VERSION ""

NS_ :

BS_ :

BU_ : Vector__XXX

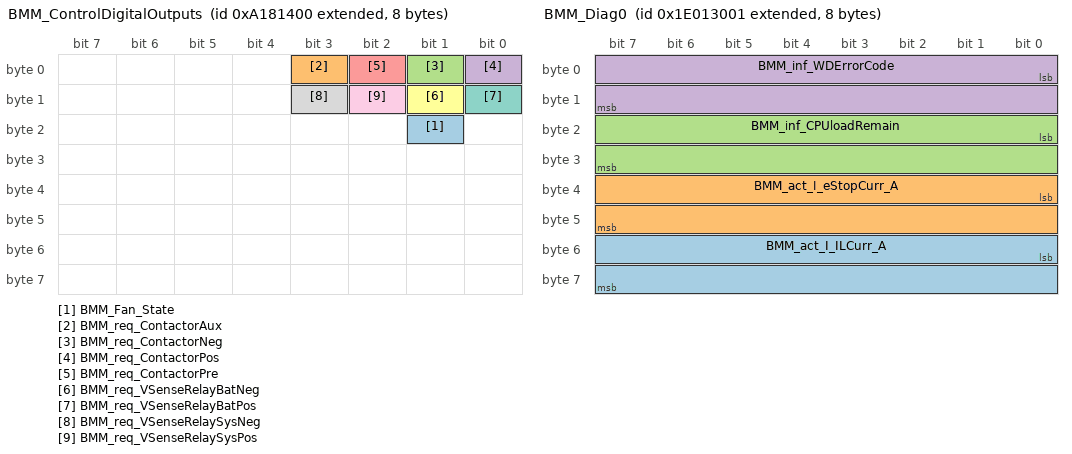
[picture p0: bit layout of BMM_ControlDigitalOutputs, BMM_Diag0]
BO_ 2316833792 BMM_ControlDigitalOutputs: 8 Vector__XXX
  SG_ BMM_Fan_State : 17|1@1+ (1,0) [0|1] "" Vector__XXX
  SG_ BMM_req_ContactorAux : 3|1@1+ (1,0) [0|1] "" Vector__XXX
  SG_ BMM_req_ContactorNeg : 1|1@1+ (1,0) [0|1] "" Vector__XXX
  SG_ BMM_req_ContactorPos : 0|1@1+ (1,0) [0|1] "" Vector__XXX
  SG_ BMM_req_ContactorPre : 2|1@1+ (1,0) [0|1] "" Vector__XXX
  SG_ BMM_req_VSenseRelayBatNeg : 9|1@1+ (1,0) [0|1] "" Vector__XXX
  SG_ BMM_req_VSenseRelayBatPos : 8|1@1+ (1,0) [0|1] "" Vector__XXX
  SG_ BMM_req_VSenseRelaySysNeg : 11|1@1+ (1,0) [0|1] "" Vector__XXX
  SG_ BMM_req_VSenseRelaySysPos : 10|1@1+ (1,0) [0|1] "" Vector__XXX

BO_ 2650877953 BMM_Diag0: 8 Vector__XXX
  SG_ BMM_act_I_ILCurr_A : 48|16@1+ (1,0) [0|65535] "" Vector__XXX
  SG_ BMM_act_I_eStopCurr_A : 32|16@1+ (1,0) [0|65535] "" Vector__XXX
  SG_ BMM_inf_CPUloadRemain : 16|16@1+ (1,0) [0|65535] "" Vector__XXX
  SG_ BMM_inf_WDErrorCode : 0|16@1+ (1,0) [0|65535] "" Vector__XXX

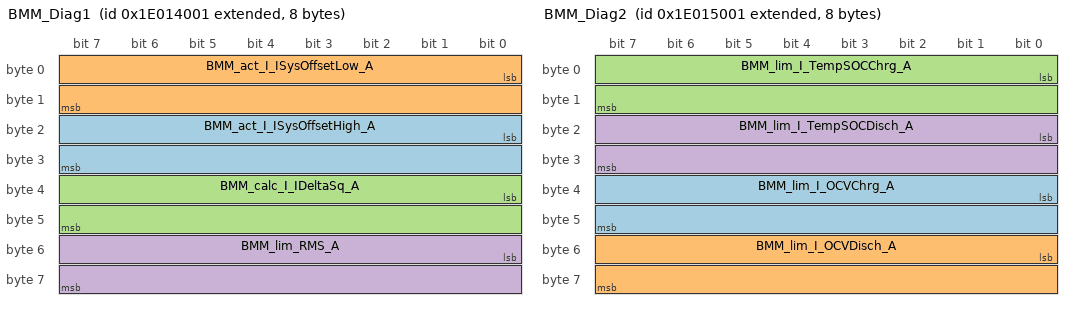
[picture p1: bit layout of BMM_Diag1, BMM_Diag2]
BO_ 2650882049 BMM_Diag1: 8 Vector__XXX
  SG_ BMM_act_I_ISysOffsetHigh_A : 16|16@1+ (0.10000000000000000555,0) [0|6553.5] "" Vector__XXX
  SG_ BMM_act_I_ISysOffsetLow_A : 0|16@1+ (0.10000000000000000555,0) [0|6553.5] "" Vector__XXX
  SG_ BMM_calc_I_IDeltaSq_A : 32|16@1+ (0.10000000000000000555,0) [0|6553.5] "" Vector__XXX
  SG_ BMM_lim_RMS_A : 48|16@1+ (0.10000000000000000555,0) [0|6553.5] "" Vector__XXX

BO_ 2650886145 BMM_Diag2: 8 Vector__XXX
  SG_ BMM_lim_I_OCVChrg_A : 32|16@1+ (0.10000000000000000555,0) [0|6553.5] "" Vector__XXX
  SG_ BMM_lim_I_OCVDisch_A : 48|16@1+ (0.10000000000000000555,0) [0|6553.5] "" Vector__XXX
  SG_ BMM_lim_I_TempSOCChrg_A : 0|16@1+ (0.10000000000000000555,0) [0|6553.5] "" Vector__XXX
  SG_ BMM_lim_I_TempSOCDisch_A : 16|16@1+ (0.10000000000000000555,0) [0|6553.5] "" Vector__XXX

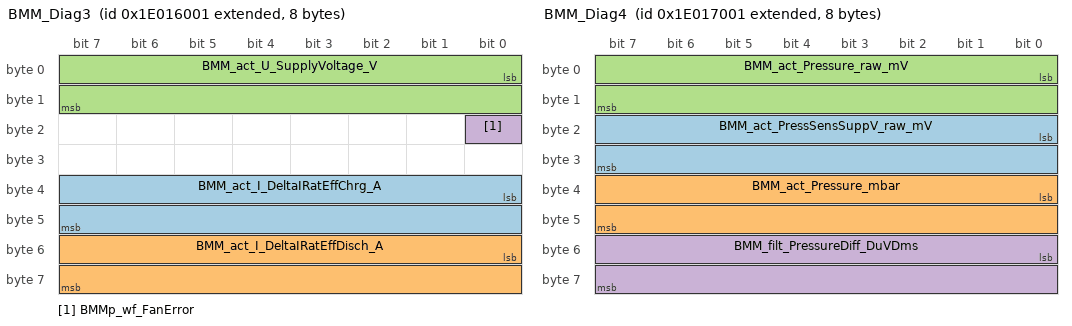
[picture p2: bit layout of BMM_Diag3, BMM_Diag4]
BO_ 2650890241 BMM_Diag3: 8 Vector__XXX
  SG_ BMM_act_I_DeltaIRatEffChrg_A : 32|16@1+ (1,0) [0|65535] "" Vector__XXX
  SG_ BMM_act_I_DeltaIRatEffDisch_A : 48|16@1+ (1,0) [0|65535] "" Vector__XXX
  SG_ BMM_act_U_SupplyVoltage_V : 0|16@1+ (1,0) [0|65535] "" Vector__XXX
  SG_ BMMp_wf_FanError : 16|1@1+ (1,0) [0|1] "" Vector__XXX

BO_ 2650894337 BMM_Diag4: 8 Vector__XXX
  SG_ BMM_act_PressSensSuppV_raw_mV : 16|16@1+ (0.10000000000000000555,0) [0|6553.5] "mV" Vector__XXX
  SG_ BMM_act_Pressure_mbar : 32|16@1+ (1,0) [0|65535] "mbar" Vector__XXX
  SG_ BMM_act_Pressure_raw_mV : 0|16@1+ (0.10000000000000000555,0) [0|6553.5] "mV" Vector__XXX
  SG_ BMM_filt_PressureDiff_DuVDms : 48|16@1- (1,0) [-32768|32767] "uV/ms" Vector__XXX

BO_ 2650898433 BMM_Diag5: 8 Vector__XXX
  SG_ BMM_act_U_KL30SafeVolt_V : 0|16@1+ (0.10000000000000000555,0) [0|6553.5] "V" Vector__XXX

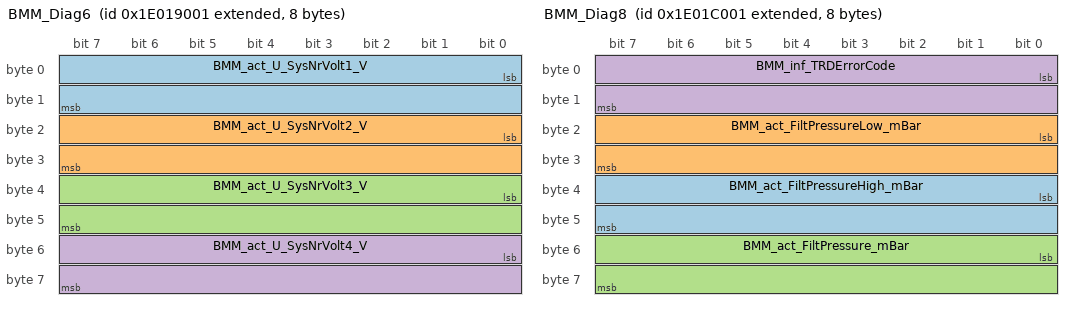
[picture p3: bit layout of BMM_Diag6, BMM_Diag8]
BO_ 2650902529 BMM_Diag6: 8 Vector__XXX
  SG_ BMM_act_U_SysNrVolt1_V : 0|16@1+ (0.10000000000000000555,0) [0|6553.5] "V" Vector__XXX
  SG_ BMM_act_U_SysNrVolt2_V : 16|16@1+ (0.10000000000000000555,0) [0|6553.5] "V" Vector__XXX
  SG_ BMM_act_U_SysNrVolt3_V : 32|16@1+ (0.10000000000000000555,0) [0|6553.5] "V" Vector__XXX
  SG_ BMM_act_U_SysNrVolt4_V : 48|16@1+ (0.10000000000000000555,0) [0|6553.5] "V" Vector__XXX

BO_ 2650906625 BMM_Diag7: 8 Vector__XXX
  SG_ BMM_inf_Average_Core_Load : 0|16@1+ (0.10000000000000000555,0) [0|6553.5] "%" Vector__XXX
  SG_ BMM_inf_Max_Core_Load : 16|16@1+ (0.10000000000000000555,0) [0|6553.5] "%" Vector__XXX

BO_ 2650914817 BMM_Diag8: 8 Vector__XXX
  SG_ BMM_act_FiltPressureHigh_mBar : 32|16@1- (0.10000000000000000555,0) [-3276.8000000000001819|3276.6999999999998181] "mbar" Vector__XXX
  SG_ BMM_act_FiltPressureLow_mBar : 16|16@1- (0.10000000000000000555,0) [-3276.8000000000001819|3276.6999999999998181] "mbar" Vector__XXX
  SG_ BMM_act_FiltPressure_mBar : 48|16@1- (0.10000000000000000555,0) [-3276.8000000000001819|3276.6999999999998181] "mbar" Vector__XXX
  SG_ BMM_inf_TRDErrorCode : 0|16@1+ (1,0) [0|65535] "" Vector__XXX

BO_ 2181563392 BMM_SCUSyncMsg: 0 Vector__XXX

BO_ 2650828801 BMMp_AlarmFlag: 8 Vector__XXX
  SG_ BMMp_af_AfterrunTest : 40|1@1+ (1,0) [0|1] "" Vector__XXX
  SG_ BMMp_af_BMMBattCom : 29|1@1+ (1,0) [0|1] "" Vector__XXX
  SG_ BMMp_af_BoardTemp : 61|1@1+ (1,0) [0|1] "" Vector__XXX
  SG_ BMMp_af_CPUSupplyWarning : 56|1@1+ (1,0) [0|1] "" Vector__XXX
  SG_ BMMp_af_CellTempChargMax : 16|1@1+ (1,0) [0|1] "" Vector__XXX
  SG_ BMMp_af_CellTempChargMin : 17|1@1+ (1,0) [0|1] "" Vector__XXX
  SG_ BMMp_af_CellTempDischMax : 18|1@1+ (1,0) [0|1] "" Vector__XXX
  SG_ BMMp_af_CellTempDischMin : 19|1@1+ (1,0) [0|1] "" Vector__XXX
  SG_ BMMp_af_CellTempUnbalance : 37|1@1+ (1,0) [0|1] "" Vector__XXX
  SG_ BMMp_af_CellVoltUnbalance : 36|1@1+ (1,0) [0|1] "" Vector__XXX
  SG_ BMMp_af_CellVoltageMax : 0|1@1+ (1,0) [0|1] "" Vector__XXX
  SG_ BMMp_af_CellVoltageMin : 1|1@1+ (1,0) [0|1] "" Vector__XXX
  SG_ BMMp_af_ContDam : 51|1@1+ (1,0) [0|1] "" Vector__XXX
  SG_ BMMp_af_ContactorDropOut : 60|1@1+ (1,0) [0|1] "" Vector__XXX
  SG_ BMMp_af_ContactorNegStuck : 10|1@1+ (1,0) [0|1] "" Vector__XXX
  SG_ BMMp_af_ContactorPosStuck : 11|1@1+ (1,0) [0|1] "" Vector__XXX
  SG_ BMMp_af_ContactorWrongState : 49|1@1+ (1,0) [0|1] "" Vector__XXX
  SG_ BMMp_af_CrossCheck : 41|1@1+ (1,0) [0|1] "" Vector__XXX
  SG_ BMMp_af_CurrSens : 50|1@1+ (1,0) [0|1] "" Vector__XXX
  SG_ BMMp_af_DeepDischProt : 32|1@1+ (1,0) [0|1] "" Vector__XXX
  SG_ BMMp_af_Dew_Sensor : 59|1@1+ (1,0) [0|1] "" Vector__XXX
  SG_ BMMp_af_ExtCommunicationTout : 34|1@1+ (1,0) [0|1] "" Vector__XXX
  SG_ BMMp_af_FlashEEPROM : 47|1@1+ (1,0) [0|1] "" Vector__XXX
  SG_ BMMp_af_HVCurrLoopMax : 22|1@1+ (1,0) [0|1] "" Vector__XXX
  SG_ BMMp_af_HVCurrLoopMin : 23|1@1+ (1,0) [0|1] "" Vector__XXX
  SG_ BMMp_af_InvalidData : 48|1@1+ (1,0) [0|1] "" Vector__XXX
  SG_ BMMp_af_IsoFaultBattNeg : 8|1@1+ (1,0) [0|1] "" Vector__XXX
  SG_ BMMp_af_IsoFaultBattPos : 9|1@1+ (1,0) [0|1] "" Vector__XXX
  SG_ BMMp_af_KL30SafeMax : 54|1@1+ (1,0) [0|1] "" Vector__XXX
  SG_ BMMp_af_KL30SafeMin : 55|1@1+ (1,0) [0|1] "" Vector__XXX
  SG_ BMMp_af_KL30SafeOff : 58|1@1+ (1,0) [0|1] "" Vector__XXX
  SG_ BMMp_af_LTCError : 39|1@1+ (1,0) [0|1] "" Vector__XXX
  SG_ BMMp_af_LVSupplyMax : 12|1@1+ (1,0) [0|1] "" Vector__XXX
  SG_ BMMp_af_LVSupplyMin : 13|1@1+ (1,0) [0|1] "" Vector__XXX
  SG_ BMMp_af_ModVoltageRefMax : 6|1@1+ (1,0) [0|1] "" Vector__XXX
  SG_ BMMp_af_ModVoltageSum : 5|1@1+ (1,0) [0|1] "" Vector__XXX
  SG_ BMMp_af_Mod_Voltage_Ref_Min : 7|1@1+ (1,0) [0|1] "" Vector__XXX
  SG_ BMMp_af_NoAfterrunTest : 35|1@1+ (1,0) [0|1] "" Vector__XXX
  SG_ BMMp_af_PowerProtectionWarning : 57|1@1+ (1,0) [0|1] "" Vector__XXX
  SG_ BMMp_af_ProgProcess : 44|1@1+ (1,0) [0|1] "" Vector__XXX
  SG_ BMMp_af_RAM : 45|1@1+ (1,0) [0|1] "" Vector__XXX
  SG_ BMMp_af_ROM : 46|1@1+ (1,0) [0|1] "" Vector__XXX
  SG_ BMMp_af_RefVoltErrorMax : 52|1@1+ (1,0) [0|1] "" Vector__XXX
  SG_ BMMp_af_RefVoltErrorMin : 53|1@1+ (1,0) [0|1] "" Vector__XXX
  SG_ BMMp_af_SCUConfig : 31|1@1+ (1,0) [0|1] "" Vector__XXX
  SG_ BMMp_af_SCUError : 63|1@1+ (1,0) [0|1] "" Vector__XXX
  SG_ BMMp_af_StuckAtTemp : 42|1@1+ (1,0) [0|1] "" Vector__XXX
  SG_ BMMp_af_StuckAtVolt : 43|1@1+ (1,0) [0|1] "" Vector__XXX
  SG_ BMMp_af_SysCurCha : 20|1@1+ (1,0) [0|1] "" Vector__XXX
  SG_ BMMp_af_SysCurDis : 21|1@1+ (1,0) [0|1] "" Vector__XXX
  SG_ BMMp_af_SysCurLimitCha : 26|1@1+ (1,0) [0|1] "" Vector__XXX
  SG_ BMMp_af_SysCurLimitDis : 27|1@1+ (1,0) [0|1] "" Vector__XXX
  SG_ BMMp_af_SysInitTimeout : 30|1@1+ (1,0) [0|1] "" Vector__XXX
  SG_ BMMp_af_SysPrechargeFailed : 28|1@1+ (1,0) [0|1] "" Vector__XXX
  SG_ BMMp_af_SysVoltageMax : 2|1@1+ (1,0) [0|1] "" Vector__XXX
  SG_ BMMp_af_SysVoltageMin : 3|1@1+ (1,0) [0|1] "" Vector__XXX
  SG_ BMMp_af_SysVoltageSum : 4|1@1+ (1,0) [0|1] "" Vector__XXX
  SG_ BMMp_af_TerminalTempMax : 14|1@1+ (1,0) [0|1] "" Vector__XXX
  SG_ BMMp_af_TerminalTempMin : 15|1@1+ (1,0) [0|1] "" Vector__XXX
  SG_ BMMp_af_TerminalTempUnbalance : 38|1@1+ (1,0) [0|1] "" Vector__XXX
  SG_ BMMp_af_WDReset : 33|1@1+ (1,0) [0|1] "" Vector__XXX
  SG_ BMMp_af_eStopCurrLoopMax : 24|1@1+ (1,0) [0|1] "" Vector__XXX
  SG_ BMMp_af_eStopCurrLoopMin : 25|1@1+ (1,0) [0|1] "" Vector__XXX

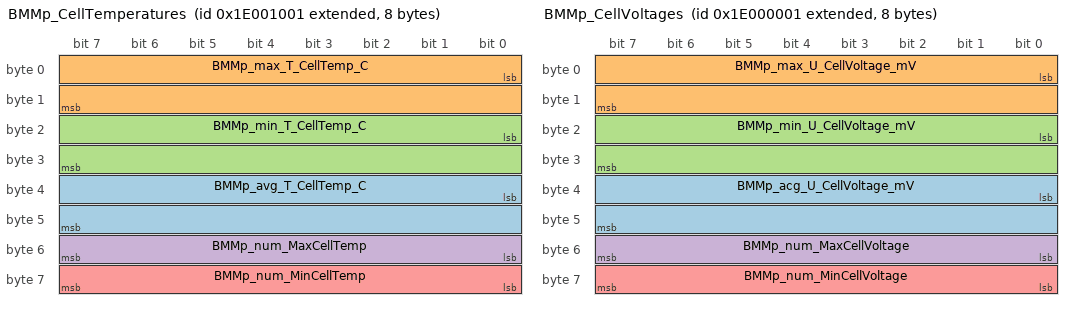
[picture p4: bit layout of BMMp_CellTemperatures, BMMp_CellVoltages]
BO_ 2650804225 BMMp_CellTemperatures: 8 Vector__XXX
  SG_ BMMp_avg_T_CellTemp_C : 32|16@1- (0.10000000000000000555,0) [-3276.8000000000001819|3276.6999999999998181] "°C" Vector__XXX
  SG_ BMMp_max_T_CellTemp_C : 0|16@1- (0.10000000000000000555,0) [-3276.8000000000001819|3276.6999999999998181] "°C" Vector__XXX
  SG_ BMMp_min_T_CellTemp_C : 16|16@1- (0.10000000000000000555,0) [-3276.8000000000001819|3276.6999999999998181] "°C" Vector__XXX
  SG_ BMMp_num_MaxCellTemp : 48|8@1+ (1,0) [0|255] "-" Vector__XXX
  SG_ BMMp_num_MinCellTemp : 56|8@1+ (1,0) [0|255] "-" Vector__XXX

BO_ 2650800129 BMMp_CellVoltages: 8 Vector__XXX
  SG_ BMMp_acg_U_CellVoltage_mV : 32|16@1+ (1,0) [0|65535] "mV" Vector__XXX
  SG_ BMMp_max_U_CellVoltage_mV : 0|16@1+ (1,0) [0|65535] "mV" Vector__XXX
  SG_ BMMp_min_U_CellVoltage_mV : 16|16@1+ (1,0) [0|65535] "mV" Vector__XXX
  SG_ BMMp_num_MaxCellVoltage : 48|8@1+ (1,0) [0|255] "-" Vector__XXX
  SG_ BMMp_num_MinCellVoltage : 56|8@1+ (1,0) [0|255] "-" Vector__XXX

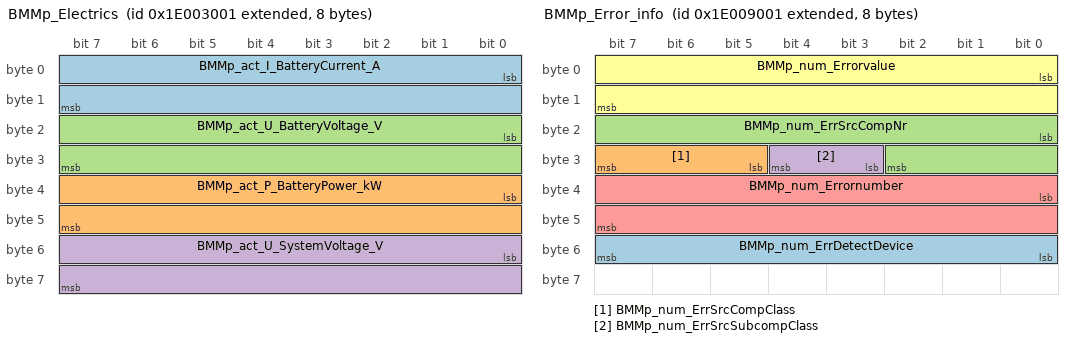
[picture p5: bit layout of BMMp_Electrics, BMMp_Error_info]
BO_ 2650812417 BMMp_Electrics: 8 Vector__XXX
  SG_ BMMp_act_I_BatteryCurrent_A : 0|16@1- (0.10000000000000000555,0) [-3276.8000000000001819|3276.6999999999998181] "A" Vector__XXX
  SG_ BMMp_act_P_BatteryPower_kW : 32|16@1- (0.10000000000000000555,0) [-3276.8000000000001819|3276.6999999999998181] "kW" Vector__XXX
  SG_ BMMp_act_U_BatteryVoltage_V : 16|16@1- (0.10000000000000000555,0) [-3276.8000000000001819|3276.6999999999998181] "V" Vector__XXX
  SG_ BMMp_act_U_SystemVoltage_V : 48|16@1- (0.10000000000000000555,0) [-3276.8000000000001819|3276.6999999999998181] "V" Vector__XXX

BO_ 2650824705 BMMp_ErrorFlag: 8 Vector__XXX
  SG_ BMMp_ef_AfterrunTest : 40|1@1+ (1,0) [0|1] "" Vector__XXX
  SG_ BMMp_ef_BMMBattCom : 29|1@1+ (1,0) [0|1] "" Vector__XXX
  SG_ BMMp_ef_BoardTemp : 61|1@1+ (1,0) [0|1] "" Vector__XXX
  SG_ BMMp_ef_CPUSupplyWarning : 56|1@1+ (1,0) [0|1] "" Vector__XXX
  SG_ BMMp_ef_CellTempChargMax : 16|1@1+ (1,0) [0|1] "" Vector__XXX
  SG_ BMMp_ef_CellTempChargMin : 17|1@1+ (1,0) [0|1] "" Vector__XXX
  SG_ BMMp_ef_CellTempDischMax : 18|1@1+ (1,0) [0|1] "" Vector__XXX
  SG_ BMMp_ef_CellTempDischMin : 19|1@1+ (1,0) [0|1] "" Vector__XXX
  SG_ BMMp_ef_CellTempUnbalance : 37|1@1+ (1,0) [0|1] "" Vector__XXX
  SG_ BMMp_ef_CellVoltUnbalance : 36|1@1+ (1,0) [0|1] "" Vector__XXX
  SG_ BMMp_ef_CellVoltageMax : 0|1@1+ (1,0) [0|1] "" Vector__XXX
  SG_ BMMp_ef_CellVoltageMin : 1|1@1+ (1,0) [0|1] "" Vector__XXX
  SG_ BMMp_ef_ContDam : 51|1@1+ (1,0) [0|1] "" Vector__XXX
  SG_ BMMp_ef_ContactorDropOut : 60|1@1+ (1,0) [0|1] "" Vector__XXX
  SG_ BMMp_ef_ContactorNegStuck : 10|1@1+ (1,0) [0|1] "" Vector__XXX
  SG_ BMMp_ef_ContactorPosStuck : 11|1@1+ (1,0) [0|1] "" Vector__XXX
  SG_ BMMp_ef_ContactorWrongState : 49|1@1+ (1,0) [0|1] "" Vector__XXX
  SG_ BMMp_ef_CrossCheck : 41|1@1+ (1,0) [0|1] "" Vector__XXX
  SG_ BMMp_ef_CurrSens : 50|1@1+ (1,0) [0|1] "" Vector__XXX
  SG_ BMMp_ef_DeepDischProt : 32|1@1+ (1,0) [0|1] "" Vector__XXX
  SG_ BMMp_ef_Dew_Sensor : 59|1@1+ (1,0) [0|1] "" Vector__XXX
  SG_ BMMp_ef_ExtCommunicationTout : 34|1@1+ (1,0) [0|1] "" Vector__XXX
  SG_ BMMp_ef_FlashEEPROM : 47|1@1+ (1,0) [0|1] "" Vector__XXX
  SG_ BMMp_ef_HVCurrLoopMax : 22|1@1+ (1,0) [0|1] "" Vector__XXX
  SG_ BMMp_ef_HVCurrLoopMin : 23|1@1+ (1,0) [0|1] "" Vector__XXX
  SG_ BMMp_ef_InvalidData : 48|1@1+ (1,0) [0|1] "" Vector__XXX
  SG_ BMMp_ef_IsoFaultBattNeg : 8|1@1+ (1,0) [0|1] "" Vector__XXX
  SG_ BMMp_ef_IsoFaultBattPos : 9|1@1+ (1,0) [0|1] "" Vector__XXX
  SG_ BMMp_ef_KL30SafeMax : 54|1@1+ (1,0) [0|1] "" Vector__XXX
  SG_ BMMp_ef_KL30SafeMin : 55|1@1+ (1,0) [0|1] "" Vector__XXX
  SG_ BMMp_ef_KL30SafeOff : 58|1@1+ (1,0) [0|1] "" Vector__XXX
  SG_ BMMp_ef_LTCError : 39|1@1+ (1,0) [0|1] "" Vector__XXX
  SG_ BMMp_ef_LVSupplyMax : 12|1@1+ (1,0) [0|1] "" Vector__XXX
  SG_ BMMp_ef_LVSupplyMin : 13|1@1+ (1,0) [0|1] "" Vector__XXX
  SG_ BMMp_ef_ModVoltageRefMax : 6|1@1+ (1,0) [0|1] "" Vector__XXX
  SG_ BMMp_ef_ModVoltageSum : 5|1@1+ (1,0) [0|1] "" Vector__XXX
  SG_ BMMp_ef_Mod_Voltage_Ref_Min : 7|1@1+ (1,0) [0|1] "" Vector__XXX
  SG_ BMMp_ef_NoAfterrunTest : 35|1@1+ (1,0) [0|1] "" Vector__XXX
  SG_ BMMp_ef_PowerProtectionWarning : 57|1@1+ (1,0) [0|1] "" Vector__XXX
  SG_ BMMp_ef_ProgProcess : 44|1@1+ (1,0) [0|1] "" Vector__XXX
  SG_ BMMp_ef_RAM : 45|1@1+ (1,0) [0|1] "" Vector__XXX
  SG_ BMMp_ef_ROM : 46|1@1+ (1,0) [0|1] "" Vector__XXX
  SG_ BMMp_ef_RefVoltErrorMax : 52|1@1+ (1,0) [0|1] "" Vector__XXX
  SG_ BMMp_ef_RefVoltErrorMin : 53|1@1+ (1,0) [0|1] "" Vector__XXX
  SG_ BMMp_ef_SCUConfig : 31|1@1+ (1,0) [0|1] "" Vector__XXX
  SG_ BMMp_ef_SCUError : 63|1@1+ (1,0) [0|1] "" Vector__XXX
  SG_ BMMp_ef_StuckAtTemp : 42|1@1+ (1,0) [0|1] "" Vector__XXX
  SG_ BMMp_ef_StuckAtVolt : 43|1@1+ (1,0) [0|1] "" Vector__XXX
  SG_ BMMp_ef_SysCurCha : 20|1@1+ (1,0) [0|1] "" Vector__XXX
  SG_ BMMp_ef_SysCurDis : 21|1@1+ (1,0) [0|1] "" Vector__XXX
  SG_ BMMp_ef_SysCurLimitCha : 26|1@1+ (1,0) [0|1] "" Vector__XXX
  SG_ BMMp_ef_SysCurLimitDis : 27|1@1+ (1,0) [0|1] "" Vector__XXX
  SG_ BMMp_ef_SysInitTimeout : 30|1@1+ (1,0) [0|1] "" Vector__XXX
  SG_ BMMp_ef_SysPrechargeFailed : 28|1@1+ (1,0) [0|1] "" Vector__XXX
  SG_ BMMp_ef_SysVoltageMax : 2|1@1+ (1,0) [0|1] "" Vector__XXX
  SG_ BMMp_ef_SysVoltageMin : 3|1@1+ (1,0) [0|1] "" Vector__XXX
  SG_ BMMp_ef_SysVoltageSum : 4|1@1+ (1,0) [0|1] "" Vector__XXX
  SG_ BMMp_ef_TerminalTempMax : 14|1@1+ (1,0) [0|1] "" Vector__XXX
  SG_ BMMp_ef_TerminalTempMin : 15|1@1+ (1,0) [0|1] "" Vector__XXX
  SG_ BMMp_ef_TerminalTempUnbalance : 38|1@1+ (1,0) [0|1] "" Vector__XXX
  SG_ BMMp_ef_WDReset : 33|1@1+ (1,0) [0|1] "" Vector__XXX
  SG_ BMMp_ef_eStopCurrLoopMax : 24|1@1+ (1,0) [0|1] "" Vector__XXX
  SG_ BMMp_ef_eStopCurrLoopMin : 25|1@1+ (1,0) [0|1] "" Vector__XXX

BO_ 2650836993 BMMp_Error_info: 8 Vector__XXX
  SG_ BMMp_num_ErrDetectDevice : 48|8@1+ (1,0) [0|255] "" Vector__XXX
  SG_ BMMp_num_ErrSrcCompClass : 29|3@1+ (1,0) [0|7] "" Vector__XXX
  SG_ BMMp_num_ErrSrcCompNr : 16|11@1+ (1,0) [0|2047] "" Vector__XXX
  SG_ BMMp_num_ErrSrcSubcompClass : 27|2@1+ (1,0) [0|3] "" Vector__XXX
  SG_ BMMp_num_Errornumber : 32|16@1+ (1,0) [0|65535] "" Vector__XXX
  SG_ BMMp_num_Errorvalue : 0|16@1- (1,0) [-32768|32767] "" Vector__XXX

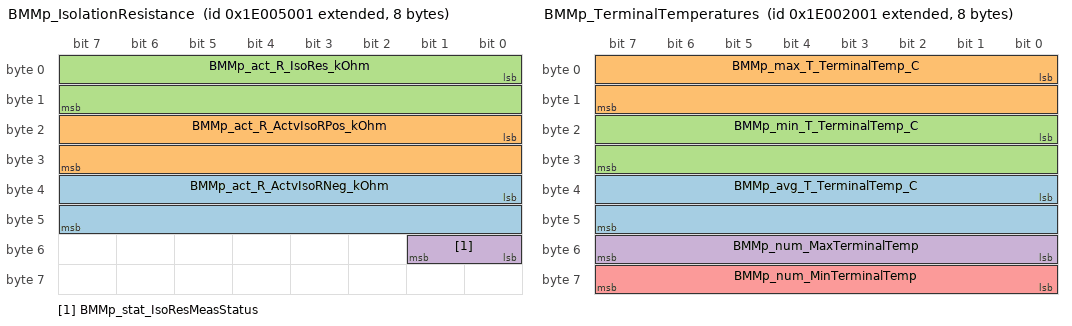
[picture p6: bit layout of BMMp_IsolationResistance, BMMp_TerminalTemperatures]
BO_ 2650820609 BMMp_IsolationResistance: 8 Vector__XXX
  SG_ BMMp_act_R_ActvIsoRNeg_kOhm : 32|16@1+ (1,0) [0|65535] "kOhm" Vector__XXX
  SG_ BMMp_act_R_ActvIsoRPos_kOhm : 16|16@1+ (1,0) [0|65535] "kOhm" Vector__XXX
  SG_ BMMp_act_R_IsoRes_kOhm : 0|16@1+ (1,0) [0|65535] "kOhm" Vector__XXX
  SG_ BMMp_stat_IsoResMeasStatus : 48|2@1+ (1,0) [0|3] "" Vector__XXX

BO_ 2650857473 BMMp_SOH: 8 Vector__XXX
  SG_ BMMp_calc_SOHcapacity_pct : 0|16@1+ (0.10000000000000000555,0) [0|6553.5] "%" Vector__XXX
  SG_ BMMp_calc_SOHimpedance_pct : 16|16@1+ (0.10000000000000000555,0) [0|6553.5] "%" Vector__XXX

BO_ 2650816513 BMMp_State: 8 Vector__XXX
  SG_ BMMp_cnt_AliveCounter : 48|8@1+ (1,0) [0|255] "" Vector__XXX
  SG_ BMMp_cnt_MirroredAliveCounter : 56|8@1+ (1,0) [0|255] "" Vector__XXX
  SG_ BMMp_flag_Alarm : 33|1@1+ (1,0) [0|1] "" Vector__XXX
  SG_ BMMp_flag_AuxCont : 34|1@1+ (1,0) [0|1] "" Vector__XXX
  SG_ BMMp_flag_Charge : 9|1@1+ (1,0) [0|1] "" Vector__XXX
  SG_ BMMp_flag_ChargeComplete : 22|1@1+ (1,0) [0|1] "" Vector__XXX
  SG_ BMMp_flag_ContactorHVNeg : 20|1@1+ (1,0) [0|1] "" Vector__XXX
  SG_ BMMp_flag_ContactorHVPos : 19|1@1+ (1,0) [0|1] "" Vector__XXX
  SG_ BMMp_flag_ContactorPrecha : 21|1@1+ (1,0) [0|1] "" Vector__XXX
  SG_ BMMp_flag_Drive : 8|1@1+ (1,0) [0|1] "" Vector__XXX
  SG_ BMMp_flag_ExternalSdwnRq : 23|1@1+ (1,0) [0|1] "" Vector__XXX
  SG_ BMMp_flag_FireRisk : 39|1@1+ (1,0) [0|1] "" Vector__XXX
  SG_ BMMp_flag_HVILState : 30|1@1+ (1,0) [0|1] "" Vector__XXX
  SG_ BMMp_flag_InternalKL30Safe : 24|1@1+ (1,0) [0|1] "" Vector__XXX
  SG_ BMMp_flag_IsoDisable : 17|1@1+ (1,0) [0|1] "" Vector__XXX
  SG_ BMMp_flag_Wake : 16|1@1+ (1,0) [0|1] "" Vector__XXX
  SG_ BMMp_flag_Warning : 32|1@1+ (1,0) [0|1] "" Vector__XXX
  SG_ BMMp_flag_eStopLoopClosed : 31|1@1+ (1,0) [0|1] "" Vector__XXX
  SG_ BMMp_stat_Error : 6|1@1+ (1,0) [0|1] "" Vector__XXX
  SG_ BMMp_stat_Init : 0|1@1+ (1,0) [0|1] "" Vector__XXX
  SG_ BMMp_stat_Operational : 3|1@1+ (1,0) [0|1] "" Vector__XXX
  SG_ BMMp_stat_Precharge : 2|1@1+ (1,0) [0|1] "" Vector__XXX
  SG_ BMMp_stat_Standby : 1|1@1+ (1,0) [0|1] "" Vector__XXX

BO_ 2650808321 BMMp_TerminalTemperatures: 8 Vector__XXX
  SG_ BMMp_avg_T_TerminalTemp_C : 32|16@1- (0.10000000000000000555,0) [-3276.8000000000001819|3276.6999999999998181] "°C" Vector__XXX
  SG_ BMMp_max_T_TerminalTemp_C : 0|16@1- (0.10000000000000000555,0) [-3276.8000000000001819|3276.6999999999998181] "°C" Vector__XXX
  SG_ BMMp_min_T_TerminalTemp_C : 16|16@1- (0.10000000000000000555,0) [-3276.8000000000001819|3276.6999999999998181] "°C" Vector__XXX
  SG_ BMMp_num_MaxTerminalTemp : 48|8@1+ (1,0) [0|255] "-" Vector__XXX
  SG_ BMMp_num_MinTerminalTemp : 56|8@1+ (1,0) [0|255] "-" Vector__XXX

BO_ 2650832897 BMMp_WarningFlag: 8 Vector__XXX
  SG_ BMMp_wf_AfterrunTest : 40|1@1+ (1,0) [0|1] "" Vector__XXX
  SG_ BMMp_wf_BMMBattCom : 29|1@1+ (1,0) [0|1] "" Vector__XXX
  SG_ BMMp_wf_BoardTemp : 61|1@1+ (1,0) [0|1] "" Vector__XXX
  SG_ BMMp_wf_CPUSupplyWarning : 56|1@1+ (1,0) [0|1] "" Vector__XXX
  SG_ BMMp_wf_CellTempChargMax : 16|1@1+ (1,0) [0|1] "" Vector__XXX
  SG_ BMMp_wf_CellTempChargMin : 17|1@1+ (1,0) [0|1] "" Vector__XXX
  SG_ BMMp_wf_CellTempDischMax : 18|1@1+ (1,0) [0|1] "" Vector__XXX
  SG_ BMMp_wf_CellTempDischMin : 19|1@1+ (1,0) [0|1] "" Vector__XXX
  SG_ BMMp_wf_CellTempUnbalance : 37|1@1+ (1,0) [0|1] "" Vector__XXX
  SG_ BMMp_wf_CellVoltUnbalance : 36|1@1+ (1,0) [0|1] "" Vector__XXX
  SG_ BMMp_wf_CellVoltageMax : 0|1@1+ (1,0) [0|1] "" Vector__XXX
  SG_ BMMp_wf_CellVoltageMin : 1|1@1+ (1,0) [0|1] "" Vector__XXX
  SG_ BMMp_wf_ContDam : 51|1@1+ (1,0) [0|1] "" Vector__XXX
  SG_ BMMp_wf_ContactorDropOut : 60|1@1+ (1,0) [0|1] "" Vector__XXX
  SG_ BMMp_wf_ContactorNegStuck : 10|1@1+ (1,0) [0|1] "" Vector__XXX
  SG_ BMMp_wf_ContactorPosStuck : 11|1@1+ (1,0) [0|1] "" Vector__XXX
  SG_ BMMp_wf_ContactorWrongState : 49|1@1+ (1,0) [0|1] "" Vector__XXX
  SG_ BMMp_wf_CrossCheck : 41|1@1+ (1,0) [0|1] "" Vector__XXX
  SG_ BMMp_wf_CurrSens : 50|1@1+ (1,0) [0|1] "" Vector__XXX
  SG_ BMMp_wf_DeepDischProt : 32|1@1+ (1,0) [0|1] "" Vector__XXX
  SG_ BMMp_wf_Dew_Sensor : 59|1@1+ (1,0) [0|1] "" Vector__XXX
  SG_ BMMp_wf_ExtCommunicationTout : 34|1@1+ (1,0) [0|1] "" Vector__XXX
  SG_ BMMp_wf_FlashEEPROM : 47|1@1+ (1,0) [0|1] "" Vector__XXX
  SG_ BMMp_wf_HVCurrLoopMax : 22|1@1+ (1,0) [0|1] "" Vector__XXX
  SG_ BMMp_wf_HVCurrLoopMin : 23|1@1+ (1,0) [0|1] "" Vector__XXX
  SG_ BMMp_wf_InvalidData : 48|1@1+ (1,0) [0|1] "" Vector__XXX
  SG_ BMMp_wf_IsoFaultBattNeg : 8|1@1+ (1,0) [0|1] "" Vector__XXX
  SG_ BMMp_wf_IsoFaultBattPos : 9|1@1+ (1,0) [0|1] "" Vector__XXX
  SG_ BMMp_wf_KL30SafeMax : 54|1@1+ (1,0) [0|1] "" Vector__XXX
  SG_ BMMp_wf_KL30SafeMin : 55|1@1+ (1,0) [0|1] "" Vector__XXX
  SG_ BMMp_wf_KL30SafeOff : 58|1@1+ (1,0) [0|1] "" Vector__XXX
  SG_ BMMp_wf_LTCError : 39|1@1+ (1,0) [0|1] "" Vector__XXX
  SG_ BMMp_wf_LVSupplyMax : 12|1@1+ (1,0) [0|1] "" Vector__XXX
  SG_ BMMp_wf_LVSupplyMin : 13|1@1+ (1,0) [0|1] "" Vector__XXX
  SG_ BMMp_wf_ModVoltageRefMax : 6|1@1+ (1,0) [0|1] "" Vector__XXX
  SG_ BMMp_wf_ModVoltageSum : 5|1@1+ (1,0) [0|1] "" Vector__XXX
  SG_ BMMp_wf_Mod_Voltage_Ref_Min : 7|1@1+ (1,0) [0|1] "" Vector__XXX
  SG_ BMMp_wf_NoAfterrunTest : 35|1@1+ (1,0) [0|1] "" Vector__XXX
  SG_ BMMp_wf_PowerProtectionWarning : 57|1@1+ (1,0) [0|1] "" Vector__XXX
  SG_ BMMp_wf_ProgProcess : 44|1@1+ (1,0) [0|1] "" Vector__XXX
  SG_ BMMp_wf_RAM : 45|1@1+ (1,0) [0|1] "" Vector__XXX
  SG_ BMMp_wf_ROM : 46|1@1+ (1,0) [0|1] "" Vector__XXX
  SG_ BMMp_wf_RefVoltErrorMax : 52|1@1+ (1,0) [0|1] "" Vector__XXX
  SG_ BMMp_wf_RefVoltErrorMin : 53|1@1+ (1,0) [0|1] "" Vector__XXX
  SG_ BMMp_wf_SCUConfig : 31|1@1+ (1,0) [0|1] "" Vector__XXX
  SG_ BMMp_wf_SCUError : 63|1@1+ (1,0) [0|1] "" Vector__XXX
  SG_ BMMp_wf_StuckAtTemp : 42|1@1+ (1,0) [0|1] "" Vector__XXX
  SG_ BMMp_wf_StuckAtVolt : 43|1@1+ (1,0) [0|1] "" Vector__XXX
  SG_ BMMp_wf_SysCurCha : 20|1@1+ (1,0) [0|1] "" Vector__XXX
  SG_ BMMp_wf_SysCurDis : 21|1@1+ (1,0) [0|1] "" Vector__XXX
  SG_ BMMp_wf_SysCurLimitCha : 26|1@1+ (1,0) [0|1] "" Vector__XXX
  SG_ BMMp_wf_SysCurLimitDis : 27|1@1+ (1,0) [0|1] "" Vector__XXX
  SG_ BMMp_wf_SysInitTimeout : 30|1@1+ (1,0) [0|1] "" Vector__XXX
  SG_ BMMp_wf_SysPrechargeFailed : 28|1@1+ (1,0) [0|1] "" Vector__XXX
  SG_ BMMp_wf_SysVoltageMax : 2|1@1+ (1,0) [0|1] "" Vector__XXX
  SG_ BMMp_wf_SysVoltageMin : 3|1@1+ (1,0) [0|1] "" Vector__XXX
  SG_ BMMp_wf_SysVoltageSum : 4|1@1+ (1,0) [0|1] "" Vector__XXX
  SG_ BMMp_wf_TerminalTempMax : 14|1@1+ (1,0) [0|1] "" Vector__XXX
  SG_ BMMp_wf_TerminalTempMin : 15|1@1+ (1,0) [0|1] "" Vector__XXX
  SG_ BMMp_wf_TerminalTempUnbalance : 38|1@1+ (1,0) [0|1] "" Vector__XXX
  SG_ BMMp_wf_WDReset : 33|1@1+ (1,0) [0|1] "" Vector__XXX
  SG_ BMMp_wf_eStopCurrLoopMax : 24|1@1+ (1,0) [0|1] "" Vector__XXX
  SG_ BMMp_wf_eStopCurrLoopMin : 25|1@1+ (1,0) [0|1] "" Vector__XXX

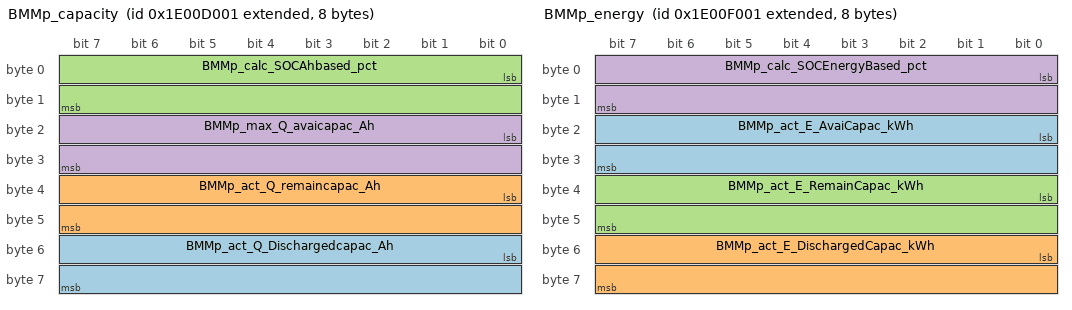
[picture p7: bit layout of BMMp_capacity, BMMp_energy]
BO_ 2650853377 BMMp_capacity: 8 Vector__XXX
  SG_ BMMp_act_Q_Dischargedcapac_Ah : 48|16@1+ (0.10000000000000000555,0) [0|6553.5] "Ah" Vector__XXX
  SG_ BMMp_act_Q_remaincapac_Ah : 32|16@1- (0.10000000000000000555,0) [-3276.8000000000001819|3276.6999999999998181] "Ah" Vector__XXX
  SG_ BMMp_calc_SOCAhbased_pct : 0|16@1+ (0.002500000000000000052,0) [0|163.83750000000000568] "%" Vector__XXX
  SG_ BMMp_max_Q_avaicapac_Ah : 16|16@1+ (0.10000000000000000555,0) [0|6553.5] "Ah" Vector__XXX

BO_ 2650861569 BMMp_energy: 8 Vector__XXX
  SG_ BMMp_act_E_AvaiCapac_kWh : 16|16@1+ (0.10000000000000000555,0) [0|6553.5] "kWh" Vector__XXX
  SG_ BMMp_act_E_DischargedCapac_kWh : 48|16@1+ (0.5,0) [0|32767.5] "kWh" Vector__XXX
  SG_ BMMp_act_E_RemainCapac_kWh : 32|16@1- (0.10000000000000000555,0) [-3276.8000000000001819|3276.6999999999998181] "kWh" Vector__XXX
  SG_ BMMp_calc_SOCEnergyBased_pct : 0|16@1+ (0.002500000000000000052,0) [0|163.83750000000000568] "%" Vector__XXX

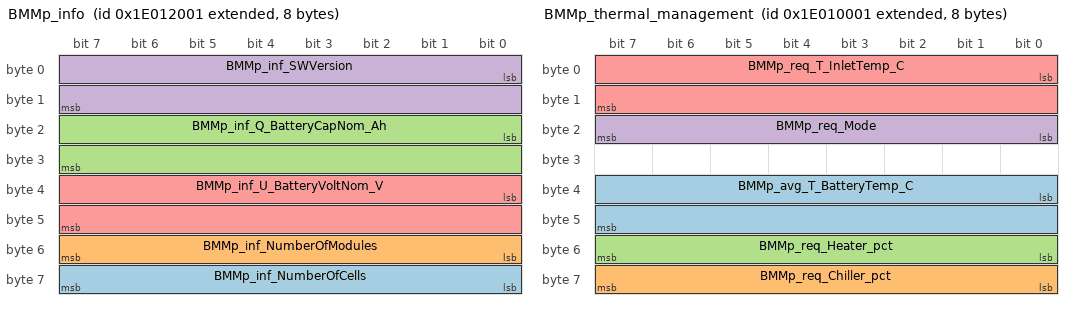
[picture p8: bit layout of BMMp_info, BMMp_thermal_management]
BO_ 2650873857 BMMp_info: 8 Vector__XXX
  SG_ BMMp_inf_NumberOfCells : 56|8@1+ (1,0) [0|255] "-" Vector__XXX
  SG_ BMMp_inf_NumberOfModules : 48|8@1+ (1,0) [0|255] "-" Vector__XXX
  SG_ BMMp_inf_Q_BatteryCapNom_Ah : 16|16@1+ (0.10000000000000000555,0) [0|6553.5] "Ah" Vector__XXX
  SG_ BMMp_inf_SWVersion : 0|16@1+ (1,0) [0|65535] "" Vector__XXX
  SG_ BMMp_inf_U_BatteryVoltNom_V : 32|16@1+ (0.10000000000000000555,0) [0|6553.5] "V" Vector__XXX

BO_ 2650869761 BMMp_info_thermal: 8 Vector__XXX
  SG_ BMMp_act_T_CoolantTempIn_C : 16|16@1- (0.10000000000000000555,0) [-3276.8000000000001819|3276.6999999999998181] "°C" Vector__XXX
  SG_ BMMp_act_T_CoolantTempOut_C : 32|16@1- (0.10000000000000000555,0) [-3276.8000000000001819|3276.6999999999998181] "°C" Vector__XXX

BO_ 2650841089 BMMp_iso_Voltages: 8 Vector__XXX
  SG_ BMMp_act_U_BatNegVoltage_V : 0|16@1- (0.10000000000000000555,0) [-3276.8000000000001819|3276.6999999999998181] "V" Vector__XXX
  SG_ BMMp_act_U_BatPosVoltage_V : 16|16@1- (0.10000000000000000555,0) [-3276.8000000000001819|3276.6999999999998181] "V" Vector__XXX
  SG_ BMMp_act_U_SysNegVoltage_V : 32|16@1- (0.10000000000000000555,0) [-3276.8000000000001819|3276.6999999999998181] "V" Vector__XXX
  SG_ BMMp_act_U_SysPosVoltage_V : 48|16@1- (0.10000000000000000555,0) [-3276.8000000000001819|3276.6999999999998181] "V" Vector__XXX

BO_ 2650845185 BMMp_limits1: 8 Vector__XXX
  SG_ BMMp_lim_I_ChargeCurr_A : 32|16@1+ (0.10000000000000000555,0) [0|6553.5] "A" Vector__XXX
  SG_ BMMp_lim_I_DischargeCurr_A : 48|16@1+ (0.10000000000000000555,0) [0|6553.5] "A" Vector__XXX
  SG_ BMMp_lim_I_regenCurr_A : 16|16@1+ (0.10000000000000000555,0) [0|6553.5] "A" Vector__XXX
  SG_ BMMp_lim_regenPower_W : 0|16@1+ (10,0) [0|655350] "W" Vector__XXX

BO_ 2650849281 BMMp_limits2: 8 Vector__XXX
  SG_ BMMp_lim_P_ChargePow_W : 32|16@1+ (10,0) [0|655350] "W" Vector__XXX
  SG_ BMMp_lim_P_DischargePow_W : 48|16@1+ (10,0) [0|655350] "W" Vector__XXX
  SG_ BMMp_lim_U_MaxVolt_V : 0|16@1+ (0.10000000000000000555,0) [0|6553.5] "V" Vector__XXX
  SG_ BMMp_lim_U_MinVolt_V : 16|16@1+ (0.10000000000000000555,0) [0|6553.5] "V" Vector__XXX

BO_ 2650865665 BMMp_thermal_management: 8 Vector__XXX
  SG_ BMMp_avg_T_BatteryTemp_C : 32|16@1- (0.10000000000000000555,0) [-3276.8000000000001819|3276.6999999999998181] "°C" Vector__XXX
  SG_ BMMp_req_Chiller_pct : 56|8@1+ (1,0) [0|255] "%" Vector__XXX
  SG_ BMMp_req_Heater_pct : 48|8@1+ (1,0) [0|255] "%" Vector__XXX
  SG_ BMMp_req_Mode : 16|8@1+ (1,0) [0|255] "1/Bit" Vector__XXX
  SG_ BMMp_req_T_InletTemp_C : 0|16@1- (0.10000000000000000555,0) [-3276.8000000000001819|3276.6999999999998181] "°C" Vector__XXX

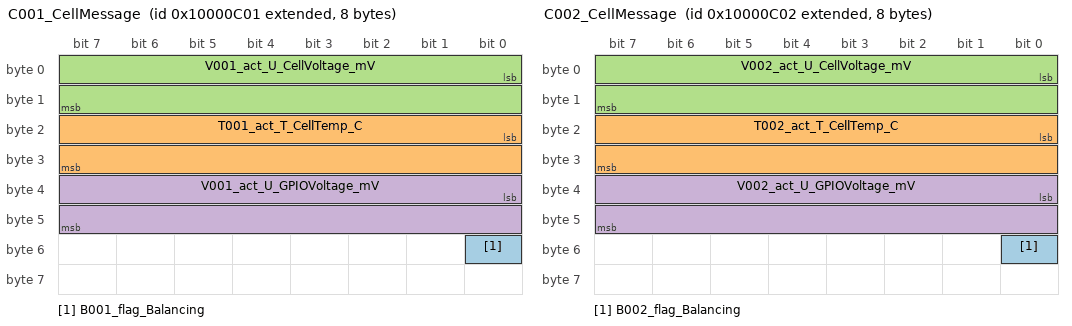
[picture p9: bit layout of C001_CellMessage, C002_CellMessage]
BO_ 2415922177 C001_CellMessage: 8 Vector__XXX
  SG_ B001_flag_Balancing : 48|1@1+ (1,0) [0|1] "" Vector__XXX
  SG_ T001_act_T_CellTemp_C : 16|16@1- (0.010000000000000000208,0) [-327.68000000000000682|327.67000000000001592] "°C" Vector__XXX
  SG_ V001_act_U_CellVoltage_mV : 0|16@1+ (0.10000000000000000555,0) [0|6553.5] "mV" Vector__XXX
  SG_ V001_act_U_GPIOVoltage_mV : 32|16@1+ (0.10000000000000000555,0) [0|6553.5] "mV" Vector__XXX

BO_ 2415922178 C002_CellMessage: 8 Vector__XXX
  SG_ B002_flag_Balancing : 48|1@1+ (1,0) [0|1] "" Vector__XXX
  SG_ T002_act_T_CellTemp_C : 16|16@1- (0.010000000000000000208,0) [-327.68000000000000682|327.67000000000001592] "°C" Vector__XXX
  SG_ V002_act_U_CellVoltage_mV : 0|16@1+ (0.10000000000000000555,0) [0|6553.5] "mV" Vector__XXX
  SG_ V002_act_U_GPIOVoltage_mV : 32|16@1+ (0.10000000000000000555,0) [0|6553.5] "mV" Vector__XXX

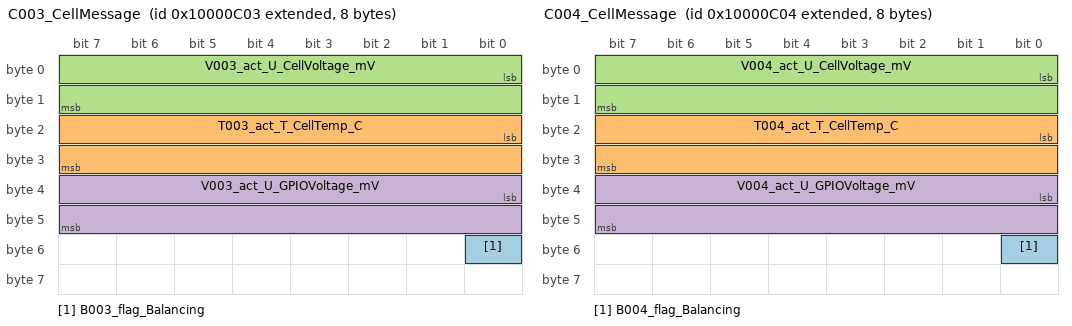
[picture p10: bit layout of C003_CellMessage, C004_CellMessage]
BO_ 2415922179 C003_CellMessage: 8 Vector__XXX
  SG_ B003_flag_Balancing : 48|1@1+ (1,0) [0|1] "" Vector__XXX
  SG_ T003_act_T_CellTemp_C : 16|16@1- (0.010000000000000000208,0) [-327.68000000000000682|327.67000000000001592] "°C" Vector__XXX
  SG_ V003_act_U_CellVoltage_mV : 0|16@1+ (0.10000000000000000555,0) [0|6553.5] "mV" Vector__XXX
  SG_ V003_act_U_GPIOVoltage_mV : 32|16@1+ (0.10000000000000000555,0) [0|6553.5] "mV" Vector__XXX

BO_ 2415922180 C004_CellMessage: 8 Vector__XXX
  SG_ B004_flag_Balancing : 48|1@1+ (1,0) [0|1] "" Vector__XXX
  SG_ T004_act_T_CellTemp_C : 16|16@1- (0.010000000000000000208,0) [-327.68000000000000682|327.67000000000001592] "°C" Vector__XXX
  SG_ V004_act_U_CellVoltage_mV : 0|16@1+ (0.10000000000000000555,0) [0|6553.5] "mV" Vector__XXX
  SG_ V004_act_U_GPIOVoltage_mV : 32|16@1+ (0.10000000000000000555,0) [0|6553.5] "mV" Vector__XXX

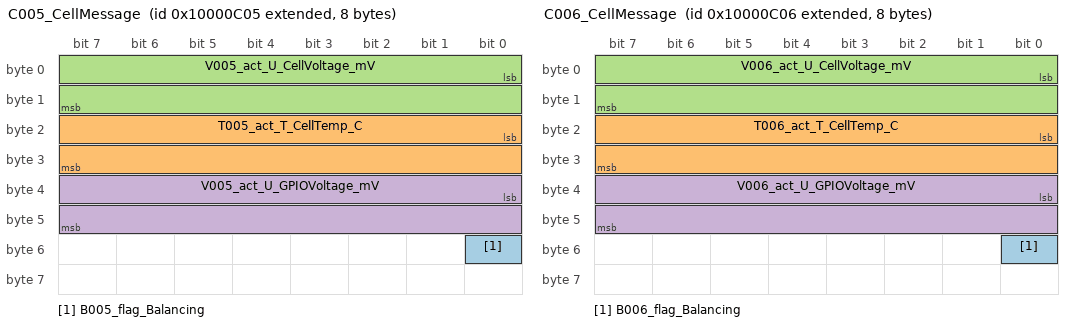
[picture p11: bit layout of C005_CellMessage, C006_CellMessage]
BO_ 2415922181 C005_CellMessage: 8 Vector__XXX
  SG_ B005_flag_Balancing : 48|1@1+ (1,0) [0|1] "" Vector__XXX
  SG_ T005_act_T_CellTemp_C : 16|16@1- (0.010000000000000000208,0) [-327.68000000000000682|327.67000000000001592] "°C" Vector__XXX
  SG_ V005_act_U_CellVoltage_mV : 0|16@1+ (0.10000000000000000555,0) [0|6553.5] "mV" Vector__XXX
  SG_ V005_act_U_GPIOVoltage_mV : 32|16@1+ (0.10000000000000000555,0) [0|6553.5] "mV" Vector__XXX

BO_ 2415922182 C006_CellMessage: 8 Vector__XXX
  SG_ B006_flag_Balancing : 48|1@1+ (1,0) [0|1] "" Vector__XXX
  SG_ T006_act_T_CellTemp_C : 16|16@1- (0.010000000000000000208,0) [-327.68000000000000682|327.67000000000001592] "°C" Vector__XXX
  SG_ V006_act_U_CellVoltage_mV : 0|16@1+ (0.10000000000000000555,0) [0|6553.5] "mV" Vector__XXX
  SG_ V006_act_U_GPIOVoltage_mV : 32|16@1+ (0.10000000000000000555,0) [0|6553.5] "mV" Vector__XXX

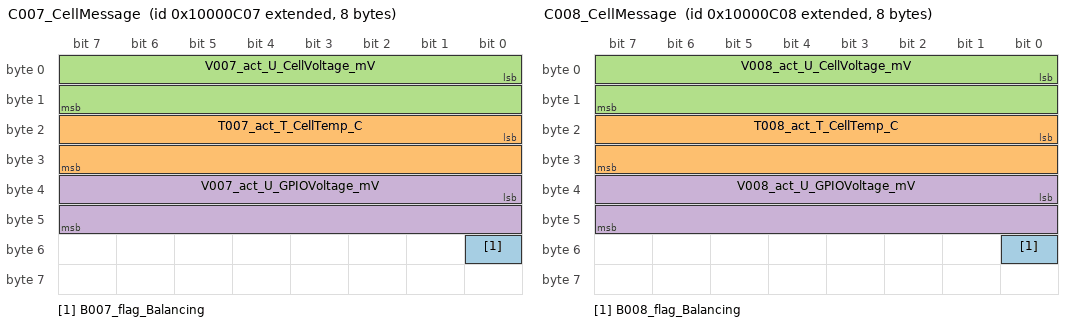
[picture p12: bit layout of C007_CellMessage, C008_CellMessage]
BO_ 2415922183 C007_CellMessage: 8 Vector__XXX
  SG_ B007_flag_Balancing : 48|1@1+ (1,0) [0|1] "" Vector__XXX
  SG_ T007_act_T_CellTemp_C : 16|16@1- (0.010000000000000000208,0) [-327.68000000000000682|327.67000000000001592] "°C" Vector__XXX
  SG_ V007_act_U_CellVoltage_mV : 0|16@1+ (0.10000000000000000555,0) [0|6553.5] "mV" Vector__XXX
  SG_ V007_act_U_GPIOVoltage_mV : 32|16@1+ (0.10000000000000000555,0) [0|6553.5] "mV" Vector__XXX

BO_ 2415922184 C008_CellMessage: 8 Vector__XXX
  SG_ B008_flag_Balancing : 48|1@1+ (1,0) [0|1] "" Vector__XXX
  SG_ T008_act_T_CellTemp_C : 16|16@1- (0.010000000000000000208,0) [-327.68000000000000682|327.67000000000001592] "°C" Vector__XXX
  SG_ V008_act_U_CellVoltage_mV : 0|16@1+ (0.10000000000000000555,0) [0|6553.5] "mV" Vector__XXX
  SG_ V008_act_U_GPIOVoltage_mV : 32|16@1+ (0.10000000000000000555,0) [0|6553.5] "mV" Vector__XXX

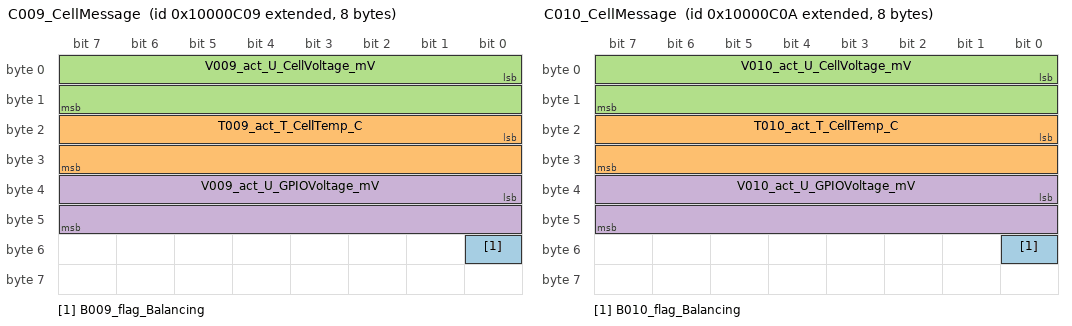
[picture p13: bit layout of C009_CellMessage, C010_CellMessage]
BO_ 2415922185 C009_CellMessage: 8 Vector__XXX
  SG_ B009_flag_Balancing : 48|1@1+ (1,0) [0|1] "" Vector__XXX
  SG_ T009_act_T_CellTemp_C : 16|16@1- (0.010000000000000000208,0) [-327.68000000000000682|327.67000000000001592] "°C" Vector__XXX
  SG_ V009_act_U_CellVoltage_mV : 0|16@1+ (0.10000000000000000555,0) [0|6553.5] "mV" Vector__XXX
  SG_ V009_act_U_GPIOVoltage_mV : 32|16@1+ (0.10000000000000000555,0) [0|6553.5] "mV" Vector__XXX

BO_ 2415922186 C010_CellMessage: 8 Vector__XXX
  SG_ B010_flag_Balancing : 48|1@1+ (1,0) [0|1] "" Vector__XXX
  SG_ T010_act_T_CellTemp_C : 16|16@1- (0.010000000000000000208,0) [-327.68000000000000682|327.67000000000001592] "°C" Vector__XXX
  SG_ V010_act_U_CellVoltage_mV : 0|16@1+ (0.10000000000000000555,0) [0|6553.5] "mV" Vector__XXX
  SG_ V010_act_U_GPIOVoltage_mV : 32|16@1+ (0.10000000000000000555,0) [0|6553.5] "mV" Vector__XXX

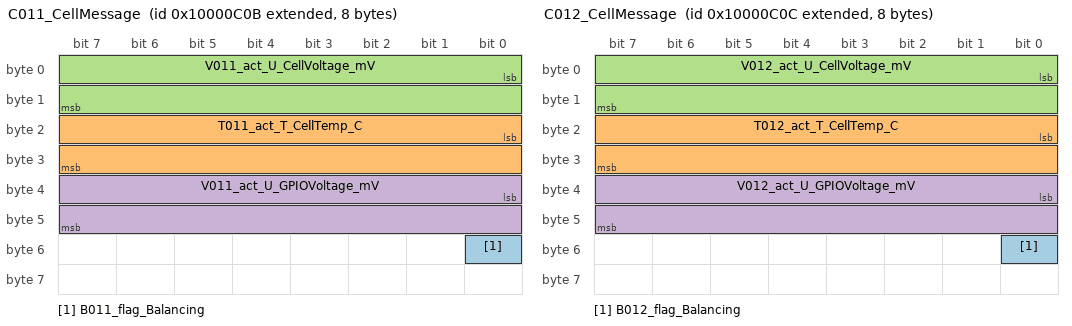
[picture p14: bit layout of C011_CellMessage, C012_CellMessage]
BO_ 2415922187 C011_CellMessage: 8 Vector__XXX
  SG_ B011_flag_Balancing : 48|1@1+ (1,0) [0|1] "" Vector__XXX
  SG_ T011_act_T_CellTemp_C : 16|16@1- (0.010000000000000000208,0) [-327.68000000000000682|327.67000000000001592] "°C" Vector__XXX
  SG_ V011_act_U_CellVoltage_mV : 0|16@1+ (0.10000000000000000555,0) [0|6553.5] "mV" Vector__XXX
  SG_ V011_act_U_GPIOVoltage_mV : 32|16@1+ (0.10000000000000000555,0) [0|6553.5] "mV" Vector__XXX

BO_ 2415922188 C012_CellMessage: 8 Vector__XXX
  SG_ B012_flag_Balancing : 48|1@1+ (1,0) [0|1] "" Vector__XXX
  SG_ T012_act_T_CellTemp_C : 16|16@1- (0.010000000000000000208,0) [-327.68000000000000682|327.67000000000001592] "°C" Vector__XXX
  SG_ V012_act_U_CellVoltage_mV : 0|16@1+ (0.10000000000000000555,0) [0|6553.5] "mV" Vector__XXX
  SG_ V012_act_U_GPIOVoltage_mV : 32|16@1+ (0.10000000000000000555,0) [0|6553.5] "mV" Vector__XXX

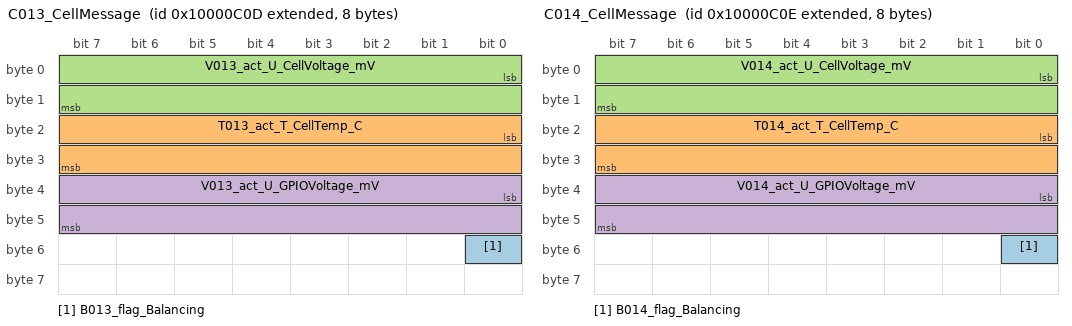
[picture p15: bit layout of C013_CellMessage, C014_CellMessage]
BO_ 2415922189 C013_CellMessage: 8 Vector__XXX
  SG_ B013_flag_Balancing : 48|1@1+ (1,0) [0|1] "" Vector__XXX
  SG_ T013_act_T_CellTemp_C : 16|16@1- (0.010000000000000000208,0) [-327.68000000000000682|327.67000000000001592] "°C" Vector__XXX
  SG_ V013_act_U_CellVoltage_mV : 0|16@1+ (0.10000000000000000555,0) [0|6553.5] "mV" Vector__XXX
  SG_ V013_act_U_GPIOVoltage_mV : 32|16@1+ (0.10000000000000000555,0) [0|6553.5] "mV" Vector__XXX

BO_ 2415922190 C014_CellMessage: 8 Vector__XXX
  SG_ B014_flag_Balancing : 48|1@1+ (1,0) [0|1] "" Vector__XXX
  SG_ T014_act_T_CellTemp_C : 16|16@1- (0.010000000000000000208,0) [-327.68000000000000682|327.67000000000001592] "°C" Vector__XXX
  SG_ V014_act_U_CellVoltage_mV : 0|16@1+ (0.10000000000000000555,0) [0|6553.5] "mV" Vector__XXX
  SG_ V014_act_U_GPIOVoltage_mV : 32|16@1+ (0.10000000000000000555,0) [0|6553.5] "mV" Vector__XXX

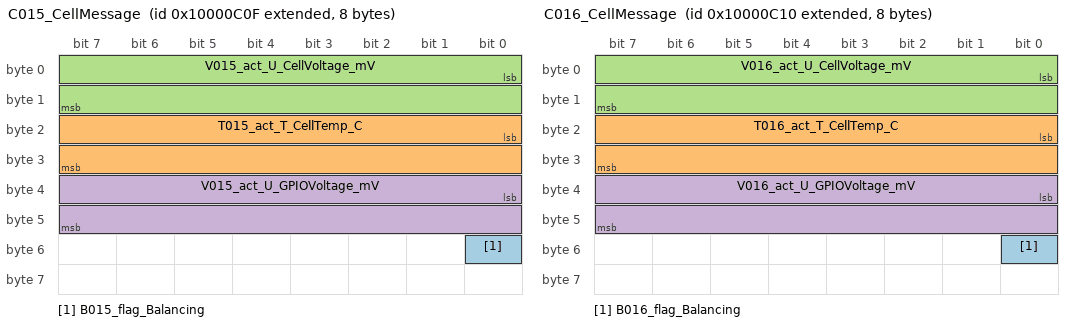
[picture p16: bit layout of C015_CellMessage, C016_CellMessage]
BO_ 2415922191 C015_CellMessage: 8 Vector__XXX
  SG_ B015_flag_Balancing : 48|1@1+ (1,0) [0|1] "" Vector__XXX
  SG_ T015_act_T_CellTemp_C : 16|16@1- (0.010000000000000000208,0) [-327.68000000000000682|327.67000000000001592] "°C" Vector__XXX
  SG_ V015_act_U_CellVoltage_mV : 0|16@1+ (0.10000000000000000555,0) [0|6553.5] "mV" Vector__XXX
  SG_ V015_act_U_GPIOVoltage_mV : 32|16@1+ (0.10000000000000000555,0) [0|6553.5] "mV" Vector__XXX

BO_ 2415922192 C016_CellMessage: 8 Vector__XXX
  SG_ B016_flag_Balancing : 48|1@1+ (1,0) [0|1] "" Vector__XXX
  SG_ T016_act_T_CellTemp_C : 16|16@1- (0.010000000000000000208,0) [-327.68000000000000682|327.67000000000001592] "°C" Vector__XXX
  SG_ V016_act_U_CellVoltage_mV : 0|16@1+ (0.10000000000000000555,0) [0|6553.5] "mV" Vector__XXX
  SG_ V016_act_U_GPIOVoltage_mV : 32|16@1+ (0.10000000000000000555,0) [0|6553.5] "mV" Vector__XXX

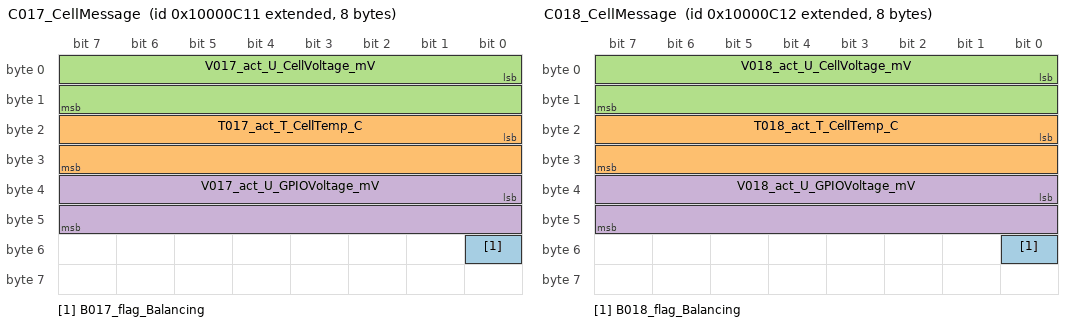
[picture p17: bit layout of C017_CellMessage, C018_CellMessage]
BO_ 2415922193 C017_CellMessage: 8 Vector__XXX
  SG_ B017_flag_Balancing : 48|1@1+ (1,0) [0|1] "" Vector__XXX
  SG_ T017_act_T_CellTemp_C : 16|16@1- (0.010000000000000000208,0) [-327.68000000000000682|327.67000000000001592] "°C" Vector__XXX
  SG_ V017_act_U_CellVoltage_mV : 0|16@1+ (0.10000000000000000555,0) [0|6553.5] "mV" Vector__XXX
  SG_ V017_act_U_GPIOVoltage_mV : 32|16@1+ (0.10000000000000000555,0) [0|6553.5] "mV" Vector__XXX

BO_ 2415922194 C018_CellMessage: 8 Vector__XXX
  SG_ B018_flag_Balancing : 48|1@1+ (1,0) [0|1] "" Vector__XXX
  SG_ T018_act_T_CellTemp_C : 16|16@1- (0.010000000000000000208,0) [-327.68000000000000682|327.67000000000001592] "°C" Vector__XXX
  SG_ V018_act_U_CellVoltage_mV : 0|16@1+ (0.10000000000000000555,0) [0|6553.5] "mV" Vector__XXX
  SG_ V018_act_U_GPIOVoltage_mV : 32|16@1+ (0.10000000000000000555,0) [0|6553.5] "mV" Vector__XXX

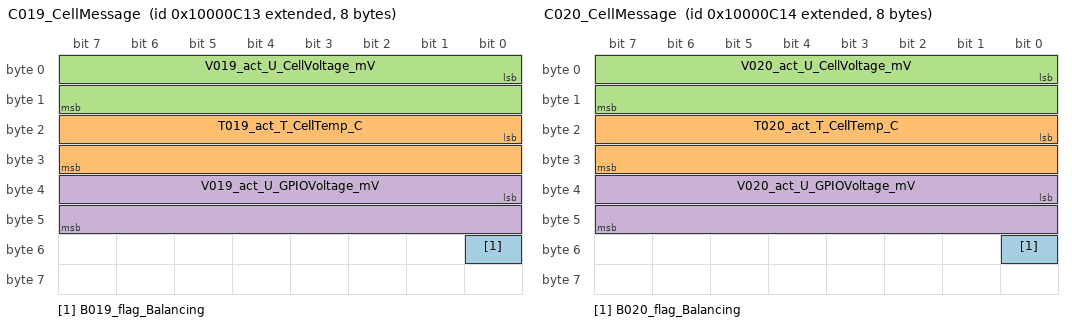
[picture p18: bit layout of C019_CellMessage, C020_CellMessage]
BO_ 2415922195 C019_CellMessage: 8 Vector__XXX
  SG_ B019_flag_Balancing : 48|1@1+ (1,0) [0|1] "" Vector__XXX
  SG_ T019_act_T_CellTemp_C : 16|16@1- (0.010000000000000000208,0) [-327.68000000000000682|327.67000000000001592] "°C" Vector__XXX
  SG_ V019_act_U_CellVoltage_mV : 0|16@1+ (0.10000000000000000555,0) [0|6553.5] "mV" Vector__XXX
  SG_ V019_act_U_GPIOVoltage_mV : 32|16@1+ (0.10000000000000000555,0) [0|6553.5] "mV" Vector__XXX

BO_ 2415922196 C020_CellMessage: 8 Vector__XXX
  SG_ B020_flag_Balancing : 48|1@1+ (1,0) [0|1] "" Vector__XXX
  SG_ T020_act_T_CellTemp_C : 16|16@1- (0.010000000000000000208,0) [-327.68000000000000682|327.67000000000001592] "°C" Vector__XXX
  SG_ V020_act_U_CellVoltage_mV : 0|16@1+ (0.10000000000000000555,0) [0|6553.5] "mV" Vector__XXX
  SG_ V020_act_U_GPIOVoltage_mV : 32|16@1+ (0.10000000000000000555,0) [0|6553.5] "mV" Vector__XXX

BO_ 2415941633 M001_BMSInfo: 8 Vector__XXX
  SG_ M001_flag_BadCRC_IC1 : 32|1@1+ (1,0) [0|1] "" Vector__XXX
  SG_ M001_flag_BadCRC_IC2 : 33|1@1+ (1,0) [0|1] "" Vector__XXX
  SG_ M001_flag_BadCRC_IC3 : 34|1@1+ (1,0) [0|1] "" Vector__XXX
  SG_ M001_flag_BadCRC_IC4 : 35|1@1+ (1,0) [0|1] "" Vector__XXX
  SG_ M001_flag_CalibrationDone : 0|1@1+ (1,0) [0|1] "" Vector__XXX
  SG_ M001_flag_CalibrationError : 2|1@1+ (1,0) [0|1] "" Vector__XXX
  SG_ M001_flag_CalibrationIncomp : 1|1@1+ (1,0) [0|1] "" Vector__XXX
  SG_ M001_flag_ComplDynAreaCRCErr : 39|1@1+ (1,0) [0|1] "" Vector__XXX
  SG_ M001_flag_ComplSafAreaCRCErr : 37|1@1+ (1,0) [0|1] "" Vector__XXX
  SG_ M001_flag_ComplStatAreaCRCErr : 38|1@1+ (1,0) [0|1] "" Vector__XXX
  SG_ M001_flag_ConfigDone : 6|1@1+ (1,0) [0|1] "" Vector__XXX
  SG_ M001_flag_DynAreaReadFail : 55|1@1+ (1,0) [0|1] "" Vector__XXX
  SG_ M001_flag_DynAreaWriteFail : 52|1@1+ (1,0) [0|1] "" Vector__XXX
  SG_ M001_flag_EEPROMError : 4|1@1+ (1,0) [0|1] "" Vector__XXX
  SG_ M001_flag_EEPROMReadFail : 48|1@1+ (1,0) [0|1] "" Vector__XXX
  SG_ M001_flag_I2CCommunicationFail : 47|1@1+ (1,0) [0|1] "" Vector__XXX
  SG_ M001_flag_IDPageNotLocked : 46|1@1+ (1,0) [0|1] "" Vector__XXX
  SG_ M001_flag_IDPageStatusReadFail : 49|1@1+ (1,0) [0|1] "" Vector__XXX
  SG_ M001_flag_InitialisationFail : 40|1@1+ (1,0) [0|1] "" Vector__XXX
  SG_ M001_flag_NoSafRel_BadCRC_IC1 : 28|1@1+ (1,0) [0|1] "" Vector__XXX
  SG_ M001_flag_NoSafRel_BadCRC_IC2 : 29|1@1+ (1,0) [0|1] "" Vector__XXX
  SG_ M001_flag_NoSafRel_BadCRC_IC3 : 30|1@1+ (1,0) [0|1] "" Vector__XXX
  SG_ M001_flag_NoSafRel_BadCRC_IC4 : 31|1@1+ (1,0) [0|1] "" Vector__XXX
  SG_ M001_flag_NoSafRel_PollTimeout : 23|1@1+ (1,0) [0|1] "" Vector__XXX
  SG_ M001_flag_PollTimeout : 36|1@1+ (1,0) [0|1] "" Vector__XXX
  SG_ M001_flag_SM_BadCRC_IC1 : 24|1@1+ (1,0) [0|1] "" Vector__XXX
  SG_ M001_flag_SM_BadCRC_IC2 : 25|1@1+ (1,0) [0|1] "" Vector__XXX
  SG_ M001_flag_SM_BadCRC_IC3 : 26|1@1+ (1,0) [0|1] "" Vector__XXX
  SG_ M001_flag_SM_BadCRC_IC4 : 27|1@1+ (1,0) [0|1] "" Vector__XXX
  SG_ M001_flag_SM_PollTimeout : 22|1@1+ (1,0) [0|1] "" Vector__XXX
  SG_ M001_flag_SafAreaMismatch : 44|1@1+ (1,0) [0|1] "" Vector__XXX
  SG_ M001_flag_SafAreaReadFail : 53|1@1+ (1,0) [0|1] "" Vector__XXX
  SG_ M001_flag_SafAreaWriteFail : 50|1@1+ (1,0) [0|1] "" Vector__XXX
  SG_ M001_flag_SelfTestPassed : 16|1@1+ (1,0) [0|1] "" Vector__XXX
  SG_ M001_flag_SerialMiss : 10|1@1+ (1,0) [0|1] "" Vector__XXX
  SG_ M001_flag_SingleDynAreaCRCErr : 43|1@1+ (1,0) [0|1] "" Vector__XXX
  SG_ M001_flag_SingleSafAreaCRCErr : 41|1@1+ (1,0) [0|1] "" Vector__XXX
  SG_ M001_flag_SingleStatAreaCRCErr : 42|1@1+ (1,0) [0|1] "" Vector__XXX
  SG_ M001_flag_StatAreaMismatch : 45|1@1+ (1,0) [0|1] "" Vector__XXX
  SG_ M001_flag_StatAreaReadFail : 54|1@1+ (1,0) [0|1] "" Vector__XXX
  SG_ M001_flag_StatreaWriteFail : 51|1@1+ (1,0) [0|1] "" Vector__XXX
  SG_ M001_flag_TempCalErr : 7|1@1+ (1,0) [0|1] "" Vector__XXX
  SG_ M001_flag_ThermalShtDwn_IC1 : 11|1@1+ (1,0) [0|1] "" Vector__XXX
  SG_ M001_flag_ThermalShtDwn_IC2 : 12|1@1+ (1,0) [0|1] "" Vector__XXX
  SG_ M001_flag_ThermalShtDwn_IC3 : 13|1@1+ (1,0) [0|1] "" Vector__XXX
  SG_ M001_flag_ThermalShtDwn_IC4 : 14|1@1+ (1,0) [0|1] "" Vector__XXX
  SG_ M001_flag_VerifyDynWriteFail : 58|1@1+ (1,0) [0|1] "" Vector__XXX
  SG_ M001_flag_VerifySafWriteFail : 56|1@1+ (1,0) [0|1] "" Vector__XXX
  SG_ M001_flag_VerifyStatWriteFail : 57|1@1+ (1,0) [0|1] "" Vector__XXX
  SG_ M001_flag_WDGError : 5|1@1+ (1,0) [0|1] "" Vector__XXX

BO_ 2451052545 M001_BalanceCells: 8 Vector__XXX
  SG_ M001_flag_BalanceCell1 : 0|1@1+ (1,0) [0|1] "" Vector__XXX
  SG_ M001_flag_BalanceCell10 : 9|1@1+ (1,0) [0|1] "" Vector__XXX
  SG_ M001_flag_BalanceCell11 : 10|1@1+ (1,0) [0|1] "" Vector__XXX
  SG_ M001_flag_BalanceCell12 : 11|1@1+ (1,0) [0|1] "" Vector__XXX
  SG_ M001_flag_BalanceCell13 : 12|1@1+ (1,0) [0|1] "" Vector__XXX
  SG_ M001_flag_BalanceCell14 : 13|1@1+ (1,0) [0|1] "" Vector__XXX
  SG_ M001_flag_BalanceCell15 : 14|1@1+ (1,0) [0|1] "" Vector__XXX
  SG_ M001_flag_BalanceCell16 : 15|1@1+ (1,0) [0|1] "" Vector__XXX
  SG_ M001_flag_BalanceCell17 : 16|1@1+ (1,0) [0|1] "" Vector__XXX
  SG_ M001_flag_BalanceCell18 : 17|1@1+ (1,0) [0|1] "" Vector__XXX
  SG_ M001_flag_BalanceCell19 : 18|1@1+ (1,0) [0|1] "" Vector__XXX
  SG_ M001_flag_BalanceCell2 : 1|1@1+ (1,0) [0|1] "" Vector__XXX
  SG_ M001_flag_BalanceCell20 : 19|1@1+ (1,0) [0|1] "" Vector__XXX
  SG_ M001_flag_BalanceCell21 : 20|1@1+ (1,0) [0|1] "" Vector__XXX
  SG_ M001_flag_BalanceCell22 : 21|1@1+ (1,0) [0|1] "" Vector__XXX
  SG_ M001_flag_BalanceCell23 : 22|1@1+ (1,0) [0|1] "" Vector__XXX
  SG_ M001_flag_BalanceCell24 : 23|1@1+ (1,0) [0|1] "" Vector__XXX
  SG_ M001_flag_BalanceCell25 : 24|1@1+ (1,0) [0|1] "" Vector__XXX
  SG_ M001_flag_BalanceCell26 : 25|1@1+ (1,0) [0|1] "" Vector__XXX
  SG_ M001_flag_BalanceCell27 : 26|1@1+ (1,0) [0|1] "" Vector__XXX
  SG_ M001_flag_BalanceCell28 : 27|1@1+ (1,0) [0|1] "" Vector__XXX
  SG_ M001_flag_BalanceCell29 : 28|1@1+ (1,0) [0|1] "" Vector__XXX
  SG_ M001_flag_BalanceCell3 : 2|1@1+ (1,0) [0|1] "" Vector__XXX
  SG_ M001_flag_BalanceCell30 : 29|1@1+ (1,0) [0|1] "" Vector__XXX
  SG_ M001_flag_BalanceCell31 : 30|1@1+ (1,0) [0|1] "" Vector__XXX
  SG_ M001_flag_BalanceCell32 : 31|1@1+ (1,0) [0|1] "" Vector__XXX
  SG_ M001_flag_BalanceCell4 : 3|1@1+ (1,0) [0|1] "" Vector__XXX
  SG_ M001_flag_BalanceCell5 : 4|1@1+ (1,0) [0|1] "" Vector__XXX
  SG_ M001_flag_BalanceCell6 : 5|1@1+ (1,0) [0|1] "" Vector__XXX
  SG_ M001_flag_BalanceCell7 : 6|1@1+ (1,0) [0|1] "" Vector__XXX
  SG_ M001_flag_BalanceCell8 : 7|1@1+ (1,0) [0|1] "" Vector__XXX
  SG_ M001_flag_BalanceCell9 : 8|1@1+ (1,0) [0|1] "" Vector__XXX

BO_ 2550716417 M001_ConfigurationMessage: 8 Vector__XXX
  SG_ M001_ConfigurationMessage_Mux M : 0|32@1+ (1,0) [0|4294967295] "" Vector__XXX
  SG_ M001_conf_NewCellTypeMajor m2147483647 : 32|8@1+ (1,0) [0|255] "" Vector__XXX
  SG_ M001_conf_NewCellTypeMinor m2147483647 : 40|8@1+ (1,0) [0|255] "" Vector__XXX
  SG_ M001_conf_NewICTypeMajor m2147483647 : 32|8@1+ (1,0) [0|255] "" Vector__XXX
  SG_ M001_conf_NewICTypeMinor m2147483647 : 40|8@1+ (1,0) [0|255] "" Vector__XXX
  SG_ M001_conf_NewModuleTypeMajor m2147483647 : 32|8@1+ (1,0) [0|255] "" Vector__XXX
  SG_ M001_conf_NewModuleTypeMinor m2147483647 : 40|8@1+ (1,0) [0|255] "" Vector__XXX
  SG_ M001_conf_NewPCBTypeMajor m298756693 : 32|8@1+ (1,0) [0|255] "" Vector__XXX
  SG_ M001_conf_NewPCBTypeMinor m298756693 : 40|8@1+ (1,0) [0|255] "" Vector__XXX
  SG_ M001_conf_NewSerialNrHi m2147483647 : 32|32@1+ (1,0) [0|4294967295] "" Vector__XXX
  SG_ M001_conf_NewSerialNrLo m2147483647 : 32|32@1+ (1,0) [0|4294967295] "" Vector__XXX
  SG_ M001_conf_PCBNewSerialNrHi m218999381 : 32|32@1+ (1,0) [0|4294967295] "" Vector__XXX
  SG_ M001_conf_PCBNewSerialNrLo m2147483647 : 32|32@1+ (1,0) [0|4294967295] "" Vector__XXX
  SG_ M001_conf_TopologyMajor m2147483647 : 32|8@1+ (1,0) [0|255] "" Vector__XXX
  SG_ M001_conf_TopologyMinor m2147483647 : 40|8@1+ (1,0) [0|255] "" Vector__XXX

BO_ 2415949825 M001_EEPROMData: 8 Vector__XXX
  SG_ M001_WriteDynamicAreaANext : 8|1@1+ (1,0) [0|1] "" Vector__XXX
  SG_ M001_val_EEPROMData : 32|32@1+ (1,0) [0|4294967295] "" Vector__XXX
  SG_ M001_val_EEPROMIndex : 0|8@1+ (1,0) [0|255] "" Vector__XXX

BO_ 2415962113 M001_IC_AnalogPower: 8 Vector__XXX
  SG_ M001_act_U_AnalogPower_IC1_mV : 0|16@1+ (0.10000000000000000555,0) [0|6553.5] "mV" Vector__XXX
  SG_ M001_act_U_AnalogPower_IC2_mV : 16|16@1+ (0.10000000000000000555,0) [0|6553.5] "mV" Vector__XXX
  SG_ M001_act_U_AnalogPower_IC3_mV : 32|16@1+ (0.10000000000000000555,0) [0|6553.5] "mV" Vector__XXX
  SG_ M001_act_U_AnalogPower_IC4_mV : 48|16@1+ (0.10000000000000000555,0) [0|6553.5] "mV" Vector__XXX

BO_ 2415970305 M001_IC_CellSumVoltages: 8 Vector__XXX
  SG_ M001_act_U_SumOfCell_IC1_V : 0|16@1+ (0.010000000000000000208,0) [0|655.35000000000002274] "V" Vector__XXX
  SG_ M001_act_U_SumOfCell_IC2_V : 16|16@1+ (0.010000000000000000208,0) [0|655.35000000000002274] "V" Vector__XXX
  SG_ M001_act_U_SumOfCell_IC3_V : 32|16@1+ (0.010000000000000000208,0) [0|655.35000000000002274] "V" Vector__XXX
  SG_ M001_act_U_SumOfCell_IC4_V : 48|16@1+ (0.010000000000000000208,0) [0|655.35000000000002274] "V" Vector__XXX

BO_ 2415958017 M001_IC_DigitalPower: 8 Vector__XXX
  SG_ M001_act_U_DigiPower_IC1_mV : 0|16@1+ (0.10000000000000000555,0) [0|6553.5] "mV" Vector__XXX
  SG_ M001_act_U_DigiPower_IC2_mV : 16|16@1+ (0.10000000000000000555,0) [0|6553.5] "mV" Vector__XXX
  SG_ M001_act_U_DigiPower_IC3_mV : 32|16@1+ (0.10000000000000000555,0) [0|6553.5] "mV" Vector__XXX
  SG_ M001_act_U_DigiPower_IC4_mV : 48|16@1+ (0.10000000000000000555,0) [0|6553.5] "mV" Vector__XXX

BO_ 2415953921 M001_IC_InternalTemperature: 8 Vector__XXX
  SG_ M001_act_T_IC1_Temp_C : 0|16@1- (0.010000000000000000208,0) [-327.68000000000000682|327.67000000000001592] "°C" Vector__XXX
  SG_ M001_act_T_IC2_Temp_C : 16|16@1- (0.010000000000000000208,0) [-327.68000000000000682|327.67000000000001592] "°C" Vector__XXX
  SG_ M001_act_T_IC3_Temp_C : 32|16@1- (0.010000000000000000208,0) [-327.68000000000000682|327.67000000000001592] "°C" Vector__XXX
  SG_ M001_act_T_IC4_Temp_C : 48|16@1- (0.010000000000000000208,0) [-327.68000000000000682|327.67000000000001592] "°C" Vector__XXX

BO_ 2415966209 M001_IC_RefVoltages: 8 Vector__XXX
  SG_ M001_act_U_RefVoltage_IC1_mV : 0|16@1+ (0.10000000000000000555,0) [0|6553.5] "mV" Vector__XXX
  SG_ M001_act_U_RefVoltage_IC2_mV : 16|16@1+ (0.10000000000000000555,0) [0|6553.5] "mV" Vector__XXX
  SG_ M001_act_U_RefVoltage_IC3_mV : 32|16@1+ (0.10000000000000000555,0) [0|6553.5] "mV" Vector__XXX
  SG_ M001_act_U_RefVoltage_IC4_mV : 48|16@1+ (0.10000000000000000555,0) [0|6553.5] "mV" Vector__XXX

BO_ 2415933441 M001_MaxMinVoltages: 8 Vector__XXX
  SG_ M001_avg_U_CellVoltage_mV_fast : 32|16@1+ (0.10000000000000000555,0) [0|6553.5] "mV" Vector__XXX
  SG_ M001_max_U_CellVoltage_mV_fast : 16|16@1+ (0.10000000000000000555,0) [0|6553.5] "mV" Vector__XXX
  SG_ M001_min_U_CellVoltage_mV_fast : 0|16@1+ (0.10000000000000000555,0) [0|6553.5] "mV" Vector__XXX

BO_ 2415937537 M001_ModuleInformation: 8 Vector__XXX
  SG_ M001_inf_CellTypeMajor : 48|8@1+ (1,0) [0|255] "" Vector__XXX
  SG_ M001_inf_CellTypeMinor : 56|8@1+ (1,0) [0|255] "" Vector__XXX
  SG_ M001_inf_ParallelCells : 40|8@1+ (1,0) [0|255] "" Vector__XXX
  SG_ M001_inf_SerialCells : 32|8@1+ (1,0) [0|255] "" Vector__XXX

BO_ 2415986689 M001_ModuleSafetyMechanisms: 8 Vector__XXX
  SG_ M001_ADCOverlapTestFailed_IC1 : 1|1@1+ (1,0) [0|1] "" Vector__XXX
  SG_ M001_ADCOverlapTestFailed_IC2 : 17|1@1+ (1,0) [0|1] "" Vector__XXX
  SG_ M001_ADCOverlapTestFailed_IC3 : 33|1@1+ (1,0) [0|1] "" Vector__XXX
  SG_ M001_ADCOverlapTestFailed_IC4 : 49|1@1+ (1,0) [0|1] "" Vector__XXX
  SG_ M001_ADCSefttestAUXFailed_IC1 : 3|1@1+ (1,0) [0|1] "" Vector__XXX
  SG_ M001_ADCSefttestAUXFailed_IC2 : 19|1@1+ (1,0) [0|1] "" Vector__XXX
  SG_ M001_ADCSefttestAUXFailed_IC3 : 35|1@1+ (1,0) [0|1] "" Vector__XXX
  SG_ M001_ADCSefttestAUXFailed_IC4 : 51|1@1+ (1,0) [0|1] "" Vector__XXX
  SG_ M001_ADCSefttestCVFailed_IC1 : 2|1@1+ (1,0) [0|1] "" Vector__XXX
  SG_ M001_ADCSefttestCVFailed_IC2 : 18|1@1+ (1,0) [0|1] "" Vector__XXX
  SG_ M001_ADCSefttestCVFailed_IC3 : 34|1@1+ (1,0) [0|1] "" Vector__XXX
  SG_ M001_ADCSefttestCVFailed_IC4 : 50|1@1+ (1,0) [0|1] "" Vector__XXX
  SG_ M001_BadCRCAccepted_IC1 : 6|1@1+ (1,0) [0|1] "" Vector__XXX
  SG_ M001_BadCRCAccepted_IC2 : 22|1@1+ (1,0) [0|1] "" Vector__XXX
  SG_ M001_BadCRCAccepted_IC3 : 38|1@1+ (1,0) [0|1] "" Vector__XXX
  SG_ M001_BadCRCAccepted_IC4 : 54|1@1+ (1,0) [0|1] "" Vector__XXX
  SG_ M001_CLRCmdBroken_IC1 : 8|1@1+ (1,0) [0|1] "" Vector__XXX
  SG_ M001_CLRCmdBroken_IC2 : 24|1@1+ (1,0) [0|1] "" Vector__XXX
  SG_ M001_CLRCmdBroken_IC3 : 40|1@1+ (1,0) [0|1] "" Vector__XXX
  SG_ M001_CLRCmdBroken_IC4 : 56|1@1+ (1,0) [0|1] "" Vector__XXX
  SG_ M001_DischargeCircuitFault_IC1 : 11|1@1+ (1,0) [0|1] "" Vector__XXX
  SG_ M001_DischargeCircuitFault_IC2 : 27|1@1+ (1,0) [0|1] "" Vector__XXX
  SG_ M001_DischargeCircuitFault_IC3 : 43|1@1+ (1,0) [0|1] "" Vector__XXX
  SG_ M001_DischargeCircuitFault_IC4 : 59|1@1+ (1,0) [0|1] "" Vector__XXX
  SG_ M001_GPIOAdjShortDetected_IC1 : 7|1@1+ (1,0) [0|1] "" Vector__XXX
  SG_ M001_GPIOAdjShortDetected_IC2 : 23|1@1+ (1,0) [0|1] "" Vector__XXX
  SG_ M001_GPIOAdjShortDetected_IC3 : 39|1@1+ (1,0) [0|1] "" Vector__XXX
  SG_ M001_GPIOAdjShortDetected_IC4 : 55|1@1+ (1,0) [0|1] "" Vector__XXX
  SG_ M001_MUXFail_IC1 : 5|1@1+ (1,0) [0|1] "" Vector__XXX
  SG_ M001_MUXFail_IC2 : 21|1@1+ (1,0) [0|1] "" Vector__XXX
  SG_ M001_MUXFail_IC3 : 37|1@1+ (1,0) [0|1] "" Vector__XXX
  SG_ M001_MUXFail_IC4 : 53|1@1+ (1,0) [0|1] "" Vector__XXX
  SG_ M001_OWCircuitStuckCV_IC1 : 10|1@1+ (1,0) [0|1] "" Vector__XXX
  SG_ M001_OWCircuitStuckCV_IC2 : 26|1@1+ (1,0) [0|1] "" Vector__XXX
  SG_ M001_OWCircuitStuckCV_IC3 : 42|1@1+ (1,0) [0|1] "" Vector__XXX
  SG_ M001_OWCircuitStuckCV_IC4 : 58|1@1+ (1,0) [0|1] "" Vector__XXX
  SG_ M001_OpenWireDetectedAUX_IC1 : 4|1@1+ (1,0) [0|1] "" Vector__XXX
  SG_ M001_OpenWireDetectedAUX_IC2 : 20|1@1+ (1,0) [0|1] "" Vector__XXX
  SG_ M001_OpenWireDetectedAUX_IC3 : 36|1@1+ (1,0) [0|1] "" Vector__XXX
  SG_ M001_OpenWireDetectedAUX_IC4 : 52|1@1+ (1,0) [0|1] "" Vector__XXX
  SG_ M001_OpenWireDetectedCV_IC1 : 0|1@1+ (1,0) [0|1] "" Vector__XXX
  SG_ M001_OpenWireDetectedCV_IC2 : 16|1@1+ (1,0) [0|1] "" Vector__XXX
  SG_ M001_OpenWireDetectedCV_IC3 : 32|1@1+ (1,0) [0|1] "" Vector__XXX
  SG_ M001_OpenWireDetectedCV_IC4 : 48|1@1+ (1,0) [0|1] "" Vector__XXX
  SG_ M001_SM_ClrRegsFail_IC1 : 13|1@1+ (1,0) [0|1] "" Vector__XXX
  SG_ M001_SM_ClrRegsFail_IC2 : 29|1@1+ (1,0) [0|1] "" Vector__XXX
  SG_ M001_SM_ClrRegsFail_IC3 : 45|1@1+ (1,0) [0|1] "" Vector__XXX
  SG_ M001_SM_ClrRegsFail_IC4 : 61|1@1+ (1,0) [0|1] "" Vector__XXX
  SG_ M001_SM_digRedFail_IC1 : 12|1@1+ (1,0) [0|1] "" Vector__XXX
  SG_ M001_SM_digRedFail_IC2 : 28|1@1+ (1,0) [0|1] "" Vector__XXX
  SG_ M001_SM_digRedFail_IC3 : 44|1@1+ (1,0) [0|1] "" Vector__XXX
  SG_ M001_SM_digRedFail_IC4 : 60|1@1+ (1,0) [0|1] "" Vector__XXX
  SG_ M001_WrongPathSelection_IC1 : 9|1@1+ (1,0) [0|1] "" Vector__XXX
  SG_ M001_WrongPathSelection_IC2 : 25|1@1+ (1,0) [0|1] "" Vector__XXX
  SG_ M001_WrongPathSelection_IC3 : 41|1@1+ (1,0) [0|1] "" Vector__XXX
  SG_ M001_WrongPathSelection_IC4 : 57|1@1+ (1,0) [0|1] "" Vector__XXX

BO_ 2415929345 M001_ModuleStatus: 8 Vector__XXX
  SG_ M001_act_T_TermTempSplitNeg : 0|16@1- (0.010000000000000000208,0) [-327.68000000000000682|327.67000000000001592] "°C" Vector__XXX
  SG_ M001_act_T_TermTempSplitPos : 16|16@1- (0.010000000000000000208,0) [-327.68000000000000682|327.67000000000001592] "°C" Vector__XXX
  SG_ M001_act_U_ModuleVoltage_V : 48|16@1+ (0.010000000000000000208,0) [0|655.35000000000002274] "V" Vector__XXX

BO_ 2415974401 M001_OverVoltageFlags: 8 Vector__XXX
  SG_ M001_flag_OvervoltageCell1 : 0|1@1+ (1,0) [0|1] "" Vector__XXX
  SG_ M001_flag_OvervoltageCell10 : 9|1@1+ (1,0) [0|1] "" Vector__XXX
  SG_ M001_flag_OvervoltageCell11 : 10|1@1+ (1,0) [0|1] "" Vector__XXX
  SG_ M001_flag_OvervoltageCell12 : 11|1@1+ (1,0) [0|1] "" Vector__XXX
  SG_ M001_flag_OvervoltageCell13 : 12|1@1+ (1,0) [0|1] "" Vector__XXX
  SG_ M001_flag_OvervoltageCell14 : 13|1@1+ (1,0) [0|1] "" Vector__XXX
  SG_ M001_flag_OvervoltageCell15 : 14|1@1+ (1,0) [0|1] "" Vector__XXX
  SG_ M001_flag_OvervoltageCell16 : 15|1@1+ (1,0) [0|1] "" Vector__XXX
  SG_ M001_flag_OvervoltageCell17 : 16|1@1+ (1,0) [0|1] "" Vector__XXX
  SG_ M001_flag_OvervoltageCell18 : 17|1@1+ (1,0) [0|1] "" Vector__XXX
  SG_ M001_flag_OvervoltageCell19 : 18|1@1+ (1,0) [0|1] "" Vector__XXX
  SG_ M001_flag_OvervoltageCell2 : 1|1@1+ (1,0) [0|1] "" Vector__XXX
  SG_ M001_flag_OvervoltageCell20 : 19|1@1+ (1,0) [0|1] "" Vector__XXX
  SG_ M001_flag_OvervoltageCell21 : 20|1@1+ (1,0) [0|1] "" Vector__XXX
  SG_ M001_flag_OvervoltageCell22 : 21|1@1+ (1,0) [0|1] "" Vector__XXX
  SG_ M001_flag_OvervoltageCell23 : 22|1@1+ (1,0) [0|1] "" Vector__XXX
  SG_ M001_flag_OvervoltageCell24 : 23|1@1+ (1,0) [0|1] "" Vector__XXX
  SG_ M001_flag_OvervoltageCell25 : 24|1@1+ (1,0) [0|1] "" Vector__XXX
  SG_ M001_flag_OvervoltageCell26 : 25|1@1+ (1,0) [0|1] "" Vector__XXX
  SG_ M001_flag_OvervoltageCell27 : 26|1@1+ (1,0) [0|1] "" Vector__XXX
  SG_ M001_flag_OvervoltageCell28 : 27|1@1+ (1,0) [0|1] "" Vector__XXX
  SG_ M001_flag_OvervoltageCell29 : 28|1@1+ (1,0) [0|1] "" Vector__XXX
  SG_ M001_flag_OvervoltageCell3 : 2|1@1+ (1,0) [0|1] "" Vector__XXX
  SG_ M001_flag_OvervoltageCell30 : 29|1@1+ (1,0) [0|1] "" Vector__XXX
  SG_ M001_flag_OvervoltageCell31 : 30|1@1+ (1,0) [0|1] "" Vector__XXX
  SG_ M001_flag_OvervoltageCell32 : 31|1@1+ (1,0) [0|1] "" Vector__XXX
  SG_ M001_flag_OvervoltageCell33 : 32|1@1+ (1,0) [0|1] "" Vector__XXX
  SG_ M001_flag_OvervoltageCell34 : 33|1@1+ (1,0) [0|1] "" Vector__XXX
  SG_ M001_flag_OvervoltageCell35 : 34|1@1+ (1,0) [0|1] "" Vector__XXX
  SG_ M001_flag_OvervoltageCell36 : 35|1@1+ (1,0) [0|1] "" Vector__XXX
  SG_ M001_flag_OvervoltageCell37 : 36|1@1+ (1,0) [0|1] "" Vector__XXX
  SG_ M001_flag_OvervoltageCell38 : 37|1@1+ (1,0) [0|1] "" Vector__XXX
  SG_ M001_flag_OvervoltageCell39 : 38|1@1+ (1,0) [0|1] "" Vector__XXX
  SG_ M001_flag_OvervoltageCell4 : 3|1@1+ (1,0) [0|1] "" Vector__XXX
  SG_ M001_flag_OvervoltageCell40 : 39|1@1+ (1,0) [0|1] "" Vector__XXX
  SG_ M001_flag_OvervoltageCell5 : 4|1@1+ (1,0) [0|1] "" Vector__XXX
  SG_ M001_flag_OvervoltageCell6 : 5|1@1+ (1,0) [0|1] "" Vector__XXX
  SG_ M001_flag_OvervoltageCell7 : 6|1@1+ (1,0) [0|1] "" Vector__XXX
  SG_ M001_flag_OvervoltageCell8 : 7|1@1+ (1,0) [0|1] "" Vector__XXX
  SG_ M001_flag_OvervoltageCell9 : 8|1@1+ (1,0) [0|1] "" Vector__XXX

BO_ 2415982593 M001_SendEEPROMDataEOL: 8 Vector__XXX
  SG_ M001_SendEEPROMDataEOL_Mux M : 0|32@1+ (1,0) [0|4294967295] "" Vector__XXX
  SG_ M001_conf_A_CurrentFactorA_mA m1522226602 : 32|32@1- (1,0) [-2147483648|2147483647] "mA" Vector__XXX
  SG_ M001_conf_A_CurrentFactorB_mA m2147483647 : 32|32@1- (1,0) [-2147483648|2147483647] "mA" Vector__XXX
  SG_ M001_conf_A_CurrentOffsetA_mA m1509971370 : 32|32@1- (1,0) [-2147483648|2147483647] "mA" Vector__XXX
  SG_ M001_conf_A_CurrentOffsetB_mA m1515869610 : 32|32@1- (1,0) [-2147483648|2147483647] "mA" Vector__XXX
  SG_ M001_conf_IdxOfTempSensor m5920170 : 32|16@1+ (1,0) [0|65535] "" Vector__XXX
  SG_ M001_conf_NewCellTypeMajor m2147483647 : 32|8@1+ (1,0) [0|255] "" Vector__XXX
  SG_ M001_conf_NewCellTypeMinor m2147483647 : 40|8@1+ (1,0) [0|255] "" Vector__XXX
  SG_ M001_conf_NewICTypeMajor m2147483647 : 32|8@1+ (1,0) [0|255] "" Vector__XXX
  SG_ M001_conf_NewICTypeMinor m2147483647 : 40|8@1+ (1,0) [0|255] "" Vector__XXX
  SG_ M001_conf_NewModuleTypeMajor m2147483647 : 32|8@1+ (1,0) [0|255] "" Vector__XXX
  SG_ M001_conf_NewModuleTypeMinor m2147483647 : 40|8@1+ (1,0) [0|255] "" Vector__XXX
  SG_ M001_conf_NewPCBTypeMajor m298756693 : 32|8@1+ (1,0) [0|255] "" Vector__XXX
  SG_ M001_conf_NewPCBTypeMinor m298756693 : 40|8@1+ (1,0) [0|255] "" Vector__XXX
  SG_ M001_conf_NewSerialNrHi m2147483647 : 32|32@1+ (1,0) [0|4294967295] "" Vector__XXX
  SG_ M001_conf_NewSerialNrLo m2147483647 : 32|32@1+ (1,0) [0|4294967295] "" Vector__XXX
  SG_ M001_conf_PCBNewSerialNrHi m218999381 : 32|32@1+ (1,0) [0|4294967295] "" Vector__XXX
  SG_ M001_conf_PCBNewSerialNrLo m2147483647 : 32|32@1+ (1,0) [0|4294967295] "" Vector__XXX
  SG_ M001_conf_RefTemperature_C m5920170 : 52|12@1- (0.10000000000000000555,0) [-204.80000000000001137|204.69999999999998863] "°C" Vector__XXX
  SG_ M001_conf_TopologyMajor m2147483647 : 32|8@1+ (1,0) [0|255] "" Vector__XXX
  SG_ M001_conf_TopologyMinor m2147483647 : 40|8@1+ (1,0) [0|255] "" Vector__XXX
  SG_ M001_conf_U_VoltageIC1_mV m2147483647 : 32|32@1+ (1,0) [0|4294967295] "mV" Vector__XXX
  SG_ M001_conf_U_VoltageIC2_mV m1527469482 : 32|32@1+ (1,0) [0|4294967295] "mV" Vector__XXX
  SG_ M001_conf_U_VoltageIC3_mV m2147483647 : 32|32@1+ (1,0) [0|4294967295] "mV" Vector__XXX
  SG_ M001_conf_U_VoltageIC4_mV m1522161066 : 32|32@1+ (1,0) [0|4294967295] "mV" Vector__XXX

BO_ 2415945729 M001_SlaveSerials: 8 Vector__XXX
  SG_ M001_Aka_FunctionArea_E m1 : 58|4@1+ (1,0) [0|15] "" Vector__XXX
  SG_ M001_Aka_FunctionArea_P m0 : 58|4@1+ (1,0) [0|15] "" Vector__XXX
  SG_ M001_Aka_Line m0 : 31|7@1+ (1,0) [0|127] "" Vector__XXX
  SG_ M001_Aka_Los_No_E m1 : 0|13@1+ (1,0) [0|8191] "" Vector__XXX
  SG_ M001_Aka_Los_No_P m0 : 0|31@1+ (1,0) [0|2147483647] "" Vector__XXX
  SG_ M001_Aka_Module m1 : 31|14@1+ (1,0) [0|16383] "" Vector__XXX
  SG_ M001_Aka_Plant m0 : 38|7@1+ (1,0) [0|127] "" Vector__XXX
  SG_ M001_Aka_Supplier m1 : 14|10@1+ (1,0) [0|1023] "" Vector__XXX
  SG_ M001_Aka_Version m1 : 24|7@1+ (1,0) [0|127] "" Vector__XXX
  SG_ M001_Aka_Week_E m1 : 45|6@1+ (1,0) [0|63] "" Vector__XXX
  SG_ M001_Aka_Week_P m0 : 45|6@1+ (1,0) [0|63] "" Vector__XXX
  SG_ M001_Aka_Year_E m1 : 51|7@1+ (1,0) [0|127] "" Vector__XXX
  SG_ M001_Aka_Year_P m0 : 51|7@1+ (1,0) [0|127] "" Vector__XXX
  SG_ M001_SlaveSerials_Mux M : 62|2@1+ (1,0) [0|4294967295] "" Vector__XXX

BO_ 2416478209 M001_StartLTCTransmission: 8 Vector__XXX
  SG_ M001_val_ActionIndex : 24|8@1+ (1,0) [0|255] "" Vector__XXX
  SG_ M001_val_Magic : 0|24@1+ (1,0) [0|16777215] "" Vector__XXX

BO_ 2415925249 M001_TerminalTemperatures: 8 Vector__XXX
  SG_ M001_act_T_TermTempNeg_C : 32|16@1- (0.010000000000000000208,0) [-327.68000000000000682|327.67000000000001592] "°C" Vector__XXX
  SG_ M001_act_T_TermTempPos_C : 48|16@1- (0.010000000000000000208,0) [-327.68000000000000682|327.67000000000001592] "°C" Vector__XXX
  SG_ M001_raw_DewSens : 16|16@1+ (0.10000000000000000555,0) [0|6553.5] "mV" Vector__XXX

BO_ 2415978497 M001_UnderVoltageFlags: 8 Vector__XXX
  SG_ M001_flag_UndervoltageCell1 : 0|1@1+ (1,0) [0|1] "" Vector__XXX
  SG_ M001_flag_UndervoltageCell10 : 9|1@1+ (1,0) [0|1] "" Vector__XXX
  SG_ M001_flag_UndervoltageCell11 : 10|1@1+ (1,0) [0|1] "" Vector__XXX
  SG_ M001_flag_UndervoltageCell12 : 11|1@1+ (1,0) [0|1] "" Vector__XXX
  SG_ M001_flag_UndervoltageCell13 : 12|1@1+ (1,0) [0|1] "" Vector__XXX
  SG_ M001_flag_UndervoltageCell14 : 13|1@1+ (1,0) [0|1] "" Vector__XXX
  SG_ M001_flag_UndervoltageCell15 : 14|1@1+ (1,0) [0|1] "" Vector__XXX
  SG_ M001_flag_UndervoltageCell16 : 15|1@1+ (1,0) [0|1] "" Vector__XXX
  SG_ M001_flag_UndervoltageCell17 : 16|1@1+ (1,0) [0|1] "" Vector__XXX
  SG_ M001_flag_UndervoltageCell18 : 17|1@1+ (1,0) [0|1] "" Vector__XXX
  SG_ M001_flag_UndervoltageCell19 : 18|1@1+ (1,0) [0|1] "" Vector__XXX
  SG_ M001_flag_UndervoltageCell2 : 1|1@1+ (1,0) [0|1] "" Vector__XXX
  SG_ M001_flag_UndervoltageCell20 : 19|1@1+ (1,0) [0|1] "" Vector__XXX
  SG_ M001_flag_UndervoltageCell21 : 20|1@1+ (1,0) [0|1] "" Vector__XXX
  SG_ M001_flag_UndervoltageCell22 : 21|1@1+ (1,0) [0|1] "" Vector__XXX
  SG_ M001_flag_UndervoltageCell23 : 22|1@1+ (1,0) [0|1] "" Vector__XXX
  SG_ M001_flag_UndervoltageCell24 : 23|1@1+ (1,0) [0|1] "" Vector__XXX
  SG_ M001_flag_UndervoltageCell25 : 24|1@1+ (1,0) [0|1] "" Vector__XXX
  SG_ M001_flag_UndervoltageCell26 : 25|1@1+ (1,0) [0|1] "" Vector__XXX
  SG_ M001_flag_UndervoltageCell27 : 26|1@1+ (1,0) [0|1] "" Vector__XXX
  SG_ M001_flag_UndervoltageCell28 : 27|1@1+ (1,0) [0|1] "" Vector__XXX
  SG_ M001_flag_UndervoltageCell29 : 28|1@1+ (1,0) [0|1] "" Vector__XXX
  SG_ M001_flag_UndervoltageCell3 : 2|1@1+ (1,0) [0|1] "" Vector__XXX
  SG_ M001_flag_UndervoltageCell30 : 29|1@1+ (1,0) [0|1] "" Vector__XXX
  SG_ M001_flag_UndervoltageCell31 : 30|1@1+ (1,0) [0|1] "" Vector__XXX
  SG_ M001_flag_UndervoltageCell32 : 31|1@1+ (1,0) [0|1] "" Vector__XXX
  SG_ M001_flag_UndervoltageCell33 : 32|1@1+ (1,0) [0|1] "" Vector__XXX
  SG_ M001_flag_UndervoltageCell34 : 33|1@1+ (1,0) [0|1] "" Vector__XXX
  SG_ M001_flag_UndervoltageCell35 : 34|1@1+ (1,0) [0|1] "" Vector__XXX
  SG_ M001_flag_UndervoltageCell36 : 35|1@1+ (1,0) [0|1] "" Vector__XXX
  SG_ M001_flag_UndervoltageCell37 : 36|1@1+ (1,0) [0|1] "" Vector__XXX
  SG_ M001_flag_UndervoltageCell38 : 37|1@1+ (1,0) [0|1] "" Vector__XXX
  SG_ M001_flag_UndervoltageCell39 : 38|1@1+ (1,0) [0|1] "" Vector__XXX
  SG_ M001_flag_UndervoltageCell4 : 3|1@1+ (1,0) [0|1] "" Vector__XXX
  SG_ M001_flag_UndervoltageCell40 : 39|1@1+ (1,0) [0|1] "" Vector__XXX
  SG_ M001_flag_UndervoltageCell5 : 4|1@1+ (1,0) [0|1] "" Vector__XXX
  SG_ M001_flag_UndervoltageCell6 : 5|1@1+ (1,0) [0|1] "" Vector__XXX
  SG_ M001_flag_UndervoltageCell7 : 6|1@1+ (1,0) [0|1] "" Vector__XXX
  SG_ M001_flag_UndervoltageCell8 : 7|1@1+ (1,0) [0|1] "" Vector__XXX
  SG_ M001_flag_UndervoltageCell9 : 8|1@1+ (1,0) [0|1] "" Vector__XXX

BO_ 2416474113 M001_WriteEEPROMData: 8 Vector__XXX
  SG_ M001_WriteEEPROMData_Mux M : 0|24@1+ (1,0) [0|4294967295] "" Vector__XXX
  SG_ M001_val_EEPROMWriteData : 32|32@1+ (1,0) [0|4294967295] "" Vector__XXX
  SG_ M001_val_EEPROMWriteIndex : 24|8@1+ (1,0) [0|255] "" Vector__XXX

BO_ 2449544193 SCU1_AkaSerialNo: 8 Vector__XXX
  SG_ SCU1_AkaSerialNo_Mux M : 58|4@1+ (1,0) [0|4294967295] "" Vector__XXX
  SG_ SCU1_Aka_BuildUserNr m3 : 14|7@1+ (1,0) [0|127] "" Vector__XXX
  SG_ SCU1_Aka_Build_No m3 : 21|10@1+ (1,0) [0|1023] "" Vector__XXX
  SG_ SCU1_Aka_Line m0 : 31|7@1+ (1,0) [0|127] "" Vector__XXX
  SG_ SCU1_Aka_Los_No_E m1 : 0|13@1+ (1,0) [0|8191] "" Vector__XXX
  SG_ SCU1_Aka_Los_No_P m0 : 0|31@1+ (1,0) [0|2147483647] "" Vector__XXX
  SG_ SCU1_Aka_Major m3 : 38|7@1+ (1,0) [0|127] "" Vector__XXX
  SG_ SCU1_Aka_Minor m3 : 31|7@1+ (1,0) [0|127] "" Vector__XXX
  SG_ SCU1_Aka_Module m1 : 31|14@1+ (1,0) [0|16383] "" Vector__XXX
  SG_ SCU1_Aka_Plant m0 : 38|7@1+ (1,0) [0|127] "" Vector__XXX
  SG_ SCU1_Aka_SWVariant m3 : 0|14@1+ (1,0) [0|16383] "" Vector__XXX
  SG_ SCU1_Aka_Supplier m1 : 14|10@1+ (1,0) [0|1023] "" Vector__XXX
  SG_ SCU1_Aka_Version m1 : 24|7@1+ (1,0) [0|127] "" Vector__XXX
  SG_ SCU1_Aka_Week_E m1 : 45|6@1+ (1,0) [0|63] "" Vector__XXX
  SG_ SCU1_Aka_Week_P m0 : 45|6@1+ (1,0) [0|63] "" Vector__XXX
  SG_ SCU1_Aka_Week_S m3 : 45|6@1+ (1,0) [0|63] "" Vector__XXX
  SG_ SCU1_Aka_Year_E m1 : 51|7@1+ (1,0) [0|127] "" Vector__XXX
  SG_ SCU1_Aka_Year_P m0 : 51|7@1+ (1,0) [0|127] "" Vector__XXX
  SG_ SCU1_Aka_Year_S m3 : 51|7@1+ (1,0) [0|127] "" Vector__XXX

BO_ 2449527809 SCU1_Alarm: 8 Vector__XXX
  SG_ SCU1_af_AfterrunTest : 40|1@1+ (1,0) [0|1] "" Vector__XXX
  SG_ SCU1_af_BMMBattCom : 29|1@1+ (1,0) [0|1] "" Vector__XXX
  SG_ SCU1_af_BoardTemp : 61|1@1+ (1,0) [0|1] "" Vector__XXX
  SG_ SCU1_af_CPUSupplyWarning : 56|1@1+ (1,0) [0|1] "" Vector__XXX
  SG_ SCU1_af_CellTempChargMax : 16|1@1+ (1,0) [0|1] "" Vector__XXX
  SG_ SCU1_af_CellTempChargMin : 17|1@1+ (1,0) [0|1] "" Vector__XXX
  SG_ SCU1_af_CellTempDischMax : 18|1@1+ (1,0) [0|1] "" Vector__XXX
  SG_ SCU1_af_CellTempDischMin : 19|1@1+ (1,0) [0|1] "" Vector__XXX
  SG_ SCU1_af_CellTempUnbalance : 37|1@1+ (1,0) [0|1] "" Vector__XXX
  SG_ SCU1_af_CellVoltUnbalance : 36|1@1+ (1,0) [0|1] "" Vector__XXX
  SG_ SCU1_af_CellVoltageMax : 0|1@1+ (1,0) [0|1] "" Vector__XXX
  SG_ SCU1_af_CellVoltageMin : 1|1@1+ (1,0) [0|1] "" Vector__XXX
  SG_ SCU1_af_ContDam : 51|1@1+ (1,0) [0|1] "" Vector__XXX
  SG_ SCU1_af_ContactorDropOut : 60|1@1+ (1,0) [0|1] "" Vector__XXX
  SG_ SCU1_af_ContactorNegStuck : 10|1@1+ (1,0) [0|1] "" Vector__XXX
  SG_ SCU1_af_ContactorPosStuck : 11|1@1+ (1,0) [0|1] "" Vector__XXX
  SG_ SCU1_af_ContactorWrongState : 49|1@1+ (1,0) [0|1] "" Vector__XXX
  SG_ SCU1_af_CrossCheck : 41|1@1+ (1,0) [0|1] "" Vector__XXX
  SG_ SCU1_af_CurrSens : 50|1@1+ (1,0) [0|1] "" Vector__XXX
  SG_ SCU1_af_DeepDischProt : 32|1@1+ (1,0) [0|1] "" Vector__XXX
  SG_ SCU1_af_Dew_Sensor : 59|1@1+ (1,0) [0|1] "" Vector__XXX
  SG_ SCU1_af_ExtCommunicationTout : 34|1@1+ (1,0) [0|1] "" Vector__XXX
  SG_ SCU1_af_FlashEEPROM : 47|1@1+ (1,0) [0|1] "" Vector__XXX
  SG_ SCU1_af_HVCurrLoopMax : 22|1@1+ (1,0) [0|1] "" Vector__XXX
  SG_ SCU1_af_HVCurrLoopMin : 23|1@1+ (1,0) [0|1] "" Vector__XXX
  SG_ SCU1_af_InvalidData : 48|1@1+ (1,0) [0|1] "" Vector__XXX
  SG_ SCU1_af_IsoFaultBattNeg : 8|1@1+ (1,0) [0|1] "" Vector__XXX
  SG_ SCU1_af_IsoFaultBattPos : 9|1@1+ (1,0) [0|1] "" Vector__XXX
  SG_ SCU1_af_KL30SafeMax : 54|1@1+ (1,0) [0|1] "" Vector__XXX
  SG_ SCU1_af_KL30SafeMin : 55|1@1+ (1,0) [0|1] "" Vector__XXX
  SG_ SCU1_af_KL30SafeOff : 58|1@1+ (1,0) [0|1] "" Vector__XXX
  SG_ SCU1_af_LTCError : 39|1@1+ (1,0) [0|1] "" Vector__XXX
  SG_ SCU1_af_LVSupplyMax : 12|1@1+ (1,0) [0|1] "" Vector__XXX
  SG_ SCU1_af_LVSupplyMin : 13|1@1+ (1,0) [0|1] "" Vector__XXX
  SG_ SCU1_af_ModVoltageRefMax : 6|1@1+ (1,0) [0|1] "" Vector__XXX
  SG_ SCU1_af_ModVoltageSum : 5|1@1+ (1,0) [0|1] "" Vector__XXX
  SG_ SCU1_af_Mod_Voltage_Ref_Min : 7|1@1+ (1,0) [0|1] "" Vector__XXX
  SG_ SCU1_af_NoAfterrunTest : 35|1@1+ (1,0) [0|1] "" Vector__XXX
  SG_ SCU1_af_PowerProtectionWarning : 57|1@1+ (1,0) [0|1] "" Vector__XXX
  SG_ SCU1_af_ProgProcess : 44|1@1+ (1,0) [0|1] "" Vector__XXX
  SG_ SCU1_af_RAM : 45|1@1+ (1,0) [0|1] "" Vector__XXX
  SG_ SCU1_af_ROM : 46|1@1+ (1,0) [0|1] "" Vector__XXX
  SG_ SCU1_af_RefVoltErrorMax : 52|1@1+ (1,0) [0|1] "" Vector__XXX
  SG_ SCU1_af_RefVoltErrorMin : 53|1@1+ (1,0) [0|1] "" Vector__XXX
  SG_ SCU1_af_SCUConfig : 31|1@1+ (1,0) [0|1] "" Vector__XXX
  SG_ SCU1_af_SCUError : 63|1@1+ (1,0) [0|1] "" Vector__XXX
  SG_ SCU1_af_StuckAtTemp : 42|1@1+ (1,0) [0|1] "" Vector__XXX
  SG_ SCU1_af_StuckAtVolt : 43|1@1+ (1,0) [0|1] "" Vector__XXX
  SG_ SCU1_af_SysCurCha : 20|1@1+ (1,0) [0|1] "" Vector__XXX
  SG_ SCU1_af_SysCurDis : 21|1@1+ (1,0) [0|1] "" Vector__XXX
  SG_ SCU1_af_SysCurLimitCha : 26|1@1+ (1,0) [0|1] "" Vector__XXX
  SG_ SCU1_af_SysCurLimitDis : 27|1@1+ (1,0) [0|1] "" Vector__XXX
  SG_ SCU1_af_SysInitTimeout : 30|1@1+ (1,0) [0|1] "" Vector__XXX
  SG_ SCU1_af_SysPrechargeFailed : 28|1@1+ (1,0) [0|1] "" Vector__XXX
  SG_ SCU1_af_SysVoltageMax : 2|1@1+ (1,0) [0|1] "" Vector__XXX
  SG_ SCU1_af_SysVoltageMin : 3|1@1+ (1,0) [0|1] "" Vector__XXX
  SG_ SCU1_af_SysVoltageSum : 4|1@1+ (1,0) [0|1] "" Vector__XXX
  SG_ SCU1_af_TerminalTempMax : 14|1@1+ (1,0) [0|1] "" Vector__XXX
  SG_ SCU1_af_TerminalTempMin : 15|1@1+ (1,0) [0|1] "" Vector__XXX
  SG_ SCU1_af_TerminalTempUnbalance : 38|1@1+ (1,0) [0|1] "" Vector__XXX
  SG_ SCU1_af_WDReset : 33|1@1+ (1,0) [0|1] "" Vector__XXX
  SG_ SCU1_af_eStopCurrLoopMax : 24|1@1+ (1,0) [0|1] "" Vector__XXX
  SG_ SCU1_af_eStopCurrLoopMin : 25|1@1+ (1,0) [0|1] "" Vector__XXX

BO_ 2449568769 SCU1_AmpereHourCounter: 8 Vector__XXX
  SG_ SCU1_ctr_Q_AmpereHourChg_Ah : 0|32@1+ (0.010000000000000000208,0) [0|42949672.95000000298] "Ah" Vector__XXX
  SG_ SCU1_ctr_Q_AmpereHourDisch_Ah : 32|32@1+ (0.010000000000000000208,0) [0|42949672.95000000298] "Ah" Vector__XXX

BO_ 2315318273 SCU1_BatteryVoltagesNeg: 8 Vector__XXX
  SG_ SCU1_act_U_BatNeg_V : 0|16@1- (0.10000000000000000555,0) [-3276.8000000000001819|3276.6999999999998181] "V" Vector__XXX
  SG_ SCU1_act_U_SysNeg_V : 16|16@1- (0.10000000000000000555,0) [-3276.8000000000001819|3276.6999999999998181] "V" Vector__XXX

BO_ 2315314177 SCU1_BatteryVoltagesPos: 8 Vector__XXX
  SG_ SCU1_act_U_BatPos_V : 0|16@1- (0.10000000000000000555,0) [-3276.8000000000001819|3276.6999999999998181] "V" Vector__XXX
  SG_ SCU1_act_U_SysPos_V : 16|16@1- (0.10000000000000000555,0) [-3276.8000000000001819|3276.6999999999998181] "V" Vector__XXX

BO_ 2449585153 SCU1_Board_Supply_Vtg1: 8 Vector__XXX
  SG_ SCU1_6Vneg : 48|16@1- (1,0) [-32768|32767] "mV" Vector__XXX
  SG_ SCU1_6Vpos : 32|16@1- (1,0) [-32768|32767] "mV" Vector__XXX
  SG_ SCU1_pos5V_LEM1A : 0|16@1- (1,0) [-32768|32767] "mV" Vector__XXX
  SG_ SCU1_pos5V_LEM1B : 16|16@1- (1,0) [-32768|32767] "mV" Vector__XXX

BO_ 2449589249 SCU1_Board_Supply_Vtg2: 8 Vector__XXX
  SG_ SCU1_pos5V : 0|16@1- (1,0) [-32768|32767] "mV" Vector__XXX

BO_ 2449490945 SCU1_ContactorCoilCurrents: 8 Vector__XXX
  SG_ SCU1_act_I_CoilCurrContAux_mA : 48|16@1+ (1,0) [0|65535] "mA" Vector__XXX
  SG_ SCU1_act_I_CoilCurrContNeg_mA : 16|16@1+ (1,0) [0|65535] "mA" Vector__XXX
  SG_ SCU1_act_I_CoilCurrContPos_mA : 0|16@1+ (1,0) [0|65535] "mA" Vector__XXX
  SG_ SCU1_act_I_CoilCurrContPre_mA : 32|16@1+ (1,0) [0|65535] "mA" Vector__XXX

BO_ 2315342849 SCU1_ContactorDmg: 8 Vector__XXX
  SG_ SCU1_ctr_ContOperational_s : 32|32@1+ (1,0) [0|4294967295] "" Vector__XXX
  SG_ SCU1_ctr_DamageTotal : 0|32@1+ (1,0) [0|4294967295] "" Vector__XXX

BO_ 2315277313 SCU1_Currents: 8 Vector__XXX
  SG_ SCU1_act_I_CurrentSens2High_A : 32|16@1- (0.10000000000000000555,0) [-3276.8000000000001819|3276.6999999999998181] "A" Vector__XXX
  SG_ SCU1_act_I_CurrentSens2Low_A : 48|16@1- (0.10000000000000000555,0) [-3276.8000000000001819|3276.6999999999998181] "A" Vector__XXX
  SG_ SCU1_act_I_CurrentSensHigh_A : 0|16@1- (0.10000000000000000555,0) [-3276.8000000000001819|3276.6999999999998181] "A" Vector__XXX
  SG_ SCU1_act_I_CurrentSensLow_A : 16|16@1- (0.10000000000000000555,0) [-3276.8000000000001819|3276.6999999999998181] "A" Vector__XXX

BO_ 2449519617 SCU1_ErrorInfo: 8 Vector__XXX
  SG_ SCU1_err_Level : 16|16@1+ (1,0) [0|65535] "" Vector__XXX
  SG_ SCU1_err_Number : 0|16@1+ (1,0) [0|65535] "" Vector__XXX
  SG_ SCU1_err_Source : 48|16@1+ (1,0) [0|65535] "" Vector__XXX
  SG_ SCU1_err_Value : 32|16@1- (1,0) [-32768|32767] "" Vector__XXX

BO_ 2451055617 SCU1_HSSwitchReq: 8 Vector__XXX
  SG_ SCU1_req_HSOutput1_pct : 0|8@1+ (1,0) [0|255] "%" Vector__XXX
  SG_ SCU1_req_HSOutput2_pct : 8|8@1+ (1,0) [0|255] "%" Vector__XXX
  SG_ SCU1_req_HSOutput3_pct : 16|8@1+ (1,0) [0|255] "%" Vector__XXX
  SG_ SCU1_req_HSOutput4_pct : 24|8@1+ (1,0) [0|255] "%" Vector__XXX

BO_ 2449486849 SCU1_HighsideSwitchCurrents: 8 Vector__XXX
  SG_ SCU1_act_I_HSSwitch1Curr_mA : 0|16@1+ (1,0) [0|65535] "mA" Vector__XXX
  SG_ SCU1_act_I_HSSwitch2Curr_mA : 16|16@1+ (1,0) [0|65535] "mA" Vector__XXX
  SG_ SCU1_act_I_HSSwitch3Curr_mA : 32|16@1+ (1,0) [0|65535] "mA" Vector__XXX
  SG_ SCU1_act_I_HSSwitch4Curr_mA : 48|16@1+ (1,0) [0|65535] "mA" Vector__XXX

BO_ 2449482753 SCU1_HighsideSwitchStatus: 8 Vector__XXX
  SG_ SCU1_act_HighsideSwitch1_pct : 0|8@1+ (1,0) [0|255] "%" Vector__XXX
  SG_ SCU1_act_HighsideSwitch2_pct : 8|8@1+ (1,0) [0|255] "%" Vector__XXX
  SG_ SCU1_act_HighsideSwitch3_pct : 16|8@1+ (1,0) [0|255] "%" Vector__XXX
  SG_ SCU1_act_HighsideSwitch4_pct : 24|8@1+ (1,0) [0|255] "%" Vector__XXX

BO_ 2449576961 SCU1_Histogramm: 8 Vector__XXX
  SG_ SCU1_diag_HistIndex : 8|8@1+ (1,0) [0|255] "" Vector__XXX
  SG_ SCU1_diag_HistIndexWert : 16|16@1- (1,0) [-32768|32767] "" Vector__XXX
  SG_ SCU1_diag_HistMultiplex : 0|8@1+ (1,0) [0|255] "" Vector__XXX
  SG_ SCU1_diag_HistWerte : 32|32@1+ (1,0) [0|4294967295] "" Vector__XXX

BO_ 2449593345 SCU1_HwConf_Adr_Vtg: 8 Vector__XXX
  SG_ SCU1_Adr4 : 0|16@1+ (1,0) [0|65535] "mV" Vector__XXX
  SG_ SCU1_Adr5 : 16|16@1+ (1,0) [0|65535] "mV" Vector__XXX
  SG_ SCU1_HWConf0 : 32|16@1+ (1,0) [0|65535] "mV" Vector__XXX
  SG_ SCU1_HWConf1 : 48|16@1+ (1,0) [0|65535] "mV" Vector__XXX

BO_ 2449515521 SCU1_IsoContStuckVoltages: 8 Vector__XXX
  SG_ SCU1_diag_U_TrayNegExt_U_frz : 16|16@1- (0.10000000000000000555,0) [-3276.8000000000001819|3276.6999999999998181] "V" Vector__XXX
  SG_ SCU1_diag_U_TrayNegInt_U_frz : 48|16@1- (0.10000000000000000555,0) [-3276.8000000000001819|3276.6999999999998181] "V" Vector__XXX
  SG_ SCU1_diag_U_TrayPosExt_U_frz : 0|16@1- (0.10000000000000000555,0) [-3276.8000000000001819|3276.6999999999998181] "V" Vector__XXX
  SG_ SCU1_diag_U_TrayPosInt_U_frz : 32|16@1- (0.10000000000000000555,0) [-3276.8000000000001819|3276.6999999999998181] "V" Vector__XXX

BO_ 2449552385 SCU1_LimitConfigInfo: 8 Vector__XXX
  SG_ SCU1_lim_T_MaxTemp_C : 48|16@1- (0.10000000000000000555,0) [-3276.8000000000001819|3276.6999999999998181] "T" Vector__XXX
  SG_ SCU1_lim_T_MinTemp_C : 32|16@1- (0.10000000000000000555,0) [-3276.8000000000001819|3276.6999999999998181] "T" Vector__XXX
  SG_ SCU1_lim_U_MaxVolt_V : 16|16@1+ (0.0010000000000000000208,0) [0|65.534999999999996589] "V" Vector__XXX
  SG_ SCU1_lim_U_MinVolt_V : 0|16@1+ (0.0010000000000000000208,0) [0|65.534999999999996589] "V" Vector__XXX

BO_ 2449536001 SCU1_LoopCurrents: 8 Vector__XXX
  SG_ SCU1_act_I_CurrentSensTot_A : 32|16@1- (0.10000000000000000555,0) [-3276.8000000000001819|3276.6999999999998181] "A" Vector__XXX
  SG_ SCU1_act_I_HVIL_mA : 0|16@1- (0.10000000000000000555,0) [-3276.8000000000001819|3276.6999999999998181] "mA" Vector__XXX
  SG_ SCU1_act_I_eStop_mA : 16|16@1- (0.10000000000000000555,0) [-3276.8000000000001819|3276.6999999999998181] "mA" Vector__XXX

BO_ 2449503233 SCU1_OperatingVoltages: 8 Vector__XXX
  SG_ SCU1_act_U_BMMSafe_V : 16|16@1+ (0.0010000000000000000208,0) [0|65.534999999999996589] "V" Vector__XXX
  SG_ SCU1_act_U_Contact30_V : 0|16@1+ (0.0010000000000000000208,0) [0|65.534999999999996589] "V" Vector__XXX
  SG_ SCU1_act_U_HSSupply12_V : 32|16@1+ (0.0010000000000000000208,0) [0|65.534999999999996589] "V" Vector__XXX
  SG_ SCU1_act_U_HSSupply34_V : 48|16@1+ (0.0010000000000000000208,0) [0|65.534999999999996589] "V" Vector__XXX

BO_ 2449564673 SCU1_OperationTimeCounter: 8 Vector__XXX
  SG_ SCU1_ctr_t_AliveTime_s : 0|32@1+ (1,0) [0|4294967295] "s" Vector__XXX
  SG_ SCU1_ctr_t_OperationTime_s : 32|32@1+ (1,0) [0|4294967295] "s" Vector__XXX

BO_ 2651063297 SCU1_RAWErrorValues: 8 Vector__XXX
  SG_ SCU1_raw_ErrorCodePosition : 48|16@1+ (1,0) [0|65535] "" Vector__XXX
  SG_ SCU1_raw_ErrorNumber : 0|16@1+ (1,0) [0|65535] "" Vector__XXX
  SG_ SCU1_raw_ErrorParameter1 : 16|16@1+ (1,0) [0|65535] "" Vector__XXX
  SG_ SCU1_raw_ErrorParameter2 : 32|16@1+ (1,0) [0|65535] "" Vector__XXX

BO_ 2651067393 SCU1_RAWValues1: 8 Vector__XXX
  SG_ SCU1_raw_BMMSafeVoltage : 16|16@1+ (1,0) [0|65535] "digit" Vector__XXX
  SG_ SCU1_raw_HSS12Voltage : 32|16@1+ (1,0) [0|65535] "digit" Vector__XXX
  SG_ SCU1_raw_KL30Voltage : 0|16@1+ (1,0) [0|65535] "digit" Vector__XXX
  SG_ SCU1_raw_ReferenceVoltage : 48|16@1+ (1,0) [0|65535] "digit" Vector__XXX

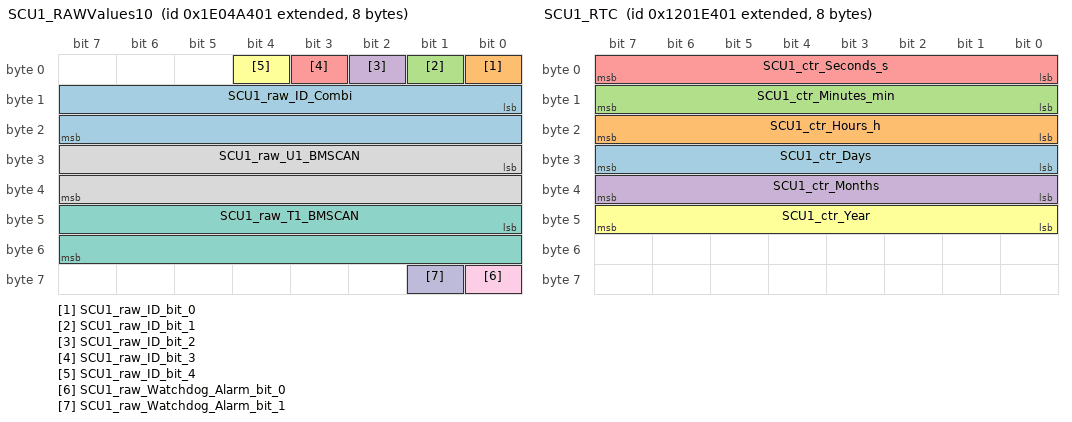
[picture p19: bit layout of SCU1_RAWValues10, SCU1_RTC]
BO_ 2651104257 SCU1_RAWValues10: 8 Vector__XXX
  SG_ SCU1_raw_ID_Combi : 8|16@1+ (1,0) [0|65535] "" Vector__XXX
  SG_ SCU1_raw_ID_bit_0 : 0|1@1+ (1,0) [0|1] "" Vector__XXX
  SG_ SCU1_raw_ID_bit_1 : 1|1@1+ (1,0) [0|1] "" Vector__XXX
  SG_ SCU1_raw_ID_bit_2 : 2|1@1+ (1,0) [0|1] "" Vector__XXX
  SG_ SCU1_raw_ID_bit_3 : 3|1@1+ (1,0) [0|1] "" Vector__XXX
  SG_ SCU1_raw_ID_bit_4 : 4|1@1+ (1,0) [0|1] "" Vector__XXX
  SG_ SCU1_raw_T1_BMSCAN : 40|16@1- (1,0) [-32768|32767] "" Vector__XXX
  SG_ SCU1_raw_U1_BMSCAN : 24|16@1- (1,0) [-32768|32767] "" Vector__XXX
  SG_ SCU1_raw_Watchdog_Alarm_bit_0 : 56|1@1+ (1,0) [0|1] "" Vector__XXX
  SG_ SCU1_raw_Watchdog_Alarm_bit_1 : 57|1@1+ (1,0) [0|1] "" Vector__XXX

BO_ 2651071489 SCU1_RAWValues2: 8 Vector__XXX
  SG_ SCU1_raw_HSS34Voltage : 0|16@1+ (1,0) [0|65535] "digit" Vector__XXX
  SG_ SCU1_raw_TrayBatVoltNeg : 32|16@1+ (1,0) [0|65535] "digit" Vector__XXX
  SG_ SCU1_raw_TrayBatVoltPos : 16|16@1+ (1,0) [0|65535] "digit" Vector__XXX
  SG_ SCU1_raw_TraySysVoltPos : 48|16@1+ (1,0) [0|65535] "digit" Vector__XXX

BO_ 2651075585 SCU1_RAWValues3: 8 Vector__XXX
  SG_ SCU1_raw_ExtSense1 : 32|16@1+ (1,0) [0|65535] "digit" Vector__XXX
  SG_ SCU1_raw_ExtSense2 : 48|16@1+ (1,0) [0|65535] "digit" Vector__XXX
  SG_ SCU1_raw_TrayGndVolt : 16|16@1+ (1,0) [0|65535] "digit" Vector__XXX
  SG_ SCU1_raw_TraySysVoltNeg : 0|16@1+ (1,0) [0|65535] "digit" Vector__XXX

BO_ 2651079681 SCU1_RAWValues4: 8 Vector__XXX
  SG_ SCU1_raw_ContExtAuxCoilCurr : 48|16@1+ (1,0) [0|65535] "digit" Vector__XXX
  SG_ SCU1_raw_ContNegCoilCurr : 16|16@1+ (1,0) [0|65535] "digit" Vector__XXX
  SG_ SCU1_raw_ContPosCoilCurr : 0|16@1+ (1,0) [0|65535] "digit" Vector__XXX
  SG_ SCU1_raw_ContPreCoilCurr : 32|16@1+ (1,0) [0|65535] "digit" Vector__XXX

BO_ 2651083777 SCU1_RAWValues5: 8 Vector__XXX
  SG_ SCU1_raw_ILockLoopCurr : 48|16@1+ (1,0) [0|65535] "digit" Vector__XXX
  SG_ SCU1_raw_ISenseHighCurr : 16|16@1+ (1,0) [0|65535] "digit" Vector__XXX
  SG_ SCU1_raw_ISenseLowCurr : 0|16@1+ (1,0) [0|65535] "digit" Vector__XXX
  SG_ SCU1_raw_eStopLoopCurr : 32|16@1+ (1,0) [0|65535] "digit" Vector__XXX

BO_ 2651087873 SCU1_RAWValues6: 8 Vector__XXX
  SG_ SCU1_raw_HSSwitch1Curr : 0|16@1+ (1,0) [0|65535] "digit" Vector__XXX
  SG_ SCU1_raw_HSSwitch2Curr : 16|16@1+ (1,0) [0|65535] "digit" Vector__XXX
  SG_ SCU1_raw_HSSwitch3Curr : 32|16@1+ (1,0) [0|65535] "digit" Vector__XXX
  SG_ SCU1_raw_HSSwitch4Curr : 48|16@1+ (1,0) [0|65535] "digit" Vector__XXX

BO_ 2651091969 SCU1_RAWValues7: 8 Vector__XXX
  SG_ SCU1_raw_CPULoadAvg : 0|16@1+ (0.10000000000000000555,0) [0|6553.5] "%" Vector__XXX
  SG_ SCU1_raw_CPULoadMax : 48|16@1+ (0.10000000000000000555,0) [0|6553.5] "%" Vector__XXX
  SG_ SCU1_raw_TrayTemp : 32|16@1+ (1,0) [0|65535] "digit" Vector__XXX
  SG_ SCU1_raw_TrayVoltage : 16|16@1+ (1,0) [0|65535] "digit" Vector__XXX

BO_ 2651096065 SCU1_RAWValues8: 8 Vector__XXX
  SG_ SCU1_raw_ActOffsetIHighChannel : 48|16@1+ (1,0) [0|65535] "" Vector__XXX
  SG_ SCU1_raw_HysteresisOffset : 16|16@1+ (1,0) [0|65535] "" Vector__XXX
  SG_ SCU1_raw_MagneticMarker : 0|16@1+ (1,0) [0|65535] "" Vector__XXX
  SG_ SCU1_raw_NonOffsetIHighChannel : 32|16@1+ (1,0) [0|65535] "" Vector__XXX

BO_ 2651100161 SCU1_RAWValues9: 8 Vector__XXX
  SG_ SCU1_raw_DIO_ESR0_In : 38|1@1+ (1,0) [0|1] "" Vector__XXX
  SG_ SCU1_raw_DIO_ESR1_In : 39|1@1+ (1,0) [0|1] "" Vector__XXX
  SG_ SCU1_raw_DIO_ESR2_In : 40|1@1+ (1,0) [0|1] "" Vector__XXX
  SG_ SCU1_raw_DIO_P02_00_In : 0|1@1+ (1,0) [0|1] "" Vector__XXX
  SG_ SCU1_raw_DIO_P02_01_In : 1|1@1+ (1,0) [0|1] "" Vector__XXX
  SG_ SCU1_raw_DIO_P02_02_In : 2|1@1+ (1,0) [0|1] "" Vector__XXX
  SG_ SCU1_raw_DIO_P02_05_Out : 3|1@1+ (1,0) [0|1] "" Vector__XXX
  SG_ SCU1_raw_DIO_P02_06_In : 4|1@1+ (1,0) [0|1] "" Vector__XXX
  SG_ SCU1_raw_DIO_P02_07_In : 5|1@1+ (1,0) [0|1] "" Vector__XXX
  SG_ SCU1_raw_DIO_P02_12_Out : 6|1@1+ (1,0) [0|1] "" Vector__XXX
  SG_ SCU1_raw_DIO_P03_03_Out : 7|1@1+ (1,0) [0|1] "" Vector__XXX
  SG_ SCU1_raw_DIO_P03_04_Out : 8|1@1+ (1,0) [0|1] "" Vector__XXX
  SG_ SCU1_raw_DIO_P04_04_Out : 9|1@1+ (1,0) [0|1] "" Vector__XXX
  SG_ SCU1_raw_DIO_P04_05_Out : 10|1@1+ (1,0) [0|1] "" Vector__XXX
  SG_ SCU1_raw_DIO_P04_06_Out : 11|1@1+ (1,0) [0|1] "" Vector__XXX
  SG_ SCU1_raw_DIO_P04_07_Out : 12|1@1+ (1,0) [0|1] "" Vector__XXX
  SG_ SCU1_raw_DIO_P06_02_Out : 13|1@1+ (1,0) [0|1] "" Vector__XXX
  SG_ SCU1_raw_DIO_P06_03_Out : 14|1@1+ (1,0) [0|1] "" Vector__XXX
  SG_ SCU1_raw_DIO_P07_01_Out : 15|1@1+ (1,0) [0|1] "" Vector__XXX
  SG_ SCU1_raw_DIO_P07_02_Out : 16|1@1+ (1,0) [0|1] "" Vector__XXX
  SG_ SCU1_raw_DIO_P08_03_Out : 17|1@1+ (1,0) [0|1] "" Vector__XXX
  SG_ SCU1_raw_DIO_P08_04_Out : 18|1@1+ (1,0) [0|1] "" Vector__XXX
  SG_ SCU1_raw_DIO_P08_05_Out : 19|1@1+ (1,0) [0|1] "" Vector__XXX
  SG_ SCU1_raw_DIO_P08_06_Out : 20|1@1+ (1,0) [0|1] "" Vector__XXX
  SG_ SCU1_raw_DIO_P09_00_BiIO : 21|1@1+ (1,0) [0|1] "" Vector__XXX
  SG_ SCU1_raw_DIO_P09_01_Out : 22|1@1+ (1,0) [0|1] "" Vector__XXX
  SG_ SCU1_raw_DIO_P09_02_Out : 23|1@1+ (1,0) [0|1] "" Vector__XXX
  SG_ SCU1_raw_DIO_P09_03_Out : 24|1@1+ (1,0) [0|1] "" Vector__XXX
  SG_ SCU1_raw_DIO_P09_04_Out : 25|1@1+ (1,0) [0|1] "" Vector__XXX
  SG_ SCU1_raw_DIO_P09_05_BiIO : 26|1@1+ (1,0) [0|1] "" Vector__XXX
  SG_ SCU1_raw_DIO_P09_06_BiIO : 27|1@1+ (1,0) [0|1] "" Vector__XXX
  SG_ SCU1_raw_DIO_P09_07_BiIO : 28|1@1+ (1,0) [0|1] "" Vector__XXX
  SG_ SCU1_raw_DIO_P10_08_BiIO : 29|1@1+ (1,0) [0|1] "" Vector__XXX
  SG_ SCU1_raw_DIO_P10_09_BiIO : 30|1@1+ (1,0) [0|1] "" Vector__XXX
  SG_ SCU1_raw_DIO_P10_10_Out : 31|1@1+ (1,0) [0|1] "" Vector__XXX
  SG_ SCU1_raw_DIO_P10_11_Out : 32|1@1+ (1,0) [0|1] "" Vector__XXX
  SG_ SCU1_raw_DIO_P10_12_Out : 33|1@1+ (1,0) [0|1] "" Vector__XXX
  SG_ SCU1_raw_DIO_P11_02_Out : 34|1@1+ (1,0) [0|1] "" Vector__XXX
  SG_ SCU1_raw_DIO_P11_03_Out : 35|1@1+ (1,0) [0|1] "" Vector__XXX
  SG_ SCU1_raw_DIO_P11_04_Out : 36|1@1+ (1,0) [0|1] "" Vector__XXX
  SG_ SCU1_raw_DIO_P11_05_Out : 37|1@1+ (1,0) [0|1] "" Vector__XXX

BO_ 2449597441 SCU1_RTC: 8 Vector__XXX
  SG_ SCU1_ctr_Days : 24|8@1+ (1,0) [0|255] "" Vector__XXX
  SG_ SCU1_ctr_Hours_h : 16|8@1+ (1,0) [0|255] "" Vector__XXX
  SG_ SCU1_ctr_Minutes_min : 8|8@1+ (1,0) [0|255] "" Vector__XXX
  SG_ SCU1_ctr_Months : 32|8@1+ (1,0) [0|255] "" Vector__XXX
  SG_ SCU1_ctr_Seconds_s : 0|8@1+ (1,0) [0|255] "" Vector__XXX
  SG_ SCU1_ctr_Year : 40|8@1+ (1,0) [0|255] "" Vector__XXX

BO_ 2449540097 SCU1_SWConfigInfo: 8 Vector__XXX
  SG_ SCU1_inf_Checksum : 32|32@1+ (1,0) [0|4294967295] "" Vector__XXX
  SG_ SCU1_inf_NumOfCell : 8|8@1+ (1,0) [0|255] "" Vector__XXX
  SG_ SCU1_inf_NumOfModule : 0|8@1+ (1,0) [0|255] "" Vector__XXX

BO_ 2449499137 SCU1_Sensors: 8 Vector__XXX
  SG_ SCU1_act_T_BoardTemperature_C : 32|16@1- (0.10000000000000000555,0) [-3276.8000000000001819|3276.6999999999998181] "°C" Vector__XXX
  SG_ SCU1_act_V_SenseExt1_mV : 0|16@1+ (1,0) [0|65535] "mV" Vector__XXX
  SG_ SCU1_act_V_SenseExt2_mV : 16|16@1+ (1,0) [0|65535] "mV" Vector__XXX

BO_ 2281706497 SCU1_Status: 8 Vector__XXX
  SG_ SCU1_flag_Alarm : 44|1@1+ (1,0) [0|1] "" Vector__XXX
  SG_ SCU1_flag_BMMSafe : 37|1@1+ (1,0) [0|1] "" Vector__XXX
  SG_ SCU1_flag_CAN1BusOff : 58|1@1+ (1,0) [0|1] "" Vector__XXX
  SG_ SCU1_flag_CAN2BusOff : 59|1@1+ (1,0) [0|1] "" Vector__XXX
  SG_ SCU1_flag_CANGatewayStatus : 39|1@1+ (1,0) [0|1] "" Vector__XXX
  SG_ SCU1_flag_CompChipWarning : 52|1@1+ (1,0) [0|1] "" Vector__XXX
  SG_ SCU1_flag_ContStuckChk : 60|1@1+ (1,0) [0|1] "" Vector__XXX
  SG_ SCU1_flag_EoL_Mode : 23|1@1+ (1,0) [0|1] "" Vector__XXX
  SG_ SCU1_flag_ExtAuxStuckChk : 61|1@1+ (1,0) [0|1] "" Vector__XXX
  SG_ SCU1_flag_ForceSave : 57|1@1+ (1,0) [0|1] "" Vector__XXX
  SG_ SCU1_flag_HSS1Locked : 48|1@1+ (1,0) [0|1] "" Vector__XXX
  SG_ SCU1_flag_HSS2Locked : 49|1@1+ (1,0) [0|1] "" Vector__XXX
  SG_ SCU1_flag_HSS3Locked : 50|1@1+ (1,0) [0|1] "" Vector__XXX
  SG_ SCU1_flag_HSS4Locked : 51|1@1+ (1,0) [0|1] "" Vector__XXX
  SG_ SCU1_flag_InterLockError : 34|1@1+ (1,0) [0|1] "" Vector__XXX
  SG_ SCU1_flag_InterventioneStop : 33|1@1+ (1,0) [0|1] "" Vector__XXX
  SG_ SCU1_flag_KL15 : 36|1@1+ (1,0) [0|1] "" Vector__XXX
  SG_ SCU1_flag_Led1 : 40|1@1+ (1,0) [0|1] "" Vector__XXX
  SG_ SCU1_flag_Led2 : 41|1@1+ (1,0) [0|1] "" Vector__XXX
  SG_ SCU1_flag_Led3 : 42|1@1+ (1,0) [0|1] "" Vector__XXX
  SG_ SCU1_flag_PowerContExtAux : 19|1@1+ (1,0) [0|1] "" Vector__XXX
  SG_ SCU1_flag_PowerContNeg : 17|1@1+ (1,0) [0|1] "" Vector__XXX
  SG_ SCU1_flag_PowerContPos : 16|1@1+ (1,0) [0|1] "" Vector__XXX
  SG_ SCU1_flag_PowerContPre : 18|1@1+ (1,0) [0|1] "" Vector__XXX
  SG_ SCU1_flag_PowerProtWarning : 53|1@1+ (1,0) [0|1] "" Vector__XXX
  SG_ SCU1_flag_PrechargeOK : 63|1@1+ (1,0) [0|1] "" Vector__XXX
  SG_ SCU1_flag_SafetyEnable1 : 54|1@1+ (1,0) [0|1] "" Vector__XXX
  SG_ SCU1_flag_SafetyEnable2 : 55|1@1+ (1,0) [0|1] "" Vector__XXX
  SG_ SCU1_flag_ShuntResCalibration : 22|1@1+ (1,0) [0|1] "" Vector__XXX
  SG_ SCU1_flag_SilentCan1 : 45|1@1+ (1,0) [0|1] "" Vector__XXX
  SG_ SCU1_flag_SilentCan2 : 46|1@1+ (1,0) [0|1] "" Vector__XXX
  SG_ SCU1_flag_SourceInterlockLoop : 35|1@1+ (1,0) [0|1] "" Vector__XXX
  SG_ SCU1_flag_SupplyMonitorWarning : 38|1@1+ (1,0) [0|1] "" Vector__XXX
  SG_ SCU1_flag_VSenserelayNegExt : 27|1@1+ (1,0) [0|1] "" Vector__XXX
  SG_ SCU1_flag_VSenserelayNegInt : 25|1@1+ (1,0) [0|1] "" Vector__XXX
  SG_ SCU1_flag_VSenserelayPosExt : 26|1@1+ (1,0) [0|1] "" Vector__XXX
  SG_ SCU1_flag_VSenserelayPosInt : 24|1@1+ (1,0) [0|1] "" Vector__XXX
  SG_ SCU1_flag_Warning : 43|1@1+ (1,0) [0|1] "" Vector__XXX
  SG_ SCU1_flag_eStopBrakeOut : 56|1@1+ (1,0) [0|1] "" Vector__XXX
  SG_ SCU1_flag_eStopLoopNotClosed : 32|1@1+ (1,0) [0|1] "" Vector__XXX
  SG_ SCU1_stat_ART_BMSS_Restart : 12|1@1+ (1,0) [0|1] "" Vector__XXX
  SG_ SCU1_stat_ART_IsActive : 10|1@1+ (1,0) [0|1] "" Vector__XXX
  SG_ SCU1_stat_ART_NoError : 11|1@1+ (1,0) [0|1] "" Vector__XXX
  SG_ SCU1_stat_ART_Started : 9|1@1+ (1,0) [0|1] "" Vector__XXX
  SG_ SCU1_stat_ConOnProtect : 20|1@1+ (1,0) [0|1] "" Vector__XXX
  SG_ SCU1_stat_Config : 3|1@1+ (1,0) [0|1] "" Vector__XXX
  SG_ SCU1_stat_Diag : 5|1@1+ (1,0) [0|1] "" Vector__XXX
  SG_ SCU1_stat_Error : 2|1@1+ (1,0) [0|1] "" Vector__XXX
  SG_ SCU1_stat_Init : 0|1@1+ (1,0) [0|1] "" Vector__XXX
  SG_ SCU1_stat_LimpHome : 4|1@1+ (1,0) [0|1] "" Vector__XXX
  SG_ SCU1_stat_Run : 1|1@1+ (1,0) [0|1] "" Vector__XXX
  SG_ SCU1_stat_Shutdown : 8|1@1+ (1,0) [0|1] "" Vector__XXX

BO_ 2449548289 SCU1_SysInfo: 8 Vector__XXX
  SG_ SCU1_SysInfo_Mux M : 0|8@1+ (1,0) [0|4294967295] "" Vector__XXX
  SG_ SCU1_inf_BBoardId m2 : 8|56@1+ (1,0) [0|72057594037927904] "" Vector__XXX
  SG_ SCU1_inf_CPUBoardId m0 : 8|56@1+ (1,0) [0|72057594037927904] "" Vector__XXX
  SG_ SCU1_inf_ChipEmuExt m5 : 24|1@1+ (1,0) [0|1] "" Vector__XXX
  SG_ SCU1_inf_ChipFam m5 : 14|2@1+ (1,0) [0|3] "" Vector__XXX
  SG_ SCU1_inf_ChipFlashSize m5 : 32|4@1+ (1,0) [0|15] "" Vector__XXX
  SG_ SCU1_inf_ChipId m5 : 16|8@1+ (1,0) [0|255] "" Vector__XXX
  SG_ SCU1_inf_ChipMicroCodeVer m5 : 25|7@1+ (1,0) [0|127] "" Vector__XXX
  SG_ SCU1_inf_ChipRevStep m5 : 12|2@1+ (1,0) [0|3] "" Vector__XXX
  SG_ SCU1_inf_ChipRevSubstep m5 : 8|4@1+ (1,0) [0|15] "" Vector__XXX
  SG_ SCU1_inf_ChipSecModule m5 : 38|1@1+ (1,0) [0|1] "" Vector__XXX
  SG_ SCU1_inf_ChipSpeedGrade m5 : 36|2@1+ (1,0) [0|3] "" Vector__XXX
  SG_ SCU1_inf_HVBoardId m1 : 8|56@1+ (1,0) [0|72057594037927904] "" Vector__XXX
  SG_ SCU1_inf_HwRevMajor m4 : 16|8@1+ (1,0) [0|255] "" Vector__XXX
  SG_ SCU1_inf_HwRevMinor m4 : 8|8@1+ (1,0) [0|255] "" Vector__XXX
  SG_ SCU1_inf_MRCCBBoardId m3 : 8|56@1+ (1,0) [0|72057594037927904] "" Vector__XXX

BO_ 2449556481 SCU1_TrayConfigInfo: 8 Vector__XXX
  SG_ SCU1_inf_HighCellNr : 16|16@1+ (1,0) [0|65535] "" Vector__XXX
  SG_ SCU1_inf_HighModNr : 48|16@1+ (1,0) [0|65535] "" Vector__XXX
  SG_ SCU1_inf_LowCellNr : 0|16@1+ (1,0) [0|65535] "" Vector__XXX
  SG_ SCU1_inf_LowModNr : 32|16@1+ (1,0) [0|65535] "" Vector__XXX

BO_ 2449523713 SCU1_Warning: 8 Vector__XXX
  SG_ SCU1_wf_AfterrunTest : 40|1@1+ (1,0) [0|1] "" Vector__XXX
  SG_ SCU1_wf_BMMBattCom : 29|1@1+ (1,0) [0|1] "" Vector__XXX
  SG_ SCU1_wf_BoardTemp : 61|1@1+ (1,0) [0|1] "" Vector__XXX
  SG_ SCU1_wf_CPUSupplyWarning : 56|1@1+ (1,0) [0|1] "" Vector__XXX
  SG_ SCU1_wf_CellTempChargMax : 16|1@1+ (1,0) [0|1] "" Vector__XXX
  SG_ SCU1_wf_CellTempChargMin : 17|1@1+ (1,0) [0|1] "" Vector__XXX
  SG_ SCU1_wf_CellTempDischMax : 18|1@1+ (1,0) [0|1] "" Vector__XXX
  SG_ SCU1_wf_CellTempDischMin : 19|1@1+ (1,0) [0|1] "" Vector__XXX
  SG_ SCU1_wf_CellTempUnbalance : 37|1@1+ (1,0) [0|1] "" Vector__XXX
  SG_ SCU1_wf_CellVoltUnbalance : 36|1@1+ (1,0) [0|1] "" Vector__XXX
  SG_ SCU1_wf_CellVoltageMax : 0|1@1+ (1,0) [0|1] "" Vector__XXX
  SG_ SCU1_wf_CellVoltageMin : 1|1@1+ (1,0) [0|1] "" Vector__XXX
  SG_ SCU1_wf_ContDam : 51|1@1+ (1,0) [0|1] "" Vector__XXX
  SG_ SCU1_wf_ContactorDropOut : 60|1@1+ (1,0) [0|1] "" Vector__XXX
  SG_ SCU1_wf_ContactorNegStuck : 10|1@1+ (1,0) [0|1] "" Vector__XXX
  SG_ SCU1_wf_ContactorPosStuck : 11|1@1+ (1,0) [0|1] "" Vector__XXX
  SG_ SCU1_wf_ContactorWrongState : 49|1@1+ (1,0) [0|1] "" Vector__XXX
  SG_ SCU1_wf_CrossCheck : 41|1@1+ (1,0) [0|1] "" Vector__XXX
  SG_ SCU1_wf_CurrSens : 50|1@1+ (1,0) [0|1] "" Vector__XXX
  SG_ SCU1_wf_DeepDischProt : 32|1@1+ (1,0) [0|1] "" Vector__XXX
  SG_ SCU1_wf_Dew_Sensor : 59|1@1+ (1,0) [0|1] "" Vector__XXX
  SG_ SCU1_wf_ExtCommunicationTout : 34|1@1+ (1,0) [0|1] "" Vector__XXX
  SG_ SCU1_wf_FlashEEPROM : 47|1@1+ (1,0) [0|1] "" Vector__XXX
  SG_ SCU1_wf_HVCurrLoopMax : 22|1@1+ (1,0) [0|1] "" Vector__XXX
  SG_ SCU1_wf_HVCurrLoopMin : 23|1@1+ (1,0) [0|1] "" Vector__XXX
  SG_ SCU1_wf_InvalidData : 48|1@1+ (1,0) [0|1] "" Vector__XXX
  SG_ SCU1_wf_IsoFaultBattNeg : 8|1@1+ (1,0) [0|1] "" Vector__XXX
  SG_ SCU1_wf_IsoFaultBattPos : 9|1@1+ (1,0) [0|1] "" Vector__XXX
  SG_ SCU1_wf_KL30SafeMax : 54|1@1+ (1,0) [0|1] "" Vector__XXX
  SG_ SCU1_wf_KL30SafeMin : 55|1@1+ (1,0) [0|1] "" Vector__XXX
  SG_ SCU1_wf_KL30SafeOff : 58|1@1+ (1,0) [0|1] "" Vector__XXX
  SG_ SCU1_wf_LTCError : 39|1@1+ (1,0) [0|1] "" Vector__XXX
  SG_ SCU1_wf_LVSupplyMax : 12|1@1+ (1,0) [0|1] "" Vector__XXX
  SG_ SCU1_wf_LVSupplyMin : 13|1@1+ (1,0) [0|1] "" Vector__XXX
  SG_ SCU1_wf_ModVoltageRefMax : 6|1@1+ (1,0) [0|1] "" Vector__XXX
  SG_ SCU1_wf_ModVoltageSum : 5|1@1+ (1,0) [0|1] "" Vector__XXX
  SG_ SCU1_wf_Mod_Voltage_Ref_Min : 7|1@1+ (1,0) [0|1] "" Vector__XXX
  SG_ SCU1_wf_NoAfterrunTest : 35|1@1+ (1,0) [0|1] "" Vector__XXX
  SG_ SCU1_wf_PowerProtectionWarning : 57|1@1+ (1,0) [0|1] "" Vector__XXX
  SG_ SCU1_wf_ProgProcess : 44|1@1+ (1,0) [0|1] "" Vector__XXX
  SG_ SCU1_wf_RAM : 45|1@1+ (1,0) [0|1] "" Vector__XXX
  SG_ SCU1_wf_ROM : 46|1@1+ (1,0) [0|1] "" Vector__XXX
  SG_ SCU1_wf_RefVoltErrorMax : 52|1@1+ (1,0) [0|1] "" Vector__XXX
  SG_ SCU1_wf_RefVoltErrorMin : 53|1@1+ (1,0) [0|1] "" Vector__XXX
  SG_ SCU1_wf_SCUConfig : 31|1@1+ (1,0) [0|1] "" Vector__XXX
  SG_ SCU1_wf_SCUError : 63|1@1+ (1,0) [0|1] "" Vector__XXX
  SG_ SCU1_wf_StuckAtTemp : 42|1@1+ (1,0) [0|1] "" Vector__XXX
  SG_ SCU1_wf_StuckAtVolt : 43|1@1+ (1,0) [0|1] "" Vector__XXX
  SG_ SCU1_wf_SysCurCha : 20|1@1+ (1,0) [0|1] "" Vector__XXX
  SG_ SCU1_wf_SysCurDis : 21|1@1+ (1,0) [0|1] "" Vector__XXX
  SG_ SCU1_wf_SysCurLimitCha : 26|1@1+ (1,0) [0|1] "" Vector__XXX
  SG_ SCU1_wf_SysCurLimitDis : 27|1@1+ (1,0) [0|1] "" Vector__XXX
  SG_ SCU1_wf_SysInitTimeout : 30|1@1+ (1,0) [0|1] "" Vector__XXX
  SG_ SCU1_wf_SysPrechargeFailed : 28|1@1+ (1,0) [0|1] "" Vector__XXX
  SG_ SCU1_wf_SysVoltageMax : 2|1@1+ (1,0) [0|1] "" Vector__XXX
  SG_ SCU1_wf_SysVoltageMin : 3|1@1+ (1,0) [0|1] "" Vector__XXX
  SG_ SCU1_wf_SysVoltageSum : 4|1@1+ (1,0) [0|1] "" Vector__XXX
  SG_ SCU1_wf_TerminalTempMax : 14|1@1+ (1,0) [0|1] "" Vector__XXX
  SG_ SCU1_wf_TerminalTempMin : 15|1@1+ (1,0) [0|1] "" Vector__XXX
  SG_ SCU1_wf_TerminalTempUnbalance : 38|1@1+ (1,0) [0|1] "" Vector__XXX
  SG_ SCU1_wf_WDReset : 33|1@1+ (1,0) [0|1] "" Vector__XXX
  SG_ SCU1_wf_eStopCurrLoopMax : 24|1@1+ (1,0) [0|1] "" Vector__XXX
  SG_ SCU1_wf_eStopCurrLoopMin : 25|1@1+ (1,0) [0|1] "" Vector__XXX

BO_ 2583725057 SCU1_battery_Voltages_diag: 8 Vector__XXX
  SG_ SCU1_act_U_TrayNegExt_V : 16|16@1- (0.10000000000000000555,0) [-3276.8000000000001819|3276.6999999999998181] "V" Vector__XXX
  SG_ SCU1_act_U_TrayNegInt_V : 48|16@1- (0.10000000000000000555,0) [-3276.8000000000001819|3276.6999999999998181] "V" Vector__XXX
  SG_ SCU1_act_U_TrayPosExt_V : 0|16@1- (0.10000000000000000555,0) [-3276.8000000000001819|3276.6999999999998181] "V" Vector__XXX
  SG_ SCU1_act_U_TrayPosInt_V : 32|16@1- (0.10000000000000000555,0) [-3276.8000000000001819|3276.6999999999998181] "V" Vector__XXX

BO_ 2449511425 SCU1_tray_Voltages: 8 Vector__XXX
  SG_ SCU1_act_U_ChassisGndVoltage_V : 16|16@1+ (0.0010000000000000000208,0) [0|65.534999999999996589] "V" Vector__XXX
  SG_ SCU1_act_U_ReferenceVoltage_V : 32|16@1+ (0.0010000000000000000208,0) [0|65.534999999999996589] "V" Vector__XXX
  SG_ SCU1_act_U_TrayVoltageLocal_V : 0|16@1- (0.10000000000000000555,0) [-3276.8000000000001819|3276.6999999999998181] "V" Vector__XXX

CM_ BO_ 2316833792 "Control digital outputs (Control digital outputs)";
CM_ BO_ 2650877953 "Byte 0   Byte 1   Byte 2   Byte 3   Byte 4   Byte 5   Byte 6   Byte 7";
CM_ BO_ 2650882049 "Byte 0   Byte 1   Byte 2   Byte 3   Byte 4   Byte 5   Byte 6   Byte 7";
CM_ BO_ 2650886145 "Byte 0   Byte 1   Byte 2   Byte 3   Byte 4   Byte 5   Byte 6   Byte 7";
CM_ BO_ 2650890241 "Byte 0   Byte 1   Byte 2   Byte 3   Byte 4   Byte 5   Byte 6   Byte 7";
CM_ BO_ 2650894337 "Byte 0   Byte 1   Byte 2   Byte 3   Byte 4   Byte 5   Byte 6   Byte 7";
CM_ BO_ 2650898433 "Byte 0   Byte 1   Byte 2   Byte 3   Byte 4   Byte 5   Byte 6   Byte 7";
CM_ BO_ 2650902529 "Byte 0   Byte 1   Byte 2   Byte 3   Byte 4   Byte 5   Byte 6   Byte 7";
CM_ BO_ 2650906625 "Byte 0   Byte 1   Byte 2   Byte 3   Byte 4   Byte 5   Byte 6   Byte 7";
CM_ BO_ 2650914817 "Byte 0   Byte 1   Byte 2   Byte 3   Byte 4   Byte 5   Byte 6   Byte 7";
CM_ BO_ 2181563392 "SCU synchinization message (SCU synchinization message)";
CM_ BO_ 2650828801 "Byte 0   Byte 1   Byte 2   Byte 3   Byte 4   Byte 5   Byte 6   Byte 7";
CM_ BO_ 2650804225 "information about actual cell temperatures (information about actual cell temperatures)";
CM_ BO_ 2650800129 "Information about actual  cell voltages (Information about actual  cell voltages)";
CM_ BO_ 2650812417 "Byte 0   Byte 1   Byte 2   Byte 3   Byte 4   Byte 5   Byte 6   Byte 7";
CM_ BO_ 2650824705 "Byte 0   Byte 1   Byte 2   Byte 3   Byte 4   Byte 5   Byte 6   Byte 7";
CM_ BO_ 2650836993 "Byte 0   Byte 1   Byte 2   Byte 3   Byte 4   Byte 5   Byte 6   Byte 7";
CM_ BO_ 2650820609 "Byte 0   Byte 1   Byte 2   Byte 3   Byte 4   Byte 5   Byte 6   Byte 7";
CM_ BO_ 2650857473 "Byte 0   Byte 1   Byte 2   Byte 3   Byte 4   Byte 5   Byte 6   Byte 7";
CM_ BO_ 2650816513 "Byte 0   Byte 1   Byte 2   Byte 3   Byte 4   Byte 5   Byte 6   Byte 7";
CM_ BO_ 2650808321 "Byte 0   Byte 1   Byte 2   Byte 3   Byte 4   Byte 5   Byte 6   Byte 7";
CM_ BO_ 2650832897 "Byte 0   Byte 1   Byte 2   Byte 3   Byte 4   Byte 5   Byte 6   Byte 7";
CM_ BO_ 2650853377 "Byte 0   Byte 1   Byte 2   Byte 3   Byte 4   Byte 5   Byte 6   Byte 7";
CM_ BO_ 2650861569 "Byte 0   Byte 1   Byte 2   Byte 3   Byte 4   Byte 5   Byte 6   Byte 7";
CM_ BO_ 2650873857 "Byte 0   Byte 1   Byte 2   Byte 3   Byte 4   Byte 5   Byte 6   Byte 7";
CM_ BO_ 2650869761 "Byte 0   Byte 1   Byte 2   Byte 3   Byte 4   Byte 5   Byte 6   Byte 7";
CM_ BO_ 2650841089 "Byte 0   Byte 1   Byte 2   Byte 3   Byte 4   Byte 5   Byte 6   Byte 7";
CM_ BO_ 2650845185 "Byte 0   Byte 1   Byte 2   Byte 3   Byte 4   Byte 5   Byte 6   Byte 7";
CM_ BO_ 2650849281 "Byte 0   Byte 1   Byte 2   Byte 3   Byte 4   Byte 5   Byte 6   Byte 7";
CM_ BO_ 2650865665 "Byte 0   Byte 1   Byte 2   Byte 3   Byte 4   Byte 5   Byte 6   Byte 7";
CM_ BO_ 2415922177 "Information about cell voltages an temperature (Information about cell voltages an temperature)";
CM_ BO_ 2415922178 "Information about cell voltages an temperature (Information about cell voltages an temperature)";
CM_ BO_ 2415922179 "Information about cell voltages an temperature (Information about cell voltages an temperature)";
CM_ BO_ 2415922180 "Information about cell voltages an temperature (Information about cell voltages an temperature)";
CM_ BO_ 2415922181 "Information about cell voltages an temperature (Information about cell voltages an temperature)";
CM_ BO_ 2415922182 "Information about cell voltages an temperature (Information about cell voltages an temperature)";
CM_ BO_ 2415922183 "Information about cell voltages an temperature (Information about cell voltages an temperature)";
CM_ BO_ 2415922184 "Information about cell voltages an temperature (Information about cell voltages an temperature)";
CM_ BO_ 2415922185 "Information about cell voltages an temperature (Information about cell voltages an temperature)";
CM_ BO_ 2415922186 "Information about cell voltages an temperature (Information about cell voltages an temperature)";
CM_ BO_ 2415922187 "Information about cell voltages an temperature (Information about cell voltages an temperature)";
CM_ BO_ 2415922188 "Information about cell voltages an temperature (Information about cell voltages an temperature)";
CM_ BO_ 2415922189 "Information about cell voltages an temperature (Information about cell voltages an temperature)";
CM_ BO_ 2415922190 "Information about cell voltages an temperature (Information about cell voltages an temperature)";
CM_ BO_ 2415922191 "Information about cell voltages an temperature (Information about cell voltages an temperature)";
CM_ BO_ 2415922192 "Information about cell voltages an temperature (Information about cell voltages an temperature)";
CM_ BO_ 2415922193 "Information about cell voltages an temperature (Information about cell voltages an temperature)";
CM_ BO_ 2415922194 "Information about cell voltages an temperature (Information about cell voltages an temperature)";
CM_ BO_ 2415922195 "Information about cell voltages an temperature (Information about cell voltages an temperature)";
CM_ BO_ 2415922196 "Information about cell voltages an temperature (Information about cell voltages an temperature)";
CM_ BO_ 2415941633 "module version and Error information (module version and Error information)";
CM_ BO_ 2451052545 "commands module to balance cells (commands module to balance cells)";
CM_ BO_ 2550716417 "information for module configuration (information for module configuration)";
CM_ BO_ 2415949825 "Data stored in the EEPROM (Data stored in the EEPROM)";
CM_ BO_ 2415962113 "Analog power supply values of the ICs on the module board (Analog power supply values of the ICs on the module board)";
CM_ BO_ 2415970305 "Sum of the cell voltages of ICs on the module board (Sum of the cell voltages of ICs on the module board)";
CM_ BO_ 2415958017 "Digital power supply values of the ICs on the module board (Digital power supply values of the ICs on the module board)";
CM_ BO_ 2415953921 "Informations about internal temperatures of the ICs on the module board (Informations about internal temperatures of the ICs on the module board)";
CM_ BO_ 2415966209 "Values of the external reference voltages of the ICs on the module board (Values of the external reference voltages of the ICs on the module board)";
CM_ BO_ 2415933441 "information about module voltages (information about module voltages)";
CM_ BO_ 2415937537 "module configuration information (module configuration information)";
CM_ BO_ 2415986689 "Safety Mechanism Flags (Safety Mechanism Flags)";
CM_ BO_ 2415929345 "information about module voltages and split temperatures (information about module voltages and split temperatures)";
CM_ BO_ 2415974401 "over voltage Flags for all cells (over voltage Flags for all cells)";
CM_ BO_ 2415982593 "Write Data to the EEPROM (Write Data to the EEPROM)";
CM_ BO_ 2415945729 "BMS-Slave serial numbers (BMS-Slave serial numbers)";
CM_ BO_ 2416478209 "Starts action for all modules in daisy-chain (Starts action for all modules in daisy-chain)";
CM_ BO_ 2415925249 "Information about temperatures on module terminals (Information about temperatures on module terminals)";
CM_ BO_ 2415978497 "under voltage Flags for all cells (under voltage Flags for all cells)";
CM_ BO_ 2416474113 "Write Data to the EEPROM (Write Data to the EEPROM)";
CM_ BO_ 2449544193 "BMU serial numbers (BMU serial numbers)";
CM_ BO_ 2449527809 "SCU alarm message (SCU alarm message)";
CM_ BO_ 2449568769 "SCU usage counter (SCU usage counter)";
CM_ BO_ 2315318273 "SCU battery voltages - (SCU battery voltages -)";
CM_ BO_ 2315314177 "SCU battery voltages + (SCU battery voltages +)";
CM_ BO_ 2449585153 "Byte 0   Byte 1   Byte 2   Byte 3   Byte 4   Byte 5   Byte 6   Byte 7";
CM_ BO_ 2449589249 "Byte 0   Byte 1   Byte 2   Byte 3   Byte 4   Byte 5   Byte 6   Byte 7";
CM_ BO_ 2449490945 "Coil currents of contactors (Coil currents of contactors)";
CM_ BO_ 2315342849 "Damage of contactors (Damage of contactors)";
CM_ BO_ 2315277313 "SCU currents (SCU currents)";
CM_ BO_ 2449519617 "SCU error message (SCU error message)";
CM_ BO_ 2451055617 "Operate highside switch outputs in";
CM_ BO_ 2449486849 "highside switch currents (highside switch currents)";
CM_ BO_ 2449482753 "percentual status of highside-switch-outputs (percentual status of highside-switch-outputs)";
CM_ BO_ 2449576961 "SCU Histogramm (SCU Histogramm)";
CM_ BO_ 2449593345 "Byte 0   Byte 1   Byte 2   Byte 3   Byte 4   Byte 5   Byte 6   Byte 7";
CM_ BO_ 2449515521 "Isolation- and contactor stuck voltages (frozen at init) (Isolation- and contactor stuck voltages (frozen at init))";
CM_ BO_ 2449552385 "SCU limit configuration information (SCU limit configuration information)";
CM_ BO_ 2449536001 "SCU currents (SCU currents)";
CM_ BO_ 2449503233 "SCU operating voltages (SCU operating voltages)";
CM_ BO_ 2449564673 "SCU operation time counter (SCU operation time counter)";
CM_ BO_ 2651063297 "SCU Raw Error Value message (SCU Raw Error Value message)";
CM_ BO_ 2651067393 "SCU Raw Value message 1 (SCU Raw Value message 1)";
CM_ BO_ 2651104257 "SCU Raw Value message 10  for SCU hardware test (SCU Raw Value message 10  for SCU hardware test)";
CM_ BO_ 2651071489 "SCU Raw Value message 2 (SCU Raw Value message 2)";
CM_ BO_ 2651075585 "SCU Raw Value message 3 (SCU Raw Value message 3)";
CM_ BO_ 2651079681 "SCU Raw Value message 4 (SCU Raw Value message 4)";
CM_ BO_ 2651083777 "SCU Raw Value message 5 (SCU Raw Value message 5)";
CM_ BO_ 2651087873 "SCU Raw Value message 6 (SCU Raw Value message 6)";
CM_ BO_ 2651091969 "SCU Raw Value message 7 (SCU Raw Value message 7)";
CM_ BO_ 2651096065 "SCU Raw Value message 8 (SCU Raw Value message 8)";
CM_ BO_ 2651100161 "SCU Raw Value message 9 for SCU hardware test (SCU Raw Value message 9 for SCU hardware test)";
CM_ BO_ 2449597441 "Real Time Clock values (Real Time Clock values)";
CM_ BO_ 2449540097 "SCU SW configuration information (SCU SW configuration information)";
CM_ BO_ 2449499137 "SCU Temperatures (SCU Temperatures)";
CM_ BO_ 2281706497 "SCU status message (SCU status message)";
CM_ BO_ 2449548289 "SCU System Information (SCU System Information)";
CM_ BO_ 2449556481 "SCU tray configuration information (SCU tray configuration information)";
CM_ BO_ 2449523713 "SCU warning message (SCU warning message)";
CM_ BO_ 2583725057 "SCU battery voltages diagnostic (SCU battery voltages diagnostic)";
CM_ BO_ 2449511425 "SCU tray voltages (SCU tray voltages)";
CM_ SG_ 2415922177 B001_flag_Balancing "shows if Balancing for the Cell is active";
CM_ SG_ 2415922178 B002_flag_Balancing "shows if Balancing for the Cell is active";
CM_ SG_ 2415922179 B003_flag_Balancing "shows if Balancing for the Cell is active";
CM_ SG_ 2415922180 B004_flag_Balancing "shows if Balancing for the Cell is active";
CM_ SG_ 2415922181 B005_flag_Balancing "shows if Balancing for the Cell is active";
CM_ SG_ 2415922182 B006_flag_Balancing "shows if Balancing for the Cell is active";
CM_ SG_ 2415922183 B007_flag_Balancing "shows if Balancing for the Cell is active";
CM_ SG_ 2415922184 B008_flag_Balancing "shows if Balancing for the Cell is active";
CM_ SG_ 2415922185 B009_flag_Balancing "shows if Balancing for the Cell is active";
CM_ SG_ 2415922186 B010_flag_Balancing "shows if Balancing for the Cell is active";
CM_ SG_ 2415922187 B011_flag_Balancing "shows if Balancing for the Cell is active";
CM_ SG_ 2415922188 B012_flag_Balancing "shows if Balancing for the Cell is active";
CM_ SG_ 2415922189 B013_flag_Balancing "shows if Balancing for the Cell is active";
CM_ SG_ 2415922190 B014_flag_Balancing "shows if Balancing for the Cell is active";
CM_ SG_ 2415922191 B015_flag_Balancing "shows if Balancing for the Cell is active";
CM_ SG_ 2415922192 B016_flag_Balancing "shows if Balancing for the Cell is active";
CM_ SG_ 2415922193 B017_flag_Balancing "shows if Balancing for the Cell is active";
CM_ SG_ 2415922194 B018_flag_Balancing "shows if Balancing for the Cell is active";
CM_ SG_ 2415922195 B019_flag_Balancing "shows if Balancing for the Cell is active";
CM_ SG_ 2415922196 B020_flag_Balancing "shows if Balancing for the Cell is active";
CM_ SG_ 2316833792 BMM_Fan_State "Stafe of the fan";
CM_ SG_ 2316833792 BMM_req_ContactorAux "aux contactors";
CM_ SG_ 2316833792 BMM_req_ContactorNeg "contactor -";
CM_ SG_ 2316833792 BMM_req_ContactorPos "contactor +";
CM_ SG_ 2316833792 BMM_req_ContactorPre "precharge contactor";
CM_ SG_ 2316833792 BMM_req_VSenseRelayBatNeg "V sense Relay Bat-";
CM_ SG_ 2316833792 BMM_req_VSenseRelayBatPos "V sense Relay Bat+";
CM_ SG_ 2316833792 BMM_req_VSenseRelaySysNeg "V sense Relay Sys-";
CM_ SG_ 2316833792 BMM_req_VSenseRelaySysPos "V sense Relay Sys+";
CM_ SG_ 2650800129 BMMp_acg_U_CellVoltage_mV "average actual measured cell voltage in system";
CM_ SG_ 2650812417 BMMp_act_I_BatteryCurrent_A "actual battery charge current";
CM_ SG_ 2650812417 BMMp_act_P_BatteryPower_kW "actual battery power (current x voltage)";
CM_ SG_ 2650812417 BMMp_act_U_BatteryVoltage_V "actual battery voltage";
CM_ SG_ 2650812417 BMMp_act_U_SystemVoltage_V "actual terminal voltage";
CM_ SG_ 2650828801 BMMp_af_BoardTemp "ECU/IC board temperature too high/low";
CM_ SG_ 2650828801 BMMp_af_ContDam "contactors damaged";
CM_ SG_ 2650828801 BMMp_af_ContactorDropOut "a contactor drop out occured";
CM_ SG_ 2650828801 BMMp_af_ContactorWrongState "tbd";
CM_ SG_ 2650828801 BMMp_af_CurrSens "i sensor error occurred";
CM_ SG_ 2650828801 BMMp_af_InvalidData "short circuit or open temperature sensor";
CM_ SG_ 2650828801 BMMp_af_KL30SafeMax "KL30-Safe max";
CM_ SG_ 2650828801 BMMp_af_KL30SafeMin "KL30-Safe min";
CM_ SG_ 2650828801 BMMp_af_KL30SafeOff "BMS-M-SafePwr was switched off (HW detection)";
CM_ SG_ 2650828801 BMMp_af_RefVoltErrorMax "refernce voltage to high";
CM_ SG_ 2650828801 BMMp_af_RefVoltErrorMin "refernce voltage to low";
CM_ SG_ 2650865665 BMMp_avg_T_BatteryTemp_C "Average Cell Temperature";
CM_ SG_ 2650804225 BMMp_avg_T_CellTemp_C "average actual measured cell  temperature in system";
CM_ SG_ 2650808321 BMMp_avg_T_TerminalTemp_C "average actual measured cell  temperature in system";
CM_ SG_ 2650857473 BMMp_calc_SOHcapacity_pct "Internal SoH (actual SoH capacity)";
CM_ SG_ 2650816513 BMMp_cnt_MirroredAliveCounter "mirror of the received VCU alive counter";
CM_ SG_ 2650824705 BMMp_ef_BoardTemp "ECU/IC board temperature too high/low";
CM_ SG_ 2650824705 BMMp_ef_ContDam "contactors damaged";
CM_ SG_ 2650824705 BMMp_ef_ContactorDropOut "a contactor drop out occured";
CM_ SG_ 2650824705 BMMp_ef_ContactorWrongState "tbd";
CM_ SG_ 2650824705 BMMp_ef_CurrSens "i sensor error occurred";
CM_ SG_ 2650824705 BMMp_ef_InvalidData "short circuit or open temperature sensor";
CM_ SG_ 2650824705 BMMp_ef_KL30SafeMax "KL30-Safe max";
CM_ SG_ 2650824705 BMMp_ef_KL30SafeMin "KL30-Safe min";
CM_ SG_ 2650824705 BMMp_ef_KL30SafeOff "BMS-M-SafePwr was switched off (HW detection)";
CM_ SG_ 2650824705 BMMp_ef_RefVoltErrorMax "refernce voltage to high";
CM_ SG_ 2650824705 BMMp_ef_RefVoltErrorMin "refernce voltage to low";
CM_ SG_ 2650816513 BMMp_flag_ContactorHVNeg "0 = contactor open; 1=contactor closed";
CM_ SG_ 2650816513 BMMp_flag_ContactorHVPos "0 = contactor open; 1=contactor closed";
CM_ SG_ 2650816513 BMMp_flag_ContactorPrecha "0 = contactor open; 1=contactor closed";
CM_ SG_ 2650816513 BMMp_flag_ExternalSdwnRq "External request (CAN Rx Msg) to switch off battery";
CM_ SG_ 2650816513 BMMp_flag_HVILState "High voltage interlock";
CM_ SG_ 2650816513 BMMp_flag_InternalKL30Safe "internal KL30 set";
CM_ SG_ 2650816513 BMMp_flag_Wake "Ignition Pin set to high from VCU (drive request or charge request)";
CM_ SG_ 2650845185 BMMp_lim_I_ChargeCurr_A "maximum permitted charge current";
CM_ SG_ 2650845185 BMMp_lim_I_DischargeCurr_A "maximum permitted discharge current";
CM_ SG_ 2650845185 BMMp_lim_I_regenCurr_A "maximum permitted regen current";
CM_ SG_ 2650849281 BMMp_lim_P_ChargePow_W "maximum permitted charge power";
CM_ SG_ 2650849281 BMMp_lim_P_DischargePow_W "maximum permitted discharge power";
CM_ SG_ 2650849281 BMMp_lim_U_MaxVolt_V "maximum permitted voltage limit for battery";
CM_ SG_ 2650849281 BMMp_lim_U_MinVolt_V "minimum permitted voltage limit for battery";
CM_ SG_ 2650845185 BMMp_lim_regenPower_W "maximum permitted regen power";
CM_ SG_ 2650804225 BMMp_max_T_CellTemp_C "highest actual measured cell temperature in system";
CM_ SG_ 2650808321 BMMp_max_T_TerminalTemp_C "highest actual measured cell temperature in system";
CM_ SG_ 2650800129 BMMp_max_U_CellVoltage_mV "highest actual measured cell voltage in system";
CM_ SG_ 2650804225 BMMp_min_T_CellTemp_C "lowest actual measured cell  temperature in system";
CM_ SG_ 2650808321 BMMp_min_T_TerminalTemp_C "lowest actual measured cell  temperature in system";
CM_ SG_ 2650800129 BMMp_min_U_CellVoltage_mV "lowest actual measured cell voltage in system";
CM_ SG_ 2650836993 BMMp_num_ErrDetectDevice "error dectecting device number";
CM_ SG_ 2650836993 BMMp_num_ErrSrcCompClass "Error source component class";
CM_ SG_ 2650836993 BMMp_num_ErrSrcCompNr "Error source component number";
CM_ SG_ 2650836993 BMMp_num_ErrSrcSubcompClass "Error source subcomponent class";
CM_ SG_ 2650836993 BMMp_num_Errornumber "number of the active warning/alarm/error";
CM_ SG_ 2650836993 BMMp_num_Errorvalue "additional information in case of an active warning/alarm/error (value that caused the warning/alarm/error)";
CM_ SG_ 2650804225 BMMp_num_MaxCellTemp "cell number of cell with actual highest  temperature";
CM_ SG_ 2650800129 BMMp_num_MaxCellVoltage "cell number of cell with actual highest voltage";
CM_ SG_ 2650808321 BMMp_num_MaxTerminalTemp "cell number of cell with actual highest  temperature";
CM_ SG_ 2650804225 BMMp_num_MinCellTemp "cell number of cell with actual lowest  temperature";
CM_ SG_ 2650800129 BMMp_num_MinCellVoltage "cell number of cell with actual lowest voltage";
CM_ SG_ 2650808321 BMMp_num_MinTerminalTemp "cell number of cell with actual lowest  temperature";
CM_ SG_ 2650865665 BMMp_req_Chiller_pct "desired chiller power in percent";
CM_ SG_ 2650865665 BMMp_req_Heater_pct "desired heater power in percent";
CM_ SG_ 2650865665 BMMp_req_Mode "Signal for TCU that determines the mode, the TCU should work with";
CM_ SG_ 2650865665 BMMp_req_T_InletTemp_C "Requested Inlet Temperature";
CM_ SG_ 2650832897 BMMp_wf_BoardTemp "ECU/IC board temperature too high/low";
CM_ SG_ 2650832897 BMMp_wf_ContDam "contactors damaged";
CM_ SG_ 2650832897 BMMp_wf_ContactorDropOut "a contactor drop out occured";
CM_ SG_ 2650832897 BMMp_wf_ContactorWrongState "tbd";
CM_ SG_ 2650832897 BMMp_wf_CurrSens "i sensor error occurred";
CM_ SG_ 2650832897 BMMp_wf_InvalidData "short circuit or open temperature sensor";
CM_ SG_ 2650832897 BMMp_wf_KL30SafeMax "KL30-Safe max";
CM_ SG_ 2650832897 BMMp_wf_KL30SafeMin "KL30-Safe min";
CM_ SG_ 2650832897 BMMp_wf_KL30SafeOff "BMS-M-SafePwr was switched off (HW detection)";
CM_ SG_ 2650832897 BMMp_wf_RefVoltErrorMax "refernce voltage to high";
CM_ SG_ 2650832897 BMMp_wf_RefVoltErrorMin "refernce voltage to low";
CM_ SG_ 2415986689 M001_ADCOverlapTestFailed_IC1 "ADC overlap test failed for IC1";
CM_ SG_ 2415986689 M001_ADCOverlapTestFailed_IC2 "ADC overlap test failed for IC2";
CM_ SG_ 2415986689 M001_ADCOverlapTestFailed_IC3 "ADC overlap test failed for IC3";
CM_ SG_ 2415986689 M001_ADCOverlapTestFailed_IC4 "ADC overlap test failed for IC4";
CM_ SG_ 2415986689 M001_ADCSefttestAUXFailed_IC1 "ADC & memory test of GPIO voltages failed for IC1";
CM_ SG_ 2415986689 M001_ADCSefttestAUXFailed_IC2 "ADC & memory test of GPIO voltages failed for IC2";
CM_ SG_ 2415986689 M001_ADCSefttestAUXFailed_IC3 "ADC & memory test of GPIO voltages failed for IC3";
CM_ SG_ 2415986689 M001_ADCSefttestAUXFailed_IC4 "ADC & memory test of GPIO voltages failed for IC4";
CM_ SG_ 2415986689 M001_ADCSefttestCVFailed_IC1 "ADC & memory test of cell voltages failed for IC1";
CM_ SG_ 2415986689 M001_ADCSefttestCVFailed_IC2 "ADC & memory test of cell voltages failed for IC2";
CM_ SG_ 2415986689 M001_ADCSefttestCVFailed_IC3 "ADC & memory test of cell voltages failed for IC3";
CM_ SG_ 2415986689 M001_ADCSefttestCVFailed_IC4 "ADC & memory test of cell voltages failed for IC4";
CM_ SG_ 2415986689 M001_BadCRCAccepted_IC1 "LTC (IC1) accepted a bad CRC";
CM_ SG_ 2415986689 M001_BadCRCAccepted_IC2 "LTC (IC2) accepted a bad CRC";
CM_ SG_ 2415986689 M001_BadCRCAccepted_IC3 "LTC (IC3) accepted a bad CRC";
CM_ SG_ 2415986689 M001_BadCRCAccepted_IC4 "LTC (IC4) accepted a bad CRC";
CM_ SG_ 2415986689 M001_CLRCmdBroken_IC1 "LTC (IC1) clear command is broken";
CM_ SG_ 2415986689 M001_CLRCmdBroken_IC2 "LTC (IC2) clear command is broken";
CM_ SG_ 2415986689 M001_CLRCmdBroken_IC3 "LTC (IC3) clear command is broken";
CM_ SG_ 2415986689 M001_CLRCmdBroken_IC4 "LTC (IC4) clear command is broken";
CM_ SG_ 2415986689 M001_DischargeCircuitFault_IC1 "fault in discharge circuit at IC1";
CM_ SG_ 2415986689 M001_DischargeCircuitFault_IC2 "fault in discharge circuit at IC2";
CM_ SG_ 2415986689 M001_DischargeCircuitFault_IC3 "fault in discharge circuit at IC3";
CM_ SG_ 2415986689 M001_DischargeCircuitFault_IC4 "fault in discharge circuit at IC4";
CM_ SG_ 2415986689 M001_GPIOAdjShortDetected_IC1 "GPIO adjacent short detected at IC1";
CM_ SG_ 2415986689 M001_GPIOAdjShortDetected_IC2 "GPIO adjacent short detected at IC2";
CM_ SG_ 2415986689 M001_GPIOAdjShortDetected_IC3 "GPIO adjacent short detected at IC3";
CM_ SG_ 2415986689 M001_GPIOAdjShortDetected_IC4 "GPIO adjacent short detected at IC4";
CM_ SG_ 2415986689 M001_MUXFail_IC1 "MUX test failed for IC1";
CM_ SG_ 2415986689 M001_MUXFail_IC2 "MUX test failed for IC2";
CM_ SG_ 2415986689 M001_MUXFail_IC3 "MUX test failed for IC3";
CM_ SG_ 2415986689 M001_MUXFail_IC4 "MUX test failed for IC4";
CM_ SG_ 2415986689 M001_OWCircuitStuckCV_IC1 "open cell wire circuit stuck for IC1";
CM_ SG_ 2415986689 M001_OWCircuitStuckCV_IC2 "open cell wire circuit stuck for IC2";
CM_ SG_ 2415986689 M001_OWCircuitStuckCV_IC3 "open cell wire circuit stuck for IC3";
CM_ SG_ 2415986689 M001_OWCircuitStuckCV_IC4 "open cell wire circuit stuck for IC4";
CM_ SG_ 2415986689 M001_OpenWireDetectedAUX_IC1 "open GPIO wire(s) detected at IC1";
CM_ SG_ 2415986689 M001_OpenWireDetectedAUX_IC2 "open GPIO wire(s) detected at IC2";
CM_ SG_ 2415986689 M001_OpenWireDetectedAUX_IC3 "open GPIO wire(s) detected at IC3";
CM_ SG_ 2415986689 M001_OpenWireDetectedAUX_IC4 "open GPIO wire(s) detected at IC4";
CM_ SG_ 2415986689 M001_OpenWireDetectedCV_IC1 "open cell wire(s) detected at IC1";
CM_ SG_ 2415986689 M001_OpenWireDetectedCV_IC2 "open cell wire(s) detected at IC2";
CM_ SG_ 2415986689 M001_OpenWireDetectedCV_IC3 "open cell wire(s) detected at IC3";
CM_ SG_ 2415986689 M001_OpenWireDetectedCV_IC4 "open cell wire(s) detected at IC4";
CM_ SG_ 2415986689 M001_SM_ClrRegsFail_IC1 "registers were not cleared during execution of any safety mechanisms at IC1";
CM_ SG_ 2415986689 M001_SM_ClrRegsFail_IC2 "registers were not cleared during execution of any safety mechanisms at IC2";
CM_ SG_ 2415986689 M001_SM_ClrRegsFail_IC3 "registers were not cleared during execution of any safety mechanisms at IC3";
CM_ SG_ 2415986689 M001_SM_ClrRegsFail_IC4 "registers were not cleared during execution of any safety mechanisms at IC4";
CM_ SG_ 2415986689 M001_SM_digRedFail_IC1 "digital redundancy fail detected during execution of any safety mechanism at IC1";
CM_ SG_ 2415986689 M001_SM_digRedFail_IC2 "digital redundancy fail detected during execution of any safety mechanism at IC2";
CM_ SG_ 2415986689 M001_SM_digRedFail_IC3 "digital redundancy fail detected during execution of any safety mechanism at IC3";
CM_ SG_ 2415986689 M001_SM_digRedFail_IC4 "digital redundancy fail detected during execution of any safety mechanism at IC4";
CM_ SG_ 2415949825 M001_WriteDynamicAreaANext "shows which dynamic area will be written next";
CM_ SG_ 2415986689 M001_WrongPathSelection_IC1 "wrong path selection for IC1";
CM_ SG_ 2415986689 M001_WrongPathSelection_IC2 "wrong path selection for IC2";
CM_ SG_ 2415986689 M001_WrongPathSelection_IC3 "wrong path selection for IC3";
CM_ SG_ 2415986689 M001_WrongPathSelection_IC4 "wrong path selection for IC4";
CM_ SG_ 2415953921 M001_act_T_IC1_Temp_C "internal temperature of IC 1 on module board";
CM_ SG_ 2415953921 M001_act_T_IC2_Temp_C "internal temperature of IC 2 on module board";
CM_ SG_ 2415953921 M001_act_T_IC3_Temp_C "internal temperature of IC 3 on module board";
CM_ SG_ 2415953921 M001_act_T_IC4_Temp_C "internal temperature of IC 4 on module board";
CM_ SG_ 2415925249 M001_act_T_TermTempNeg_C "temperature measured on negative terminal";
CM_ SG_ 2415925249 M001_act_T_TermTempPos_C "temperature measured on positive terminal";
CM_ SG_ 2415929345 M001_act_T_TermTempSplitNeg "temperature measured on negative split terminal";
CM_ SG_ 2415929345 M001_act_T_TermTempSplitPos "temperature measured on positive split terminal";
CM_ SG_ 2415962113 M001_act_U_AnalogPower_IC1_mV "Analog Power Supply Voltage of IC 1 on the module board";
CM_ SG_ 2415962113 M001_act_U_AnalogPower_IC2_mV "Analog Power Supply Voltage of IC 2 on the module board";
CM_ SG_ 2415962113 M001_act_U_AnalogPower_IC3_mV "Analog Power Supply Voltage of IC 3 on the module board";
CM_ SG_ 2415962113 M001_act_U_AnalogPower_IC4_mV "Analog Power Supply Voltage of IC 4 on the module board";
CM_ SG_ 2415958017 M001_act_U_DigiPower_IC1_mV "Digital Power Supply Voltage of IC 1 on the module board";
CM_ SG_ 2415958017 M001_act_U_DigiPower_IC2_mV "Digital Power Supply Voltage of IC 2 on the module board";
CM_ SG_ 2415958017 M001_act_U_DigiPower_IC3_mV "Digital Power Supply Voltage of IC 3 on the module board";
CM_ SG_ 2415958017 M001_act_U_DigiPower_IC4_mV "Digital Power Supply Voltage of IC 4 on the module board";
CM_ SG_ 2415929345 M001_act_U_ModuleVoltage_V "measured module voltage";
CM_ SG_ 2415966209 M001_act_U_RefVoltage_IC1_mV "Reference Voltage of IC 1 on the module board";
CM_ SG_ 2415966209 M001_act_U_RefVoltage_IC2_mV "Reference Voltage of IC 2 on the module board";
CM_ SG_ 2415966209 M001_act_U_RefVoltage_IC3_mV "Reference Voltage of IC 3 on the module board";
CM_ SG_ 2415966209 M001_act_U_RefVoltage_IC4_mV "Reference Voltage of IC 4 on the module board";
CM_ SG_ 2415970305 M001_act_U_SumOfCell_IC1_V "Sum of Cells of IC 1 on the module board";
CM_ SG_ 2415970305 M001_act_U_SumOfCell_IC2_V "Sum of Cells of IC 2 on the module board";
CM_ SG_ 2415970305 M001_act_U_SumOfCell_IC3_V "Sum of Cells of IC 3 on the module board";
CM_ SG_ 2415970305 M001_act_U_SumOfCell_IC4_V "Sum of Cells of IC 4 on the module board";
CM_ SG_ 2415933441 M001_avg_U_CellVoltage_mV_fast "average cell voltage in module";
CM_ SG_ 2415982593 M001_conf_A_CurrentFactorA_mA "calibration current factor A";
CM_ SG_ 2415982593 M001_conf_A_CurrentFactorB_mA "calibration current factor B";
CM_ SG_ 2415982593 M001_conf_A_CurrentOffsetA_mA "calibration current offset A";
CM_ SG_ 2415982593 M001_conf_A_CurrentOffsetB_mA "calibration current offset B";
CM_ SG_ 2415982593 M001_conf_IdxOfTempSensor "Index of temperature sensor";
CM_ SG_ 2550716417 M001_conf_NewCellTypeMajor "new Cell type (Type)";
CM_ SG_ 2415982593 M001_conf_NewCellTypeMajor "new Cell type (Type)";
CM_ SG_ 2550716417 M001_conf_NewCellTypeMinor "new Cell type (Index/revision)";
CM_ SG_ 2415982593 M001_conf_NewCellTypeMinor "new Cell type (Index/revision)";
CM_ SG_ 2550716417 M001_conf_NewICTypeMajor "new IC type (Type)";
CM_ SG_ 2415982593 M001_conf_NewICTypeMajor "new IC type (Type)";
CM_ SG_ 2550716417 M001_conf_NewICTypeMinor "new IC type (Index/revision)";
CM_ SG_ 2415982593 M001_conf_NewICTypeMinor "new IC type (Index/revision)";
CM_ SG_ 2550716417 M001_conf_NewModuleTypeMajor "new module type (Type)";
CM_ SG_ 2415982593 M001_conf_NewModuleTypeMajor "new module type (Type)";
CM_ SG_ 2550716417 M001_conf_NewModuleTypeMinor "new module type (Index/revision)";
CM_ SG_ 2415982593 M001_conf_NewModuleTypeMinor "new module type (Index/revision)";
CM_ SG_ 2550716417 M001_conf_NewPCBTypeMajor "new PCB type (Type)";
CM_ SG_ 2415982593 M001_conf_NewPCBTypeMajor "new PCB type (Type)";
CM_ SG_ 2550716417 M001_conf_NewPCBTypeMinor "new PCB type (Index/revision)";
CM_ SG_ 2415982593 M001_conf_NewPCBTypeMinor "new PCB type (Index/revision)";
CM_ SG_ 2550716417 M001_conf_NewSerialNrHi "new serial number higher part";
CM_ SG_ 2415982593 M001_conf_NewSerialNrHi "new serial number higher part";
CM_ SG_ 2550716417 M001_conf_NewSerialNrLo "new serial number lower part";
CM_ SG_ 2415982593 M001_conf_NewSerialNrLo "new serial number lower part";
CM_ SG_ 2550716417 M001_conf_PCBNewSerialNrHi "PCB new serial number higher part";
CM_ SG_ 2415982593 M001_conf_PCBNewSerialNrHi "PCB new serial number higher part";
CM_ SG_ 2550716417 M001_conf_PCBNewSerialNrLo "PCB new serial number lower part";
CM_ SG_ 2415982593 M001_conf_PCBNewSerialNrLo "PCB new serial number lower part";
CM_ SG_ 2415982593 M001_conf_RefTemperature_C "calibration reference temperature";
CM_ SG_ 2550716417 M001_conf_TopologyMajor "Number of cells in serial";
CM_ SG_ 2415982593 M001_conf_TopologyMajor "Number of cells in serial";
CM_ SG_ 2550716417 M001_conf_TopologyMinor "Number of parallel cells";
CM_ SG_ 2415982593 M001_conf_TopologyMinor "Number of parallel cells";
CM_ SG_ 2415982593 M001_conf_U_VoltageIC1_mV "calibration voltage IC1";
CM_ SG_ 2415982593 M001_conf_U_VoltageIC2_mV "calibration voltage IC2";
CM_ SG_ 2415982593 M001_conf_U_VoltageIC3_mV "calibration voltage IC3";
CM_ SG_ 2415982593 M001_conf_U_VoltageIC4_mV "calibration voltage IC4";
CM_ SG_ 2415941633 M001_flag_BadCRC_IC1 "isoSPI communication error";
CM_ SG_ 2415941633 M001_flag_BadCRC_IC2 "isoSPI communication error";
CM_ SG_ 2415941633 M001_flag_BadCRC_IC3 "isoSPI communication error";
CM_ SG_ 2415941633 M001_flag_BadCRC_IC4 "isoSPI communication error";
CM_ SG_ 2451052545 M001_flag_BalanceCell1 "commands module to balance cell 1";
CM_ SG_ 2451052545 M001_flag_BalanceCell10 "commands module to balance cell 10";
CM_ SG_ 2451052545 M001_flag_BalanceCell11 "commands module to balance cell 11";
CM_ SG_ 2451052545 M001_flag_BalanceCell12 "commands module to balance cell 12";
CM_ SG_ 2451052545 M001_flag_BalanceCell13 "commands module to balance cell 13";
CM_ SG_ 2451052545 M001_flag_BalanceCell14 "commands module to balance cell 14";
CM_ SG_ 2451052545 M001_flag_BalanceCell15 "commands module to balance cell 15";
CM_ SG_ 2451052545 M001_flag_BalanceCell16 "commands module to balance cell 16";
CM_ SG_ 2451052545 M001_flag_BalanceCell17 "commands module to balance cell 17";
CM_ SG_ 2451052545 M001_flag_BalanceCell18 "commands module to balance cell 18";
CM_ SG_ 2451052545 M001_flag_BalanceCell19 "commands module to balance cell 19";
CM_ SG_ 2451052545 M001_flag_BalanceCell2 "commands module to balance cell 2";
CM_ SG_ 2451052545 M001_flag_BalanceCell20 "commands module to balance cell 20";
CM_ SG_ 2451052545 M001_flag_BalanceCell21 "commands module to balance cell 21";
CM_ SG_ 2451052545 M001_flag_BalanceCell22 "commands module to balance cell 22";
CM_ SG_ 2451052545 M001_flag_BalanceCell23 "commands module to balance cell 23";
CM_ SG_ 2451052545 M001_flag_BalanceCell24 "commands module to balance cell 24";
CM_ SG_ 2451052545 M001_flag_BalanceCell25 "commands module to balance cell 25";
CM_ SG_ 2451052545 M001_flag_BalanceCell26 "commands module to balance cell 26";
CM_ SG_ 2451052545 M001_flag_BalanceCell27 "commands module to balance cell 27";
CM_ SG_ 2451052545 M001_flag_BalanceCell28 "commands module to balance cell 28";
CM_ SG_ 2451052545 M001_flag_BalanceCell29 "commands module to balance cell 29";
CM_ SG_ 2451052545 M001_flag_BalanceCell3 "commands module to balance cell 3";
CM_ SG_ 2451052545 M001_flag_BalanceCell30 "commands module to balance cell 30";
CM_ SG_ 2451052545 M001_flag_BalanceCell31 "commands module to balance cell 31";
CM_ SG_ 2451052545 M001_flag_BalanceCell32 "commands module to balance cell 32";
CM_ SG_ 2451052545 M001_flag_BalanceCell4 "commands module to balance cell 4";
CM_ SG_ 2451052545 M001_flag_BalanceCell5 "commands module to balance cell 5";
CM_ SG_ 2451052545 M001_flag_BalanceCell6 "commands module to balance cell 6";
CM_ SG_ 2451052545 M001_flag_BalanceCell7 "commands module to balance cell 7";
CM_ SG_ 2451052545 M001_flag_BalanceCell8 "commands module to balance cell 8";
CM_ SG_ 2451052545 M001_flag_BalanceCell9 "commands module to balance cell 9";
CM_ SG_ 2415941633 M001_flag_CalibrationDone "shows if module is calibrated";
CM_ SG_ 2415941633 M001_flag_CalibrationError "shows if there was an error while calibrating or calibration data is out of limits";
CM_ SG_ 2415941633 M001_flag_CalibrationIncomp "shows if calibration data is missing";
CM_ SG_ 2415941633 M001_flag_ComplDynAreaCRCErr "both EEPROM dynamic areas contain a bad CRC";
CM_ SG_ 2415941633 M001_flag_ComplSafAreaCRCErr "both EEPROM safety areas contain a bad CRC";
CM_ SG_ 2415941633 M001_flag_ComplStatAreaCRCErr "both EEPROM static areas contain a bad CRC";
CM_ SG_ 2415941633 M001_flag_ConfigDone "shows if serial number has been set and topology has been set and locked";
CM_ SG_ 2415941633 M001_flag_DynAreaReadFail "reading EEPROM dynamic area failed";
CM_ SG_ 2415941633 M001_flag_DynAreaWriteFail "writing EEPROM dynamic area failed";
CM_ SG_ 2415941633 M001_flag_EEPROMError "shows if there was an error while reading/writig to EEPROM";
CM_ SG_ 2415941633 M001_flag_EEPROMReadFail "reading all EEPROM content failed";
CM_ SG_ 2415941633 M001_flag_I2CCommunicationFail "I2C communication error";
CM_ SG_ 2415941633 M001_flag_IDPageNotLocked "EEPROM ID page is not locked";
CM_ SG_ 2415941633 M001_flag_IDPageStatusReadFail "reading EEPROM ID page status failed";
CM_ SG_ 2415941633 M001_flag_InitialisationFail "isoSPI module in BMU was not initalised successfully";
CM_ SG_ 2415941633 M001_flag_NoSafRel_BadCRC_IC1 "isoSPI communication error during execution any not safety relevant command";
CM_ SG_ 2415941633 M001_flag_NoSafRel_BadCRC_IC2 "isoSPI communication error during execution any not safety relevant command";
CM_ SG_ 2415941633 M001_flag_NoSafRel_BadCRC_IC3 "isoSPI communication error during execution any not safety relevant command";
CM_ SG_ 2415941633 M001_flag_NoSafRel_BadCRC_IC4 "isoSPI communication error during execution any not safety relevant command";
CM_ SG_ 2415941633 M001_flag_NoSafRel_PollTimeout "isoSPI ADC polling timeout or too many ICs connected during execution of any not safety relevant command";
CM_ SG_ 2415974401 M001_flag_OvervoltageCell1 "Flag for overvoltage of cell 1";
CM_ SG_ 2415974401 M001_flag_OvervoltageCell10 "Flag for overvoltage of cell 10";
CM_ SG_ 2415974401 M001_flag_OvervoltageCell11 "Flag for overvoltage of cell 11";
CM_ SG_ 2415974401 M001_flag_OvervoltageCell12 "Flag for overvoltage of cell 12";
CM_ SG_ 2415974401 M001_flag_OvervoltageCell13 "Flag for overvoltage of cell 13";
CM_ SG_ 2415974401 M001_flag_OvervoltageCell14 "Flag for overvoltage of cell 14";
CM_ SG_ 2415974401 M001_flag_OvervoltageCell15 "Flag for overvoltage of cell 15";
CM_ SG_ 2415974401 M001_flag_OvervoltageCell16 "Flag for overvoltage of cell 16";
CM_ SG_ 2415974401 M001_flag_OvervoltageCell17 "Flag for overvoltage of cell 17";
CM_ SG_ 2415974401 M001_flag_OvervoltageCell18 "Flag for overvoltage of cell 18";
CM_ SG_ 2415974401 M001_flag_OvervoltageCell19 "Flag for overvoltage of cell 19";
CM_ SG_ 2415974401 M001_flag_OvervoltageCell2 "Flag for overvoltage of cell 2";
CM_ SG_ 2415974401 M001_flag_OvervoltageCell20 "Flag for overvoltage of cell 20";
CM_ SG_ 2415974401 M001_flag_OvervoltageCell21 "Flag for overvoltage of cell 21";
CM_ SG_ 2415974401 M001_flag_OvervoltageCell22 "Flag for overvoltage of cell 22";
CM_ SG_ 2415974401 M001_flag_OvervoltageCell23 "Flag for overvoltage of cell 23";
CM_ SG_ 2415974401 M001_flag_OvervoltageCell24 "Flag for overvoltage of cell 24";
CM_ SG_ 2415974401 M001_flag_OvervoltageCell25 "Flag for overvoltage of cell 25";
CM_ SG_ 2415974401 M001_flag_OvervoltageCell26 "Flag for overvoltage of cell 26";
CM_ SG_ 2415974401 M001_flag_OvervoltageCell27 "Flag for overvoltage of cell 27";
CM_ SG_ 2415974401 M001_flag_OvervoltageCell28 "Flag for overvoltage of cell 28";
CM_ SG_ 2415974401 M001_flag_OvervoltageCell29 "Flag for overvoltage of cell 29";
CM_ SG_ 2415974401 M001_flag_OvervoltageCell3 "Flag for overvoltage of cell 3";
CM_ SG_ 2415974401 M001_flag_OvervoltageCell30 "Flag for overvoltage of cell 30";
CM_ SG_ 2415974401 M001_flag_OvervoltageCell31 "Flag for overvoltage of cell 31";
CM_ SG_ 2415974401 M001_flag_OvervoltageCell32 "Flag for overvoltage of cell 32";
CM_ SG_ 2415974401 M001_flag_OvervoltageCell33 "Flag for overvoltage of cell 33";
CM_ SG_ 2415974401 M001_flag_OvervoltageCell34 "Flag for overvoltage of cell 34";
CM_ SG_ 2415974401 M001_flag_OvervoltageCell35 "Flag for overvoltage of cell 35";
CM_ SG_ 2415974401 M001_flag_OvervoltageCell36 "Flag for overvoltage of cell 36";
CM_ SG_ 2415974401 M001_flag_OvervoltageCell37 "Flag for overvoltage of cell 37";
CM_ SG_ 2415974401 M001_flag_OvervoltageCell38 "Flag for overvoltage of cell 38";
CM_ SG_ 2415974401 M001_flag_OvervoltageCell39 "Flag for overvoltage of cell 39";
CM_ SG_ 2415974401 M001_flag_OvervoltageCell4 "Flag for overvoltage of cell 4";
CM_ SG_ 2415974401 M001_flag_OvervoltageCell40 "Flag for overvoltage of cell 40";
CM_ SG_ 2415974401 M001_flag_OvervoltageCell5 "Flag for overvoltage of cell 5";
CM_ SG_ 2415974401 M001_flag_OvervoltageCell6 "Flag for overvoltage of cell 6";
CM_ SG_ 2415974401 M001_flag_OvervoltageCell7 "Flag for overvoltage of cell 7";
CM_ SG_ 2415974401 M001_flag_OvervoltageCell8 "Flag for overvoltage of cell 8";
CM_ SG_ 2415974401 M001_flag_OvervoltageCell9 "Flag for overvoltage of cell 9";
CM_ SG_ 2415941633 M001_flag_PollTimeout "isoSPI ADC polling timeout or too many ICs connected";
CM_ SG_ 2415941633 M001_flag_SM_BadCRC_IC1 "isoSPI communication error during execution of any safety mechanism";
CM_ SG_ 2415941633 M001_flag_SM_BadCRC_IC2 "isoSPI communication error during execution of any safety mechanism";
CM_ SG_ 2415941633 M001_flag_SM_BadCRC_IC3 "isoSPI communication error during execution of any safety mechanism";
CM_ SG_ 2415941633 M001_flag_SM_BadCRC_IC4 "isoSPI communication error during execution of any safety mechanism";
CM_ SG_ 2415941633 M001_flag_SM_PollTimeout "isoSPI ADC polling timeout or too many ICs connected during execution of any safety mechanism";
CM_ SG_ 2415941633 M001_flag_SafAreaMismatch "CRC of both EEPROM safety areas is correct, but content doesn't match";
CM_ SG_ 2415941633 M001_flag_SafAreaReadFail "reading EEPROM safety area failed";
CM_ SG_ 2415941633 M001_flag_SafAreaWriteFail "writing EEPROM safety area failed";
CM_ SG_ 2415941633 M001_flag_SelfTestPassed "shows if all self-tests have been passed";
CM_ SG_ 2415941633 M001_flag_SerialMiss "shows if module serial number has not been set";
CM_ SG_ 2415941633 M001_flag_SingleDynAreaCRCErr "one of EEPROM dynamic areas is corrupted";
CM_ SG_ 2415941633 M001_flag_SingleSafAreaCRCErr "one of EEPROM safety areas is corrupted";
CM_ SG_ 2415941633 M001_flag_SingleStatAreaCRCErr "one of EEPROM static areas is corrupted";
CM_ SG_ 2415941633 M001_flag_StatAreaMismatch "CRC of both EEPROM static areas is correct, but content doesn't match";
CM_ SG_ 2415941633 M001_flag_StatAreaReadFail "reading EEPROM static area failed";
CM_ SG_ 2415941633 M001_flag_StatreaWriteFail "writing EEPROM static area failed";
CM_ SG_ 2415941633 M001_flag_TempCalErr "shows if there has been an error with the temperature calibration";
CM_ SG_ 2415941633 M001_flag_ThermalShtDwn_IC1 "shows if IC 1 has a temperature over 125 °C";
CM_ SG_ 2415941633 M001_flag_ThermalShtDwn_IC2 "shows if IC 2 has a temperature over 125 °C";
CM_ SG_ 2415941633 M001_flag_ThermalShtDwn_IC3 "shows if IC 3 has a temperature over 125 °C";
CM_ SG_ 2415941633 M001_flag_ThermalShtDwn_IC4 "shows if IC 4 has a temperature over 125 °C";
CM_ SG_ 2415978497 M001_flag_UndervoltageCell1 "Flag for undervoltage of cell 1";
CM_ SG_ 2415978497 M001_flag_UndervoltageCell10 "Flag for undervoltage of cell 10";
CM_ SG_ 2415978497 M001_flag_UndervoltageCell11 "Flag for undervoltage of cell 11";
CM_ SG_ 2415978497 M001_flag_UndervoltageCell12 "Flag for undervoltage of cell 12";
CM_ SG_ 2415978497 M001_flag_UndervoltageCell13 "Flag for undervoltage of cell 13";
CM_ SG_ 2415978497 M001_flag_UndervoltageCell14 "Flag for undervoltage of cell 14";
CM_ SG_ 2415978497 M001_flag_UndervoltageCell15 "Flag for undervoltage of cell 15";
CM_ SG_ 2415978497 M001_flag_UndervoltageCell16 "Flag for undervoltage of cell 16";
CM_ SG_ 2415978497 M001_flag_UndervoltageCell17 "Flag for undervoltage of cell 17";
CM_ SG_ 2415978497 M001_flag_UndervoltageCell18 "Flag for undervoltage of cell 18";
CM_ SG_ 2415978497 M001_flag_UndervoltageCell19 "Flag for undervoltage of cell 19";
CM_ SG_ 2415978497 M001_flag_UndervoltageCell2 "Flag for undervoltage of cell 2";
CM_ SG_ 2415978497 M001_flag_UndervoltageCell20 "Flag for undervoltage of cell 20";
CM_ SG_ 2415978497 M001_flag_UndervoltageCell21 "Flag for undervoltage of cell 21";
CM_ SG_ 2415978497 M001_flag_UndervoltageCell22 "Flag for undervoltage of cell 22";
CM_ SG_ 2415978497 M001_flag_UndervoltageCell23 "Flag for undervoltage of cell 23";
CM_ SG_ 2415978497 M001_flag_UndervoltageCell24 "Flag for undervoltage of cell 24";
CM_ SG_ 2415978497 M001_flag_UndervoltageCell25 "Flag for undervoltage of cell 25";
CM_ SG_ 2415978497 M001_flag_UndervoltageCell26 "Flag for undervoltage of cell 26";
CM_ SG_ 2415978497 M001_flag_UndervoltageCell27 "Flag for undervoltage of cell 27";
CM_ SG_ 2415978497 M001_flag_UndervoltageCell28 "Flag for undervoltage of cell 28";
CM_ SG_ 2415978497 M001_flag_UndervoltageCell29 "Flag for undervoltage of cell 29";
CM_ SG_ 2415978497 M001_flag_UndervoltageCell3 "Flag for undervoltage of cell 3";
CM_ SG_ 2415978497 M001_flag_UndervoltageCell30 "Flag for undervoltage of cell 30";
CM_ SG_ 2415978497 M001_flag_UndervoltageCell31 "Flag for undervoltage of cell 31";
CM_ SG_ 2415978497 M001_flag_UndervoltageCell32 "Flag for undervoltage of cell 32";
CM_ SG_ 2415978497 M001_flag_UndervoltageCell33 "Flag for undervoltage of cell 33";
CM_ SG_ 2415978497 M001_flag_UndervoltageCell34 "Flag for undervoltage of cell 34";
CM_ SG_ 2415978497 M001_flag_UndervoltageCell35 "Flag for undervoltage of cell 35";
CM_ SG_ 2415978497 M001_flag_UndervoltageCell36 "Flag for undervoltage of cell 36";
CM_ SG_ 2415978497 M001_flag_UndervoltageCell37 "Flag for undervoltage of cell 37";
CM_ SG_ 2415978497 M001_flag_UndervoltageCell38 "Flag for undervoltage of cell 38";
CM_ SG_ 2415978497 M001_flag_UndervoltageCell39 "Flag for undervoltage of cell 39";
CM_ SG_ 2415978497 M001_flag_UndervoltageCell4 "Flag for undervoltage of cell 4";
CM_ SG_ 2415978497 M001_flag_UndervoltageCell40 "Flag for undervoltage of cell 40";
CM_ SG_ 2415978497 M001_flag_UndervoltageCell5 "Flag for undervoltage of cell 5";
CM_ SG_ 2415978497 M001_flag_UndervoltageCell6 "Flag for undervoltage of cell 6";
CM_ SG_ 2415978497 M001_flag_UndervoltageCell7 "Flag for undervoltage of cell 7";
CM_ SG_ 2415978497 M001_flag_UndervoltageCell8 "Flag for undervoltage of cell 8";
CM_ SG_ 2415978497 M001_flag_UndervoltageCell9 "Flag for undervoltage of cell 9";
CM_ SG_ 2415941633 M001_flag_VerifyDynWriteFail "writing EEPROM dynamic area was not successful";
CM_ SG_ 2415941633 M001_flag_VerifySafWriteFail "writing EEPROM safety area was not successful";
CM_ SG_ 2415941633 M001_flag_VerifyStatWriteFail "writing EEPROM static area was not successful";
CM_ SG_ 2415941633 M001_flag_WDGError "shows if Watchdog has been triggered";
CM_ SG_ 2415937537 M001_inf_CellTypeMajor "used Cell Type (Type)";
CM_ SG_ 2415937537 M001_inf_CellTypeMinor "used Cell Type (Index/revision)";
CM_ SG_ 2415937537 M001_inf_ParallelCells "Number of parallel Cells";
CM_ SG_ 2415937537 M001_inf_SerialCells "Number of Cells in series";
CM_ SG_ 2415933441 M001_max_U_CellVoltage_mV_fast "highest cell voltage in module";
CM_ SG_ 2415933441 M001_min_U_CellVoltage_mV_fast "lowest cell voltage in module";
CM_ SG_ 2415925249 M001_raw_DewSens "raw value of Dew Sensor ADC (optional)";
CM_ SG_ 2416478209 M001_val_ActionIndex "Index of action";
CM_ SG_ 2415949825 M001_val_EEPROMData "EEPROM data";
CM_ SG_ 2415949825 M001_val_EEPROMIndex "Index of EEPROM Data";
CM_ SG_ 2416474113 M001_val_EEPROMWriteData "EEPROM write data";
CM_ SG_ 2416474113 M001_val_EEPROMWriteIndex "Index of written EEPROM Data";
CM_ SG_ 2416478209 M001_val_Magic "Magic to ensure safety";
CM_ SG_ 2449482753 SCU1_act_HighsideSwitch1_pct "% value of highside switch 1";
CM_ SG_ 2449482753 SCU1_act_HighsideSwitch2_pct "% value of highside switch 2";
CM_ SG_ 2449482753 SCU1_act_HighsideSwitch3_pct "% value of highside switch 3";
CM_ SG_ 2449482753 SCU1_act_HighsideSwitch4_pct "% value of highside switch 4";
CM_ SG_ 2449490945 SCU1_act_I_CoilCurrContAux_mA "coil current of aux contactor";
CM_ SG_ 2449490945 SCU1_act_I_CoilCurrContNeg_mA "coil current of - contactor";
CM_ SG_ 2449490945 SCU1_act_I_CoilCurrContPos_mA "coil current of + contactor";
CM_ SG_ 2449490945 SCU1_act_I_CoilCurrContPre_mA "coil current of precharge contactor";
CM_ SG_ 2315277313 SCU1_act_I_CurrentSens2High_A "second current sensor (high)";
CM_ SG_ 2315277313 SCU1_act_I_CurrentSens2Low_A "second current sensor (low)";
CM_ SG_ 2315277313 SCU1_act_I_CurrentSensHigh_A "current sensor (high)";
CM_ SG_ 2315277313 SCU1_act_I_CurrentSensLow_A "current sensor (low)";
CM_ SG_ 2449536001 SCU1_act_I_CurrentSensTot_A "current sensor total (for multi current sensor systems)";
CM_ SG_ 2449486849 SCU1_act_I_HSSwitch1Curr_mA "current of highside switch 1";
CM_ SG_ 2449486849 SCU1_act_I_HSSwitch2Curr_mA "current of highside switch 2";
CM_ SG_ 2449486849 SCU1_act_I_HSSwitch3Curr_mA "current of highside switch 3";
CM_ SG_ 2449486849 SCU1_act_I_HSSwitch4Curr_mA "current of highside switch 4";
CM_ SG_ 2449536001 SCU1_act_I_HVIL_mA "current of interlock loop";
CM_ SG_ 2449536001 SCU1_act_I_eStop_mA "current of eStop loop";
CM_ SG_ 2449499137 SCU1_act_T_BoardTemperature_C "Board Temperature (measured by ADC)";
CM_ SG_ 2449503233 SCU1_act_U_BMMSafe_V "BMM safe power";
CM_ SG_ 2315318273 SCU1_act_U_BatNeg_V "Bat-";
CM_ SG_ 2315314177 SCU1_act_U_BatPos_V "Bat+";
CM_ SG_ 2449511425 SCU1_act_U_ChassisGndVoltage_V "chassis to ground voltage";
CM_ SG_ 2449503233 SCU1_act_U_Contact30_V "KL30";
CM_ SG_ 2449503233 SCU1_act_U_HSSupply12_V "Highside- Switch-Powersupply voltage 1-2";
CM_ SG_ 2449503233 SCU1_act_U_HSSupply34_V "Highside- Switch-Powersupply voltage 3-4";
CM_ SG_ 2449511425 SCU1_act_U_ReferenceVoltage_V "independent SCU reference voltage";
CM_ SG_ 2315318273 SCU1_act_U_SysNeg_V "Sys-";
CM_ SG_ 2315314177 SCU1_act_U_SysPos_V "Sys+";
CM_ SG_ 2583725057 SCU1_act_U_TrayNegExt_V "Tray- extern";
CM_ SG_ 2583725057 SCU1_act_U_TrayNegInt_V "Tray- intern";
CM_ SG_ 2583725057 SCU1_act_U_TrayPosExt_V "Tray+ to ground extern";
CM_ SG_ 2583725057 SCU1_act_U_TrayPosInt_V "Tray+ intern";
CM_ SG_ 2449511425 SCU1_act_U_TrayVoltageLocal_V "Tray local HV voltage";
CM_ SG_ 2449499137 SCU1_act_V_SenseExt1_mV "External Voltage Sensor 1";
CM_ SG_ 2449499137 SCU1_act_V_SenseExt2_mV "External Voltage Sensor 2";
CM_ SG_ 2449527809 SCU1_af_BoardTemp "ECU/IC board temperature too high/low";
CM_ SG_ 2449527809 SCU1_af_ContDam "contactors damaged";
CM_ SG_ 2449527809 SCU1_af_ContactorDropOut "a contactor drop out occured";
CM_ SG_ 2449527809 SCU1_af_ContactorWrongState "tbd";
CM_ SG_ 2449527809 SCU1_af_CurrSens "i sensor error occurred";
CM_ SG_ 2449527809 SCU1_af_InvalidData "short circuit or open temperature sensor";
CM_ SG_ 2449527809 SCU1_af_KL30SafeMax "KL30-Safe max";
CM_ SG_ 2449527809 SCU1_af_KL30SafeMin "KL30-Safe min";
CM_ SG_ 2449527809 SCU1_af_KL30SafeOff "BMS-M-SafePwr was switched off (HW detection)";
CM_ SG_ 2449527809 SCU1_af_RefVoltErrorMax "refernce voltage to high";
CM_ SG_ 2449527809 SCU1_af_RefVoltErrorMin "refernce voltage to low";
CM_ SG_ 2315342849 SCU1_ctr_DamageTotal "contactor damage";
CM_ SG_ 2449568769 SCU1_ctr_Q_AmpereHourChg_Ah "alltime ampere hour counter charge";
CM_ SG_ 2449568769 SCU1_ctr_Q_AmpereHourDisch_Ah "alltime ampere hour counter discharge";
CM_ SG_ 2449564673 SCU1_ctr_t_AliveTime_s "Time the SCU has been powered up";
CM_ SG_ 2449564673 SCU1_ctr_t_OperationTime_s "Time in which the pos and neg contactors are closed";
CM_ SG_ 2449576961 SCU1_diag_HistIndex "Index number";
CM_ SG_ 2449576961 SCU1_diag_HistIndexWert "Index value";
CM_ SG_ 2449576961 SCU1_diag_HistMultiplex "Histogram multiplexer (see Comments)";
CM_ SG_ 2449576961 SCU1_diag_HistWerte "Histogram value";
CM_ SG_ 2449515521 SCU1_diag_U_TrayNegExt_U_frz "Tray- extern";
CM_ SG_ 2449515521 SCU1_diag_U_TrayNegInt_U_frz "Tray- intern";
CM_ SG_ 2449515521 SCU1_diag_U_TrayPosExt_U_frz "Tray+ extern";
CM_ SG_ 2449515521 SCU1_diag_U_TrayPosInt_U_frz "Tray+ intern";
CM_ SG_ 2449519617 SCU1_err_Level "error level";
CM_ SG_ 2449519617 SCU1_err_Number "error number";
CM_ SG_ 2449519617 SCU1_err_Source "error source";
CM_ SG_ 2449519617 SCU1_err_Value "error value";
CM_ SG_ 2281706497 SCU1_flag_Alarm "alarm flag";
CM_ SG_ 2281706497 SCU1_flag_BMMSafe "status of BMM safe";
CM_ SG_ 2281706497 SCU1_flag_CAN1BusOff "bus off state of CAN bus 1";
CM_ SG_ 2281706497 SCU1_flag_CAN2BusOff "bus off state of CAN bus 2";
CM_ SG_ 2281706497 SCU1_flag_CANGatewayStatus "status of CAN gateway";
CM_ SG_ 2281706497 SCU1_flag_CompChipWarning "state of companion chip warning";
CM_ SG_ 2281706497 SCU1_flag_ContStuckChk "state of contactor stuck at check";
CM_ SG_ 2281706497 SCU1_flag_EoL_Mode "state of the EoL mode";
CM_ SG_ 2281706497 SCU1_flag_ExtAuxStuckChk "state of extended aux contactor stuck at check";
CM_ SG_ 2281706497 SCU1_flag_ForceSave "state of force save state";
CM_ SG_ 2281706497 SCU1_flag_HSS1Locked "switch on protection after thermal shut off of power MOS-FET";
CM_ SG_ 2281706497 SCU1_flag_HSS2Locked "switch on protection after thermal shut off of power MOS-FET";
CM_ SG_ 2281706497 SCU1_flag_HSS3Locked "switch on protection after thermal shut off of power MOS-FET";
CM_ SG_ 2281706497 SCU1_flag_HSS4Locked "switch on protection after thermal shut off of power MOS-FET";
CM_ SG_ 2281706497 SCU1_flag_InterLockError "status of interlock (current is out of range)";
CM_ SG_ 2281706497 SCU1_flag_InterventioneStop "status of intervention of SCU on eStop loop";
CM_ SG_ 2281706497 SCU1_flag_KL15 "status of KL 15";
CM_ SG_ 2281706497 SCU1_flag_Led1 "status od LED 1";
CM_ SG_ 2281706497 SCU1_flag_Led2 "status of LED 2";
CM_ SG_ 2281706497 SCU1_flag_Led3 "status of LED 3";
CM_ SG_ 2281706497 SCU1_flag_PowerContExtAux "state of extended aux power contactor";
CM_ SG_ 2281706497 SCU1_flag_PowerContNeg "state of power contactor -";
CM_ SG_ 2281706497 SCU1_flag_PowerContPos "state of power contactor +";
CM_ SG_ 2281706497 SCU1_flag_PowerContPre "state of power contactor precharge";
CM_ SG_ 2281706497 SCU1_flag_PowerProtWarning "state of power protection warning";
CM_ SG_ 2281706497 SCU1_flag_PrechargeOK "Completed precharge successfully";
CM_ SG_ 2281706497 SCU1_flag_SafetyEnable1 "state of safety enable 1";
CM_ SG_ 2281706497 SCU1_flag_SafetyEnable2 "state of safety enable 2";
CM_ SG_ 2281706497 SCU1_flag_ShuntResCalibration "state of the shunt resistance calibration";
CM_ SG_ 2281706497 SCU1_flag_SilentCan1 "management message CAN_1 has been silenced";
CM_ SG_ 2281706497 SCU1_flag_SilentCan2 "management message CAN_2 has been silenced";
CM_ SG_ 2281706497 SCU1_flag_SourceInterlockLoop "status of SCU source of interlock loop";
CM_ SG_ 2281706497 SCU1_flag_SupplyMonitorWarning "status of supply monitor warning";
CM_ SG_ 2281706497 SCU1_flag_VSenserelayNegExt "state of sense relay Tray- extern";
CM_ SG_ 2281706497 SCU1_flag_VSenserelayNegInt "state of sense relay Tray- intern";
CM_ SG_ 2281706497 SCU1_flag_VSenserelayPosExt "state of sense relay Tray+ extern";
CM_ SG_ 2281706497 SCU1_flag_VSenserelayPosInt "state of sense relay Tray+ intern";
CM_ SG_ 2281706497 SCU1_flag_Warning "warning flag";
CM_ SG_ 2281706497 SCU1_flag_eStopBrakeOut "state of eStop brake out";
CM_ SG_ 2281706497 SCU1_flag_eStopLoopNotClosed "status of eStop loop";
CM_ SG_ 2449540097 SCU1_inf_Checksum "checksum of the software configuration";
CM_ SG_ 2449556481 SCU1_inf_HighCellNr "highest monitored cell number";
CM_ SG_ 2449556481 SCU1_inf_HighModNr "highest monitored module number";
CM_ SG_ 2449556481 SCU1_inf_LowCellNr "lowest monitored cell number";
CM_ SG_ 2449556481 SCU1_inf_LowModNr "lowest monitored module number";
CM_ SG_ 2449540097 SCU1_inf_NumOfCell "number of serial cells per module";
CM_ SG_ 2449540097 SCU1_inf_NumOfModule "number of modules";
CM_ SG_ 2449552385 SCU1_lim_T_MaxTemp_C "maximum temperature limit";
CM_ SG_ 2449552385 SCU1_lim_T_MinTemp_C "minimum temperature limit";
CM_ SG_ 2449552385 SCU1_lim_U_MaxVolt_V "maximum voltage limit";
CM_ SG_ 2449552385 SCU1_lim_U_MinVolt_V "minimun voltage limit";
CM_ SG_ 2651096065 SCU1_raw_ActOffsetIHighChannel "actual offset of current sensor high channel";
CM_ SG_ 2651067393 SCU1_raw_BMMSafeVoltage "ADC raw value of BMM Safe voltage";
CM_ SG_ 2651091969 SCU1_raw_CPULoadAvg "Scu cycle load";
CM_ SG_ 2651091969 SCU1_raw_CPULoadMax "Scu max cycle load";
CM_ SG_ 2651079681 SCU1_raw_ContExtAuxCoilCurr "ADC raw value of extaux contactor coil current";
CM_ SG_ 2651079681 SCU1_raw_ContNegCoilCurr "ADC raw value of neg contactor coil current";
CM_ SG_ 2651079681 SCU1_raw_ContPosCoilCurr "ADC raw value of pos contactor coil current";
CM_ SG_ 2651079681 SCU1_raw_ContPreCoilCurr "ADC raw value of pre contactor coil current";
CM_ SG_ 2651100161 SCU1_raw_DIO_ESR0_In "DIin_Comp_Chip_Warning";
CM_ SG_ 2651100161 SCU1_raw_DIO_ESR1_In "DIin_CPU_Supply_Warning";
CM_ SG_ 2651100161 SCU1_raw_DIO_ESR2_In "DIin_Power_Protection_Warning";
CM_ SG_ 2651100161 SCU1_raw_DIO_P02_00_In "DIin_Forced_Save_State";
CM_ SG_ 2651100161 SCU1_raw_DIO_P02_01_In "DIin_BMS_S_Safe_State";
CM_ SG_ 2651100161 SCU1_raw_DIO_P02_02_In "DIin_KL15_WAKE";
CM_ SG_ 2651100161 SCU1_raw_DIO_P02_05_Out "DIin_HW_Version_Bit_0";
CM_ SG_ 2651100161 SCU1_raw_DIO_P02_06_In "DIin_HW_Version_Bit_1";
CM_ SG_ 2651100161 SCU1_raw_DIO_P02_07_In "DIin_KL30_Safe_OK";
CM_ SG_ 2651100161 SCU1_raw_DIO_P02_12_Out "DIout_CAN_Gateway";
CM_ SG_ 2651100161 SCU1_raw_DIO_P03_03_Out "DIout_SPI_1_CS_0      Chip select 0 am SPI Bus 1";
CM_ SG_ 2651100161 SCU1_raw_DIO_P03_04_Out "DIout_SPI_1_CS_1      Chip select 1 am SPI Bus 1";
CM_ SG_ 2651100161 SCU1_raw_DIO_P04_04_Out "DIout_HV_MR_BatPlus   HV-Messrelais Bat+";
CM_ SG_ 2651100161 SCU1_raw_DIO_P04_05_Out "DIout_HV_MR_BatMinus  HV-Messrelais Bat-";
CM_ SG_ 2651100161 SCU1_raw_DIO_P04_06_Out "DIout_HV_MR_SysPlus   HV-Messrelais Sys+";
CM_ SG_ 2651100161 SCU1_raw_DIO_P04_07_Out "DIout_HV_MR_SysMinus  HV-Messrelais Sys-";
CM_ SG_ 2651100161 SCU1_raw_DIO_P06_02_Out "DIout_eStop_Brake_Out";
CM_ SG_ 2651100161 SCU1_raw_DIO_P06_03_Out "DIout_Safety_Enable2";
CM_ SG_ 2651100161 SCU1_raw_DIO_P07_01_Out "DIout_Safety_Enable1";
CM_ SG_ 2651100161 SCU1_raw_DIO_P07_02_Out "DIout_External_Watchdog";
CM_ SG_ 2651100161 SCU1_raw_DIO_P08_03_Out "DIout_HS_Switch_1";
CM_ SG_ 2651100161 SCU1_raw_DIO_P08_04_Out "DIout_HS_Switch_2";
CM_ SG_ 2651100161 SCU1_raw_DIO_P08_05_Out "DIout_HS_Switch_3";
CM_ SG_ 2651100161 SCU1_raw_DIO_P08_06_Out "DIout_HS_Switch_4";
CM_ SG_ 2651100161 SCU1_raw_DIO_P09_00_BiIO "DIout_Alive_LED";
CM_ SG_ 2651100161 SCU1_raw_DIO_P09_01_Out "DIout_Debug_LED";
CM_ SG_ 2651100161 SCU1_raw_DIO_P09_02_Out "DIout_Error_LED";
CM_ SG_ 2651100161 SCU1_raw_DIO_P09_03_Out "DIio_OW_Port_1     on wire bus no 1";
CM_ SG_ 2651100161 SCU1_raw_DIO_P09_04_Out "DIout_Con_HV_plus";
CM_ SG_ 2651100161 SCU1_raw_DIO_P09_05_BiIO "DIout_Con_HV_minus";
CM_ SG_ 2651100161 SCU1_raw_DIO_P09_06_BiIO "DIout_Con_Precharge";
CM_ SG_ 2651100161 SCU1_raw_DIO_P09_07_BiIO "DIout_Con_Ext_Aux";
CM_ SG_ 2651100161 SCU1_raw_DIO_P10_08_BiIO "DIio_ExtID_Bit0";
CM_ SG_ 2651100161 SCU1_raw_DIO_P10_09_BiIO "DIio_ExtID_Bit1";
CM_ SG_ 2651100161 SCU1_raw_DIO_P10_10_Out "DIio_ExtID_Bit2";
CM_ SG_ 2651100161 SCU1_raw_DIO_P10_11_Out "DIio_ExtID_Bit3";
CM_ SG_ 2651100161 SCU1_raw_DIO_P10_12_Out "DIio_ExtID_Bit4";
CM_ SG_ 2651100161 SCU1_raw_DIO_P11_02_Out "DIout_Interlock_SrcOn";
CM_ SG_ 2651100161 SCU1_raw_DIO_P11_03_Out "DIout_Interlock_HC";
CM_ SG_ 2651100161 SCU1_raw_DIO_P11_04_Out "DIout_SCU_Power";
CM_ SG_ 2651100161 SCU1_raw_DIO_P11_05_Out "DIout_BMS_Power";
CM_ SG_ 2651063297 SCU1_raw_ErrorCodePosition "error code position";
CM_ SG_ 2651063297 SCU1_raw_ErrorNumber "error number";
CM_ SG_ 2651063297 SCU1_raw_ErrorParameter1 "error parameter 1";
CM_ SG_ 2651063297 SCU1_raw_ErrorParameter2 "error parameter 2";
CM_ SG_ 2651075585 SCU1_raw_ExtSense1 "ADC raw value of external sense 1";
CM_ SG_ 2651075585 SCU1_raw_ExtSense2 "ADC raw value of external sense 2";
CM_ SG_ 2651067393 SCU1_raw_HSS12Voltage "ADC raw value of HSS12 voltage";
CM_ SG_ 2651071489 SCU1_raw_HSS34Voltage "ADC raw value of HSS34 voltage";
CM_ SG_ 2651087873 SCU1_raw_HSSwitch1Curr "ADC raw value of high side switch 1";
CM_ SG_ 2651087873 SCU1_raw_HSSwitch2Curr "ADC raw value of high side switch 2";
CM_ SG_ 2651087873 SCU1_raw_HSSwitch3Curr "ADC raw value of high side switch 3";
CM_ SG_ 2651087873 SCU1_raw_HSSwitch4Curr "ADC raw value of high side switch 4";
CM_ SG_ 2651096065 SCU1_raw_HysteresisOffset "calculated value of the hysteresis offset";
CM_ SG_ 2651104257 SCU1_raw_ID_Combi "SCU ID combination no.";
CM_ SG_ 2651104257 SCU1_raw_ID_bit_0 "Input of SCU ID 0";
CM_ SG_ 2651104257 SCU1_raw_ID_bit_1 "Input of SCU ID 1";
CM_ SG_ 2651104257 SCU1_raw_ID_bit_2 "Input of SCU ID 2";
CM_ SG_ 2651104257 SCU1_raw_ID_bit_3 "Input of SCU ID 3";
CM_ SG_ 2651104257 SCU1_raw_ID_bit_4 "Input of SCU ID 4";
CM_ SG_ 2651083777 SCU1_raw_ILockLoopCurr "ADC raw value of interlock Current";
CM_ SG_ 2651083777 SCU1_raw_ISenseHighCurr "ADC raw value of current sensor high channel";
CM_ SG_ 2651083777 SCU1_raw_ISenseLowCurr "ADC raw value of current sensor low channel";
CM_ SG_ 2651067393 SCU1_raw_KL30Voltage "ADC raw value of KL30 voltage";
CM_ SG_ 2651096065 SCU1_raw_MagneticMarker "calculated value of the magnetic marker";
CM_ SG_ 2651096065 SCU1_raw_NonOffsetIHighChannel "current sensor high channel without offset";
CM_ SG_ 2651067393 SCU1_raw_ReferenceVoltage "ADC raw value of SCU reference voltage";
CM_ SG_ 2651104257 SCU1_raw_T1_BMSCAN "cell test temperature of cell 1";
CM_ SG_ 2651071489 SCU1_raw_TrayBatVoltNeg "ADC raw value of bat neg voltage";
CM_ SG_ 2651071489 SCU1_raw_TrayBatVoltPos "ADC raw value of bat pos voltage";
CM_ SG_ 2651075585 SCU1_raw_TrayGndVolt "ADC raw value of gnd voltage";
CM_ SG_ 2651075585 SCU1_raw_TraySysVoltNeg "ADC raw value of Sys neg voltage";
CM_ SG_ 2651071489 SCU1_raw_TraySysVoltPos "ADC raw value of Sys pos voltage";
CM_ SG_ 2651091969 SCU1_raw_TrayTemp "ADC raw value of scu board temperature";
CM_ SG_ 2651091969 SCU1_raw_TrayVoltage "ADC raw value of scu tray voltage";
CM_ SG_ 2651104257 SCU1_raw_U1_BMSCAN "cell test voltage of cell 1";
CM_ SG_ 2651104257 SCU1_raw_Watchdog_Alarm_bit_0 "watchdog alarm bit of external watchdog";
CM_ SG_ 2651104257 SCU1_raw_Watchdog_Alarm_bit_1 "watchdog alarm bit of internal watchdog";
CM_ SG_ 2651083777 SCU1_raw_eStopLoopCurr "ADC raw value of eStopLoop Current";
CM_ SG_ 2451055617 SCU1_req_HSOutput1_pct "Highside-Switch-Output 1  Request";
CM_ SG_ 2451055617 SCU1_req_HSOutput2_pct "Highside-Switch-Output 2  Request";
CM_ SG_ 2451055617 SCU1_req_HSOutput3_pct "Highside-Switch-Output 3  Request";
CM_ SG_ 2451055617 SCU1_req_HSOutput4_pct "Highside-Switch-Output 4  Request";
CM_ SG_ 2281706497 SCU1_stat_ART_BMSS_Restart "Restart of BMS-Slaves is performed";
CM_ SG_ 2281706497 SCU1_stat_ART_IsActive "Afterrun test is running";
CM_ SG_ 2281706497 SCU1_stat_ART_NoError "No Error While After Run Test";
CM_ SG_ 2281706497 SCU1_stat_ART_Started "Afterrun test started";
CM_ SG_ 2281706497 SCU1_stat_ConOnProtect "contactor protection flag after contactor drop-out";
CM_ SG_ 2281706497 SCU1_stat_Config "SCU is beeing configured";
CM_ SG_ 2281706497 SCU1_stat_Diag "SCU is in diagnostic mode";
CM_ SG_ 2281706497 SCU1_stat_Error "SCU has encountered an error";
CM_ SG_ 2281706497 SCU1_stat_Init "initialisation of SCU components";
CM_ SG_ 2281706497 SCU1_stat_LimpHome "limp home modus with limited functionallity";
CM_ SG_ 2281706497 SCU1_stat_Run "selftests are finished";
CM_ SG_ 2281706497 SCU1_stat_Shutdown "KL15 is off, SCU shutdown started";
CM_ SG_ 2449523713 SCU1_wf_BoardTemp "ECU/IC board temperature too high/low";
CM_ SG_ 2449523713 SCU1_wf_ContDam "contactors damaged";
CM_ SG_ 2449523713 SCU1_wf_ContactorDropOut "a contactor drop out occured";
CM_ SG_ 2449523713 SCU1_wf_ContactorWrongState "tbd";
CM_ SG_ 2449523713 SCU1_wf_CurrSens "i sensor error occurred";
CM_ SG_ 2449523713 SCU1_wf_InvalidData "short circuit or open temperature sensor";
CM_ SG_ 2449523713 SCU1_wf_KL30SafeMax "KL30-Safe max";
CM_ SG_ 2449523713 SCU1_wf_KL30SafeMin "KL30-Safe min";
CM_ SG_ 2449523713 SCU1_wf_KL30SafeOff "BMS-M-SafePwr was switched off (HW detection)";
CM_ SG_ 2449523713 SCU1_wf_RefVoltErrorMax "refernce voltage to high";
CM_ SG_ 2449523713 SCU1_wf_RefVoltErrorMin "refernce voltage to low";
CM_ SG_ 2415922177 T001_act_T_CellTemp_C "active cell temperature";
CM_ SG_ 2415922178 T002_act_T_CellTemp_C "active cell temperature";
CM_ SG_ 2415922179 T003_act_T_CellTemp_C "active cell temperature";
CM_ SG_ 2415922180 T004_act_T_CellTemp_C "active cell temperature";
CM_ SG_ 2415922181 T005_act_T_CellTemp_C "active cell temperature";
CM_ SG_ 2415922182 T006_act_T_CellTemp_C "active cell temperature";
CM_ SG_ 2415922183 T007_act_T_CellTemp_C "active cell temperature";
CM_ SG_ 2415922184 T008_act_T_CellTemp_C "active cell temperature";
CM_ SG_ 2415922185 T009_act_T_CellTemp_C "active cell temperature";
CM_ SG_ 2415922186 T010_act_T_CellTemp_C "active cell temperature";
CM_ SG_ 2415922187 T011_act_T_CellTemp_C "active cell temperature";
CM_ SG_ 2415922188 T012_act_T_CellTemp_C "active cell temperature";
CM_ SG_ 2415922189 T013_act_T_CellTemp_C "active cell temperature";
CM_ SG_ 2415922190 T014_act_T_CellTemp_C "active cell temperature";
CM_ SG_ 2415922191 T015_act_T_CellTemp_C "active cell temperature";
CM_ SG_ 2415922192 T016_act_T_CellTemp_C "active cell temperature";
CM_ SG_ 2415922193 T017_act_T_CellTemp_C "active cell temperature";
CM_ SG_ 2415922194 T018_act_T_CellTemp_C "active cell temperature";
CM_ SG_ 2415922195 T019_act_T_CellTemp_C "active cell temperature";
CM_ SG_ 2415922196 T020_act_T_CellTemp_C "active cell temperature";
CM_ SG_ 2415922177 V001_act_U_CellVoltage_mV "active cell voltage";
CM_ SG_ 2415922177 V001_act_U_GPIOVoltage_mV "only EOL: GPIO voltage to corresponding cell temperature";
CM_ SG_ 2415922178 V002_act_U_CellVoltage_mV "active cell voltage";
CM_ SG_ 2415922178 V002_act_U_GPIOVoltage_mV "only EOL: GPIO voltage to corresponding cell temperature";
CM_ SG_ 2415922179 V003_act_U_CellVoltage_mV "active cell voltage";
CM_ SG_ 2415922179 V003_act_U_GPIOVoltage_mV "only EOL: GPIO voltage to corresponding cell temperature";
CM_ SG_ 2415922180 V004_act_U_CellVoltage_mV "active cell voltage";
CM_ SG_ 2415922180 V004_act_U_GPIOVoltage_mV "only EOL: GPIO voltage to corresponding cell temperature";
CM_ SG_ 2415922181 V005_act_U_CellVoltage_mV "active cell voltage";
CM_ SG_ 2415922181 V005_act_U_GPIOVoltage_mV "only EOL: GPIO voltage to corresponding cell temperature";
CM_ SG_ 2415922182 V006_act_U_CellVoltage_mV "active cell voltage";
CM_ SG_ 2415922182 V006_act_U_GPIOVoltage_mV "only EOL: GPIO voltage to corresponding cell temperature";
CM_ SG_ 2415922183 V007_act_U_CellVoltage_mV "active cell voltage";
CM_ SG_ 2415922183 V007_act_U_GPIOVoltage_mV "only EOL: GPIO voltage to corresponding cell temperature";
CM_ SG_ 2415922184 V008_act_U_CellVoltage_mV "active cell voltage";
CM_ SG_ 2415922184 V008_act_U_GPIOVoltage_mV "only EOL: GPIO voltage to corresponding cell temperature";
CM_ SG_ 2415922185 V009_act_U_CellVoltage_mV "active cell voltage";
CM_ SG_ 2415922185 V009_act_U_GPIOVoltage_mV "only EOL: GPIO voltage to corresponding cell temperature";
CM_ SG_ 2415922186 V010_act_U_CellVoltage_mV "active cell voltage";
CM_ SG_ 2415922186 V010_act_U_GPIOVoltage_mV "only EOL: GPIO voltage to corresponding cell temperature";
CM_ SG_ 2415922187 V011_act_U_CellVoltage_mV "active cell voltage";
CM_ SG_ 2415922187 V011_act_U_GPIOVoltage_mV "only EOL: GPIO voltage to corresponding cell temperature";
CM_ SG_ 2415922188 V012_act_U_CellVoltage_mV "active cell voltage";
CM_ SG_ 2415922188 V012_act_U_GPIOVoltage_mV "only EOL: GPIO voltage to corresponding cell temperature";
CM_ SG_ 2415922189 V013_act_U_CellVoltage_mV "active cell voltage";
CM_ SG_ 2415922189 V013_act_U_GPIOVoltage_mV "only EOL: GPIO voltage to corresponding cell temperature";
CM_ SG_ 2415922190 V014_act_U_CellVoltage_mV "active cell voltage";
CM_ SG_ 2415922190 V014_act_U_GPIOVoltage_mV "only EOL: GPIO voltage to corresponding cell temperature";
CM_ SG_ 2415922191 V015_act_U_CellVoltage_mV "active cell voltage";
CM_ SG_ 2415922191 V015_act_U_GPIOVoltage_mV "only EOL: GPIO voltage to corresponding cell temperature";
CM_ SG_ 2415922192 V016_act_U_CellVoltage_mV "active cell voltage";
CM_ SG_ 2415922192 V016_act_U_GPIOVoltage_mV "only EOL: GPIO voltage to corresponding cell temperature";
CM_ SG_ 2415922193 V017_act_U_CellVoltage_mV "active cell voltage";
CM_ SG_ 2415922193 V017_act_U_GPIOVoltage_mV "only EOL: GPIO voltage to corresponding cell temperature";
CM_ SG_ 2415922194 V018_act_U_CellVoltage_mV "active cell voltage";
CM_ SG_ 2415922194 V018_act_U_GPIOVoltage_mV "only EOL: GPIO voltage to corresponding cell temperature";
CM_ SG_ 2415922195 V019_act_U_CellVoltage_mV "active cell voltage";
CM_ SG_ 2415922195 V019_act_U_GPIOVoltage_mV "only EOL: GPIO voltage to corresponding cell temperature";
CM_ SG_ 2415922196 V020_act_U_CellVoltage_mV "active cell voltage";
CM_ SG_ 2415922196 V020_act_U_GPIOVoltage_mV "only EOL: GPIO voltage to corresponding cell temperature";
BA_DEF_ "DBName" STRING;
BA_DEF_ "BusType" STRING;
BA_DEF_ BO_ "VFrameFormat" ENUM "StandardCAN","ExtendedCAN","reserved","J1939PG","reserved","reserved","reserved","reserved","reserved","reserved","reserved","reserved","reserved","reserved","StandardCAN_FD","ExtendedCAN_FD";
BA_DEF_ BO_ "GenMsgSendType" ENUM "Cyclic","Event","CyclicIfActive","SpontanWithDelay","CyclicAndSpontan","CyclicAndSpontanWithDelay";
BA_DEF_ BO_ "GenMsgCycleTime" INT 0 0;
BA_DEF_DEF_ "DBName" "Cluster";
BA_DEF_DEF_ "BusType" "CAN";
BA_DEF_DEF_ "VFrameFormat" "StandardCAN";
BA_DEF_DEF_ "GenMsgSendType" "Cyclic";
BA_DEF_DEF_ "GenMsgCycleTime" 0;
BA_ "VFrameFormat" BO_ 2316833792 1;
BA_ "GenMsgCycleTime" BO_ 2316833792 40;
BA_ "VFrameFormat" BO_ 2650877953 1;
BA_ "GenMsgSendType" BO_ 2650877953 1;
BA_ "VFrameFormat" BO_ 2650882049 1;
BA_ "GenMsgSendType" BO_ 2650882049 1;
BA_ "VFrameFormat" BO_ 2650886145 1;
BA_ "GenMsgSendType" BO_ 2650886145 1;
BA_ "VFrameFormat" BO_ 2650890241 1;
BA_ "GenMsgSendType" BO_ 2650890241 1;
BA_ "VFrameFormat" BO_ 2650894337 1;
BA_ "GenMsgSendType" BO_ 2650894337 1;
BA_ "VFrameFormat" BO_ 2650898433 1;
BA_ "GenMsgCycleTime" BO_ 2650898433 100;
BA_ "VFrameFormat" BO_ 2650902529 1;
BA_ "GenMsgSendType" BO_ 2650902529 1;
BA_ "VFrameFormat" BO_ 2650906625 1;
BA_ "GenMsgCycleTime" BO_ 2650906625 1000;
BA_ "VFrameFormat" BO_ 2650914817 1;
BA_ "GenMsgSendType" BO_ 2650914817 1;
BA_ "VFrameFormat" BO_ 2181563392 1;
BA_ "GenMsgCycleTime" BO_ 2181563392 2000;
BA_ "VFrameFormat" BO_ 2650828801 1;
BA_ "GenMsgSendType" BO_ 2650828801 1;
BA_ "VFrameFormat" BO_ 2650804225 1;
BA_ "GenMsgCycleTime" BO_ 2650804225 500;
BA_ "VFrameFormat" BO_ 2650800129 1;
BA_ "GenMsgSendType" BO_ 2650800129 1;
BA_ "VFrameFormat" BO_ 2650812417 1;
BA_ "GenMsgCycleTime" BO_ 2650812417 100;
BA_ "VFrameFormat" BO_ 2650824705 1;
BA_ "GenMsgSendType" BO_ 2650824705 1;
BA_ "VFrameFormat" BO_ 2650836993 1;
BA_ "GenMsgSendType" BO_ 2650836993 1;
BA_ "VFrameFormat" BO_ 2650820609 1;
BA_ "GenMsgSendType" BO_ 2650820609 1;
BA_ "VFrameFormat" BO_ 2650857473 1;
BA_ "GenMsgCycleTime" BO_ 2650857473 500;
BA_ "VFrameFormat" BO_ 2650816513 1;
BA_ "GenMsgSendType" BO_ 2650816513 1;
BA_ "VFrameFormat" BO_ 2650808321 1;
BA_ "GenMsgCycleTime" BO_ 2650808321 500;
BA_ "VFrameFormat" BO_ 2650832897 1;
BA_ "GenMsgSendType" BO_ 2650832897 1;
BA_ "VFrameFormat" BO_ 2650853377 1;
BA_ "GenMsgCycleTime" BO_ 2650853377 100;
BA_ "VFrameFormat" BO_ 2650861569 1;
BA_ "GenMsgCycleTime" BO_ 2650861569 100;
BA_ "VFrameFormat" BO_ 2650873857 1;
BA_ "GenMsgCycleTime" BO_ 2650873857 1000;
BA_ "VFrameFormat" BO_ 2650869761 1;
BA_ "GenMsgSendType" BO_ 2650869761 1;
BA_ "VFrameFormat" BO_ 2650841089 1;
BA_ "GenMsgSendType" BO_ 2650841089 1;
BA_ "VFrameFormat" BO_ 2650845185 1;
BA_ "GenMsgCycleTime" BO_ 2650845185 100;
BA_ "VFrameFormat" BO_ 2650849281 1;
BA_ "GenMsgCycleTime" BO_ 2650849281 100;
BA_ "VFrameFormat" BO_ 2650865665 1;
BA_ "GenMsgSendType" BO_ 2650865665 1;
BA_ "VFrameFormat" BO_ 2415922177 1;
BA_ "GenMsgCycleTime" BO_ 2415922177 1000;
BA_ "VFrameFormat" BO_ 2415922178 1;
BA_ "GenMsgCycleTime" BO_ 2415922178 1000;
BA_ "VFrameFormat" BO_ 2415922179 1;
BA_ "GenMsgCycleTime" BO_ 2415922179 1000;
BA_ "VFrameFormat" BO_ 2415922180 1;
BA_ "GenMsgCycleTime" BO_ 2415922180 1000;
BA_ "VFrameFormat" BO_ 2415922181 1;
BA_ "GenMsgCycleTime" BO_ 2415922181 1000;
BA_ "VFrameFormat" BO_ 2415922182 1;
BA_ "GenMsgCycleTime" BO_ 2415922182 1000;
BA_ "VFrameFormat" BO_ 2415922183 1;
BA_ "GenMsgCycleTime" BO_ 2415922183 1000;
BA_ "VFrameFormat" BO_ 2415922184 1;
BA_ "GenMsgCycleTime" BO_ 2415922184 1000;
BA_ "VFrameFormat" BO_ 2415922185 1;
BA_ "GenMsgCycleTime" BO_ 2415922185 1000;
BA_ "VFrameFormat" BO_ 2415922186 1;
BA_ "GenMsgCycleTime" BO_ 2415922186 1000;
BA_ "VFrameFormat" BO_ 2415922187 1;
BA_ "GenMsgCycleTime" BO_ 2415922187 1000;
BA_ "VFrameFormat" BO_ 2415922188 1;
BA_ "GenMsgCycleTime" BO_ 2415922188 1000;
BA_ "VFrameFormat" BO_ 2415922189 1;
BA_ "GenMsgCycleTime" BO_ 2415922189 1000;
BA_ "VFrameFormat" BO_ 2415922190 1;
BA_ "GenMsgCycleTime" BO_ 2415922190 1000;
BA_ "VFrameFormat" BO_ 2415922191 1;
BA_ "GenMsgCycleTime" BO_ 2415922191 1000;
BA_ "VFrameFormat" BO_ 2415922192 1;
BA_ "GenMsgCycleTime" BO_ 2415922192 1000;
BA_ "VFrameFormat" BO_ 2415922193 1;
BA_ "GenMsgCycleTime" BO_ 2415922193 1000;
BA_ "VFrameFormat" BO_ 2415922194 1;
BA_ "GenMsgCycleTime" BO_ 2415922194 1000;
BA_ "VFrameFormat" BO_ 2415922195 1;
BA_ "GenMsgCycleTime" BO_ 2415922195 1000;
BA_ "VFrameFormat" BO_ 2415922196 1;
BA_ "GenMsgCycleTime" BO_ 2415922196 1000;
BA_ "VFrameFormat" BO_ 2415941633 1;
BA_ "GenMsgCycleTime" BO_ 2415941633 1000;
BA_ "VFrameFormat" BO_ 2451052545 1;
BA_ "GenMsgSendType" BO_ 2451052545 1;
BA_ "VFrameFormat" BO_ 2550716417 1;
BA_ "GenMsgSendType" BO_ 2550716417 1;
BA_ "VFrameFormat" BO_ 2415949825 1;
BA_ "GenMsgCycleTime" BO_ 2415949825 1000;
BA_ "VFrameFormat" BO_ 2415962113 1;
BA_ "GenMsgCycleTime" BO_ 2415962113 1000;
BA_ "VFrameFormat" BO_ 2415970305 1;
BA_ "GenMsgCycleTime" BO_ 2415970305 1000;
BA_ "VFrameFormat" BO_ 2415958017 1;
BA_ "GenMsgCycleTime" BO_ 2415958017 1000;
BA_ "VFrameFormat" BO_ 2415953921 1;
BA_ "GenMsgCycleTime" BO_ 2415953921 1000;
BA_ "VFrameFormat" BO_ 2415966209 1;
BA_ "GenMsgCycleTime" BO_ 2415966209 1000;
BA_ "VFrameFormat" BO_ 2415933441 1;
BA_ "GenMsgCycleTime" BO_ 2415933441 1000;
BA_ "VFrameFormat" BO_ 2415937537 1;
BA_ "GenMsgCycleTime" BO_ 2415937537 1000;
BA_ "VFrameFormat" BO_ 2415986689 1;
BA_ "GenMsgCycleTime" BO_ 2415986689 1000;
BA_ "VFrameFormat" BO_ 2415929345 1;
BA_ "GenMsgCycleTime" BO_ 2415929345 1000;
BA_ "VFrameFormat" BO_ 2415974401 1;
BA_ "GenMsgCycleTime" BO_ 2415974401 1000;
BA_ "VFrameFormat" BO_ 2415982593 1;
BA_ "GenMsgCycleTime" BO_ 2415982593 1000;
BA_ "VFrameFormat" BO_ 2415945729 1;
BA_ "GenMsgCycleTime" BO_ 2415945729 1000;
BA_ "VFrameFormat" BO_ 2416478209 1;
BA_ "GenMsgSendType" BO_ 2416478209 1;
BA_ "VFrameFormat" BO_ 2415925249 1;
BA_ "GenMsgCycleTime" BO_ 2415925249 1000;
BA_ "VFrameFormat" BO_ 2415978497 1;
BA_ "GenMsgCycleTime" BO_ 2415978497 1000;
BA_ "VFrameFormat" BO_ 2416474113 1;
BA_ "GenMsgCycleTime" BO_ 2416474113 1000;
BA_ "VFrameFormat" BO_ 2449544193 1;
BA_ "GenMsgCycleTime" BO_ 2449544193 1000;
BA_ "VFrameFormat" BO_ 2449527809 1;
BA_ "GenMsgCycleTime" BO_ 2449527809 100;
BA_ "VFrameFormat" BO_ 2449568769 1;
BA_ "GenMsgCycleTime" BO_ 2449568769 1000;
BA_ "VFrameFormat" BO_ 2315318273 1;
BA_ "GenMsgCycleTime" BO_ 2315318273 100;
BA_ "VFrameFormat" BO_ 2315314177 1;
BA_ "GenMsgCycleTime" BO_ 2315314177 100;
BA_ "VFrameFormat" BO_ 2449585153 1;
BA_ "GenMsgSendType" BO_ 2449585153 1;
BA_ "VFrameFormat" BO_ 2449589249 1;
BA_ "GenMsgSendType" BO_ 2449589249 1;
BA_ "VFrameFormat" BO_ 2449490945 1;
BA_ "GenMsgCycleTime" BO_ 2449490945 100;
BA_ "VFrameFormat" BO_ 2315342849 1;
BA_ "GenMsgCycleTime" BO_ 2315342849 100;
BA_ "VFrameFormat" BO_ 2315277313 1;
BA_ "GenMsgCycleTime" BO_ 2315277313 100;
BA_ "VFrameFormat" BO_ 2449519617 1;
BA_ "GenMsgCycleTime" BO_ 2449519617 100;
BA_ "VFrameFormat" BO_ 2451055617 1;
BA_ "GenMsgSendType" BO_ 2451055617 1;
BA_ "VFrameFormat" BO_ 2449486849 1;
BA_ "GenMsgCycleTime" BO_ 2449486849 100;
BA_ "VFrameFormat" BO_ 2449482753 1;
BA_ "GenMsgCycleTime" BO_ 2449482753 100;
BA_ "VFrameFormat" BO_ 2449576961 1;
BA_ "GenMsgCycleTime" BO_ 2449576961 1000;
BA_ "VFrameFormat" BO_ 2449593345 1;
BA_ "GenMsgSendType" BO_ 2449593345 1;
BA_ "VFrameFormat" BO_ 2449515521 1;
BA_ "GenMsgCycleTime" BO_ 2449515521 100;
BA_ "VFrameFormat" BO_ 2449552385 1;
BA_ "GenMsgCycleTime" BO_ 2449552385 1000;
BA_ "VFrameFormat" BO_ 2449536001 1;
BA_ "GenMsgCycleTime" BO_ 2449536001 100;
BA_ "VFrameFormat" BO_ 2449503233 1;
BA_ "GenMsgCycleTime" BO_ 2449503233 100;
BA_ "VFrameFormat" BO_ 2449564673 1;
BA_ "GenMsgCycleTime" BO_ 2449564673 1000;
BA_ "VFrameFormat" BO_ 2651063297 1;
BA_ "GenMsgCycleTime" BO_ 2651063297 1000;
BA_ "VFrameFormat" BO_ 2651067393 1;
BA_ "GenMsgCycleTime" BO_ 2651067393 1000;
BA_ "VFrameFormat" BO_ 2651104257 1;
BA_ "GenMsgCycleTime" BO_ 2651104257 1000;
BA_ "VFrameFormat" BO_ 2651071489 1;
BA_ "GenMsgCycleTime" BO_ 2651071489 1000;
BA_ "VFrameFormat" BO_ 2651075585 1;
BA_ "GenMsgCycleTime" BO_ 2651075585 1000;
BA_ "VFrameFormat" BO_ 2651079681 1;
BA_ "GenMsgCycleTime" BO_ 2651079681 1000;
BA_ "VFrameFormat" BO_ 2651083777 1;
BA_ "GenMsgCycleTime" BO_ 2651083777 1000;
BA_ "VFrameFormat" BO_ 2651087873 1;
BA_ "GenMsgCycleTime" BO_ 2651087873 1000;
BA_ "VFrameFormat" BO_ 2651091969 1;
BA_ "GenMsgCycleTime" BO_ 2651091969 1000;
BA_ "VFrameFormat" BO_ 2651096065 1;
BA_ "GenMsgCycleTime" BO_ 2651096065 1000;
BA_ "VFrameFormat" BO_ 2651100161 1;
BA_ "GenMsgCycleTime" BO_ 2651100161 1000;
BA_ "VFrameFormat" BO_ 2449597441 1;
BA_ "GenMsgCycleTime" BO_ 2449597441 100;
BA_ "VFrameFormat" BO_ 2449540097 1;
BA_ "GenMsgCycleTime" BO_ 2449540097 1000;
BA_ "VFrameFormat" BO_ 2449499137 1;
BA_ "GenMsgCycleTime" BO_ 2449499137 1000;
BA_ "VFrameFormat" BO_ 2281706497 1;
BA_ "GenMsgCycleTime" BO_ 2281706497 40;
BA_ "VFrameFormat" BO_ 2449548289 1;
BA_ "GenMsgCycleTime" BO_ 2449548289 1000;
BA_ "VFrameFormat" BO_ 2449556481 1;
BA_ "GenMsgCycleTime" BO_ 2449556481 1000;
BA_ "VFrameFormat" BO_ 2449523713 1;
BA_ "GenMsgCycleTime" BO_ 2449523713 100;
BA_ "VFrameFormat" BO_ 2583725057 1;
BA_ "GenMsgCycleTime" BO_ 2583725057 100;
BA_ "VFrameFormat" BO_ 2449511425 1;
BA_ "GenMsgCycleTime" BO_ 2449511425 100;
